VERSION "V5.0.0"

NS_ :

BS_:

BU_: SGW_SG CGW_SG

BO_ 643 DCM_FR: 8 CGW_SG
 SG_ DCM_FR_CarSharingColorSts  : 7|8@0+ (1,0) [0|255] "" SGW_SG
 SG_ DCM_FR_CarSharingTimeSts  : 11|4@0+ (1,0) [0|9] "s" SGW_SG
 SG_ DCM_FR_PowerDoorModeSts  : 13|2@0+ (1,0) [0|3] "" SGW_SG
 SG_ DCM_FR_FrontKeepOpenSts  : 14|1@0+ (1,0) [0|1] "" SGW_SG
 SG_ DCM_FR_PriorSoundSts  : 15|1@0+ (1,0) [0|1] "" SGW_SG
 SG_ DCM_FR_CarSharingLightSts  : 46|1@0+ (1,0) [0|1] "" SGW_SG
 SG_ DCM_FR_WelcomeOnOffSts  : 47|1@0+ (1,0) [0|1] "" SGW_SG
 SG_ DCM_FR_DoorFRLockSts  : 23|1@0+ (1,0) [0|1] "" SGW_SG
 SG_ DCM_FR_DoorFRAngle  : 22|7@0+ (1,0) [0|100] "degrees" SGW_SG
 SG_ DCM_FR_FRPESwitchReq  : 31|1@0+ (1,0) [0|1] "" SGW_SG
 SG_ DCM_FR_DoorAntiPinchSts  : 30|1@0+ (1,0) [0|1] "" SGW_SG
 SG_ DCM_FR_DoorObstacleSts  : 29|1@0+ (1,0) [0|1] "" SGW_SG
 SG_ DCM_FR_ElectricDoorMovementSts  : 28|3@0+ (1,0) [0|7] "" SGW_SG
 SG_ DCM_FR_LinkageAvoidanceReq  : 25|2@0+ (1,0) [0|3] "" SGW_SG
 SG_ DCM_FR_InsideSwitchReq  : 39|1@0+ (1,0) [0|1] "" SGW_SG
 SG_ DCM_FR_WindowSts  : 38|3@0+ (1,0) [0|5] "" SGW_SG
 SG_ DCM_FR_PWM_POS_STS  : 35|3@0+ (1,0) [0|4] "" SGW_SG
 SG_ DCM_FR_GLASS_LOCATION  : 45|5@0+ (1,0) [0|20] "" SGW_SG
 SG_ DCM_FR_FrontDoorAngleFeedback  : 40|1@0+ (1,0) [0|1] "" SGW_SG
 SG_ DCM_FR_FRWindowLockSts  : 55|1@0+ (1,0) [0|1] "" SGW_SG
 SG_ DCM_FR_DoorFRSts  : 54|1@0+ (1,0) [0|1] "" SGW_SG

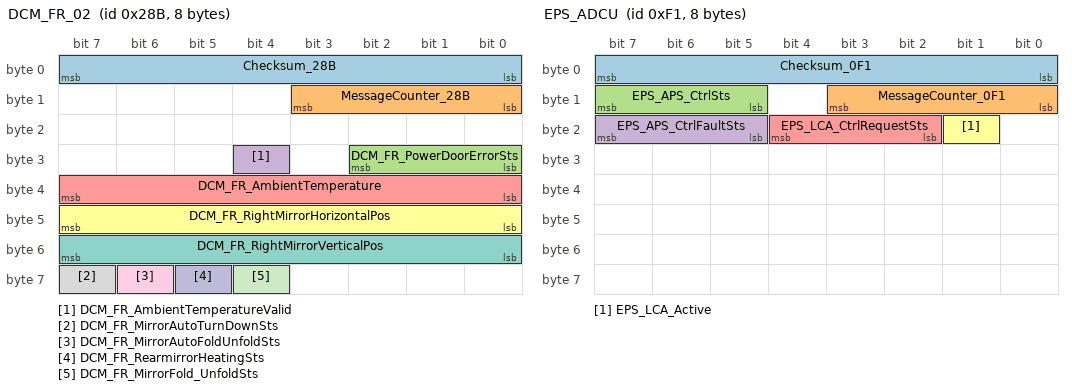
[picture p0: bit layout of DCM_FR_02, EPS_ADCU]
BO_ 651 DCM_FR_02: 8 CGW_SG
 SG_ Checksum_28B  : 7|8@0+ (1,0) [0|255] "" SGW_SG
 SG_ MessageCounter_28B  : 11|4@0+ (1,0) [0|15] "" SGW_SG
 SG_ DCM_FR_PowerDoorErrorSts  : 26|3@0+ (1,0) [0|7] "" SGW_SG
 SG_ DCM_FR_AmbientTemperatureValid  : 28|1@0+ (1,0) [0|1] "" SGW_SG
 SG_ DCM_FR_AmbientTemperature  : 39|8@0+ (1,-50) [-50|205] "celsius" SGW_SG
 SG_ DCM_FR_RightMirrorHorizontalPos  : 47|8@0+ (1,0) [0|100] "percent" SGW_SG
 SG_ DCM_FR_RightMirrorVerticalPos  : 55|8@0+ (1,0) [0|100] "percent" SGW_SG
 SG_ DCM_FR_MirrorAutoTurnDownSts  : 63|1@0+ (1,0) [0|1] "" SGW_SG
 SG_ DCM_FR_MirrorAutoFoldUnfoldSts  : 62|1@0+ (1,0) [0|1] "" SGW_SG
 SG_ DCM_FR_RearmirrorHeatingSts  : 61|1@0+ (1,0) [0|1] "" SGW_SG
 SG_ DCM_FR_MirrorFold_UnfoldSts  : 60|1@0+ (1,0) [0|1] "" SGW_SG

BO_ 653 DCM_FR_03: 8 CGW_SG
 SG_ DCM_FR_MirrorTiltVerticalPos  : 23|8@0+ (1,0) [0|100] "percent" SGW_SG
 SG_ DCM_FR_MirrorTiltHorizontalPos  : 31|8@0+ (1,0) [0|100] "percent" SGW_SG
 SG_ DCM_FR_MirrorMainVerticalPos  : 39|8@0+ (1,0) [0|100] "percent" SGW_SG
 SG_ DCM_FR_MirrorMainHorizontalPos  : 47|8@0+ (1,0) [0|100] "percent" SGW_SG

BO_ 310 DCM_FR_04: 8 CGW_SG
 SG_ DCM_FR_MirrorAdjustmentSts  : 7|1@0+ (1,0) [0|1] "" SGW_SG
 SG_ DCM_FR_MirrorFoldFaultSts  : 6|2@0+ (1,0) [0|3] "" SGW_SG
 SG_ DCM_FR_HandleFailReminder  : 4|2@0+ (1,0) [0|3] "" SGW_SG
 SG_ DCM_FR_PriorSoundReq  : 2|2@0+ (1,0) [0|1] "" SGW_SG

BO_ 644 DCM_RL: 8 CGW_SG
 SG_ Checksum_284  : 7|8@0+ (1,0) [0|255] "" SGW_SG
 SG_ MessageCounter_284  : 11|4@0+ (1,0) [0|15] "" SGW_SG
 SG_ DCM_RL_DoorRLLockSts  : 23|1@0+ (1,0) [0|1] "" SGW_SG
 SG_ DCM_RL_DoorRLAngle  : 22|7@0+ (1,0) [0|100] "degrees" SGW_SG
 SG_ DCM_RL_RLPESwitchReq  : 31|1@0+ (1,0) [0|1] "" SGW_SG
 SG_ DCM_RL_DoorObstacleSts  : 30|1@0+ (1,0) [0|1] "" SGW_SG
 SG_ DCM_RL_DoorAntiPinchSts  : 29|1@0+ (1,0) [0|1] "" SGW_SG
 SG_ DCM_RL_ElectricDoorMovementSts  : 28|3@0+ (1,0) [0|7] "" SGW_SG
 SG_ DCM_RL_LinkageAvoidanceReq  : 25|2@0+ (1,0) [0|3] "" SGW_SG
 SG_ DCM_RL_InsideSwitchReq  : 39|1@0+ (1,0) [0|1] "" SGW_SG
 SG_ DCM_RL_WindowSts  : 38|3@0+ (1,0) [0|5] "" SGW_SG
 SG_ DCM_RL_PWM_POS_STS  : 35|3@0+ (1,0) [0|4] "" SGW_SG
 SG_ DCM_RL_GLASS_LOCATION  : 45|5@0+ (1,0) [0|20] "" SGW_SG
 SG_ DCM_RL_RearDoorAngleFeedback  : 40|1@0+ (1,0) [0|1] "" SGW_SG
 SG_ DCM_RL_RLWindowLockSts  : 55|1@0+ (1,0) [0|1] "" SGW_SG
 SG_ DCM_RL_DoorRLSts  : 54|1@0+ (1,0) [0|1] "" SGW_SG
 SG_ DCM_RL_PowerDoorErrorSts  : 53|3@0+ (1,0) [0|7] "" SGW_SG
 SG_ DCM_RL_PriorSoundSts  : 50|1@0+ (1,0) [0|1] "" SGW_SG
 SG_ DCM_RL_PowerDoorModeSts  : 49|2@0+ (1,0) [0|3] "" SGW_SG
 SG_ DCM_RL_WelcomeOnOffSts  : 47|1@0+ (1,0) [0|1] "" SGW_SG
 SG_ DCM_RL_CarSharingLightSts  : 46|1@0+ (1,0) [0|1] "" SGW_SG
 SG_ DCM_RL_CarSharingColorSts  : 63|8@0+ (1,0) [0|255] "" SGW_SG
 SG_ DCM_RL_CarSharingTimeSts  : 15|4@0+ (1,0) [0|9] "s" SGW_SG

BO_ 311 DCM_RL_02: 8 CGW_SG
 SG_ DCM_RL_PriorSoundReq  : 7|1@0+ (1,0) [0|1] "" SGW_SG

BO_ 645 DCM_RR: 8 CGW_SG
 SG_ Checksum_285  : 7|8@0+ (1,0) [0|255] "" SGW_SG
 SG_ MessageCounter_285  : 11|4@0+ (1,0) [0|15] "" SGW_SG
 SG_ DCM_RR_DoorRRLockSts  : 23|1@0+ (1,0) [0|1] "" SGW_SG
 SG_ DCM_RR_DoorRRAngle  : 22|7@0+ (1,0) [0|100] "degrees" SGW_SG
 SG_ DCM_RR_RRPESwitchReq  : 31|1@0+ (1,0) [0|1] "" SGW_SG
 SG_ DCM_RR_DoorObstacleSts  : 30|1@0+ (1,0) [0|1] "" SGW_SG
 SG_ DCM_RR_DoorAntiPinchSts  : 29|1@0+ (1,0) [0|1] "" SGW_SG
 SG_ DCM_RR_ElectricDoorMovementSts  : 28|3@0+ (1,0) [0|7] "" SGW_SG
 SG_ DCM_RR_LinkageAvoidanceReq  : 25|2@0+ (1,0) [0|3] "" SGW_SG
 SG_ DCM_RR_InsideSwitchReq  : 39|1@0+ (1,0) [0|1] "" SGW_SG
 SG_ DCM_RR_WindowSts  : 38|3@0+ (1,0) [0|5] "" SGW_SG
 SG_ DCM_RR_PWM_POS_STS  : 35|3@0+ (1,0) [0|4] "" SGW_SG
 SG_ DCM_RR_GLASS_LOCATION  : 45|5@0+ (1,0) [0|20] "" SGW_SG
 SG_ DCM_RR_RearDoorAngleFeedback  : 40|1@0+ (1,0) [0|1] "" SGW_SG
 SG_ DCM_RR_RRWindowLockSts  : 55|1@0+ (1,0) [0|1] "" SGW_SG
 SG_ DCM_RR_DoorRRSts  : 54|1@0+ (1,0) [0|1] "" SGW_SG
 SG_ DCM_RR_PowerDoorErrorSts  : 53|3@0+ (1,0) [0|7] "" SGW_SG
 SG_ DCM_RR_PriorSoundSts  : 50|1@0+ (1,0) [0|1] "" SGW_SG
 SG_ DCM_RR_PowerDoorModeSts  : 49|2@0+ (1,0) [0|3] "" SGW_SG
 SG_ DCM_RR_WelcomeOnOffSts  : 47|1@0+ (1,0) [0|1] "" SGW_SG
 SG_ DCM_RR_CarSharingLightSts  : 46|1@0+ (1,0) [0|1] "" SGW_SG
 SG_ DCM_RR_CarSharingColorSts  : 63|8@0+ (1,0) [0|255] "" SGW_SG
 SG_ DCM_RR_CarSharingTimeSts  : 15|4@0+ (1,0) [0|9] "s" SGW_SG

BO_ 312 DCM_RR_02: 8 CGW_SG
 SG_ DCM_RR_PriorSoundReq  : 7|1@0+ (1,0) [0|1] "" SGW_SG

BO_ 880 DCM_FL_SDS_01: 8 CGW_SG
 SG_ DCM_SDS_FL_SensorWorksts  : 15|3@0+ (1,0) [0|5] "" SGW_SG

BO_ 881 DCM_FR_SDS_01: 8 CGW_SG
 SG_ DCM_SDS_FR_SensorWorksts  : 15|3@0+ (1,0) [0|5] "" SGW_SG

BO_ 882 DCM_RL_SDS_01: 8 CGW_SG
 SG_ DCM_SDS_RL_SensorWorksts  : 15|3@0+ (1,0) [0|5] "" SGW_SG

BO_ 883 DCM_RR_SDS_01: 8 CGW_SG
 SG_ DCM_SDS_RR_SensorWorksts  : 15|3@0+ (1,0) [0|5] "" SGW_SG

BO_ 714 DIM_01: 8 CGW_SG
 SG_ DIM_ScreenBrightnessSta  : 7|5@0+ (1,0) [0|31] "" SGW_SG
 SG_ DIM_AutoScreenBacklightSta  : 15|2@0+ (1,0) [0|3] "" SGW_SG
 SG_ DIM_FaultState  : 13|2@0+ (1,0) [0|3] "" SGW_SG
 SG_ DIM_ONOFFSts  : 11|2@0+ (1,0) [0|3] "" SGW_SG

BO_ 512 ERA_01: 8 SGW_SG
 SG_ ERA_ECallSts  : 7|2@0+ (1,0) [0|3] "" CGW_SG
 SG_ ERA_TestModeSts  : 5|2@0+ (1,0) [0|3] "" CGW_SG
 SG_ ERA_SelfTestSts  : 3|1@0+ (1,0) [0|1] "" CGW_SG

BO_ 241 EPS_ADCU: 8 CGW_SG
 SG_ Checksum_0F1  : 7|8@0+ (1,0) [0|255] "" SGW_SG
 SG_ MessageCounter_0F1  : 11|4@0+ (1,0) [0|15] "" SGW_SG
 SG_ EPS_APS_CtrlSts  : 15|3@0+ (1,0) [0|7] "" SGW_SG
 SG_ EPS_APS_CtrlFaultSts  : 23|3@0+ (1,0) [0|7] "" SGW_SG
 SG_ EPS_LCA_CtrlRequestSts  : 20|3@0+ (1,0) [0|7] "" SGW_SG
 SG_ EPS_LCA_Active  : 17|1@0+ (1,0) [0|1] "" SGW_SG

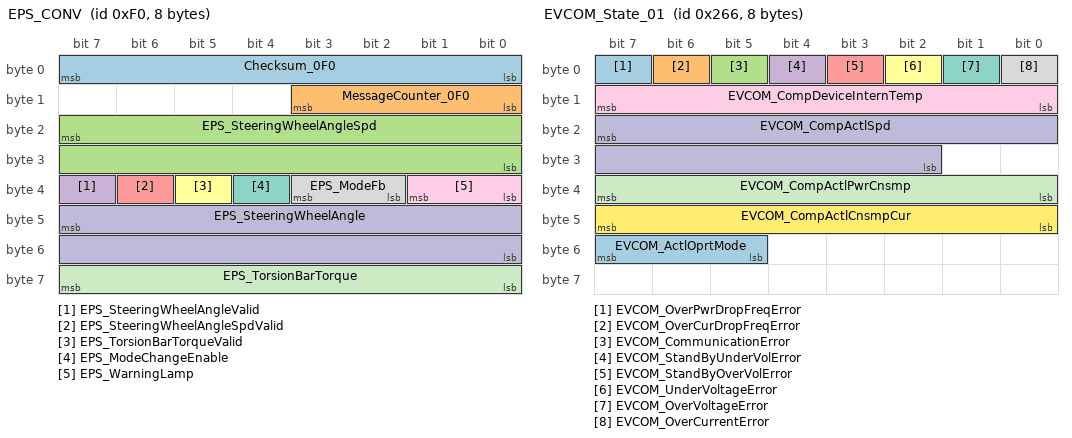
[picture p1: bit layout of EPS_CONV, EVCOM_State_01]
BO_ 240 EPS_CONV: 8 CGW_SG
 SG_ Checksum_0F0  : 7|8@0+ (1,0) [0|255] "" SGW_SG
 SG_ MessageCounter_0F0  : 11|4@0+ (1,0) [0|15] "" SGW_SG
 SG_ EPS_SteeringWheelAngleSpd  : 23|16@0+ (0.1,-540) [-540|540] "degrees/s" SGW_SG
 SG_ EPS_SteeringWheelAngleValid  : 39|1@0+ (1,0) [0|1] "" SGW_SG
 SG_ EPS_SteeringWheelAngleSpdValid  : 38|1@0+ (1,0) [0|1] "" SGW_SG
 SG_ EPS_TorsionBarTorqueValid  : 37|1@0+ (1,0) [0|1] "" SGW_SG
 SG_ EPS_ModeChangeEnable  : 36|1@0+ (1,0) [0|1] "" SGW_SG
 SG_ EPS_ModeFb  : 35|2@0+ (1,0) [0|3] "" SGW_SG
 SG_ EPS_WarningLamp  : 33|2@0+ (1,0) [0|3] "" SGW_SG
 SG_ EPS_SteeringWheelAngle  : 47|16@0+ (0.1,-780) [-780|780] "degrees" SGW_SG
 SG_ EPS_TorsionBarTorque  : 63|8@0+ (0.1,-10) [-10|10] "Nm" SGW_SG

BO_ 614 EVCOM_State_01: 8 CGW_SG
 SG_ EVCOM_OverPwrDropFreqError  : 7|1@0+ (1,0) [0|1] "" SGW_SG
 SG_ EVCOM_OverCurDropFreqError  : 6|1@0+ (1,0) [0|1] "" SGW_SG
 SG_ EVCOM_CommunicationError  : 5|1@0+ (1,0) [0|1] "" SGW_SG
 SG_ EVCOM_StandByUnderVolError  : 4|1@0+ (1,0) [0|1] "" SGW_SG
 SG_ EVCOM_StandByOverVolError  : 3|1@0+ (1,0) [0|1] "" SGW_SG
 SG_ EVCOM_UnderVoltageError  : 2|1@0+ (1,0) [0|1] "" SGW_SG
 SG_ EVCOM_OverVoltageError  : 1|1@0+ (1,0) [0|1] "" SGW_SG
 SG_ EVCOM_OverCurrentError  : 0|1@0+ (1,0) [0|1] "" SGW_SG
 SG_ EVCOM_CompDeviceInternTemp  : 15|8@0+ (1,-40) [-40|215] "celsius" SGW_SG
 SG_ EVCOM_CompActlSpd  : 23|14@0+ (1,0) [0|9200] "rpm" SGW_SG
 SG_ EVCOM_CompActlPwrCnsmp  : 39|8@0+ (0.04,0) [0|10.2] "KW" SGW_SG
 SG_ EVCOM_CompActlCnsmpCur  : 47|8@0+ (0.2,0) [0|51] "A" SGW_SG
 SG_ EVCOM_ActlOprtMode  : 55|3@0+ (1,0) [0|7] "" SGW_SG

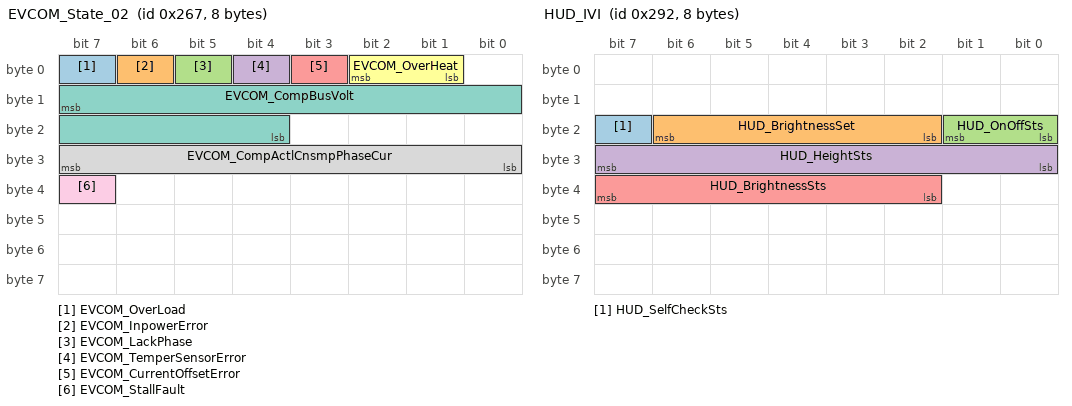
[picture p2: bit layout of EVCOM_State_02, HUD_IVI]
BO_ 615 EVCOM_State_02: 8 CGW_SG
 SG_ EVCOM_OverLoad  : 7|1@0+ (1,0) [0|1] "" SGW_SG
 SG_ EVCOM_InpowerError  : 6|1@0+ (1,0) [0|1] "" SGW_SG
 SG_ EVCOM_LackPhase  : 5|1@0+ (1,0) [0|1] "" SGW_SG
 SG_ EVCOM_TemperSensorError  : 4|1@0+ (1,0) [0|1] "" SGW_SG
 SG_ EVCOM_CurrentOffsetError  : 3|1@0+ (1,0) [0|1] "" SGW_SG
 SG_ EVCOM_OverHeat  : 2|2@0+ (1,0) [0|3] "" SGW_SG
 SG_ EVCOM_CompBusVolt  : 15|12@0+ (2,0) [0|1022] "V" SGW_SG
 SG_ EVCOM_CompActlCnsmpPhaseCur  : 31|8@0+ (0.2,0) [0|51] "A" SGW_SG
 SG_ EVCOM_StallFault  : 39|1@0+ (1,0) [0|1] "" SGW_SG

BO_ 640 HLL: 8 CGW_SG
 SG_ Checksum_280  : 7|8@0+ (1,0) [0|255] "" SGW_SG
 SG_ MessageCounter_280  : 11|4@0+ (1,0) [0|15] "" SGW_SG
 SG_ HLL_HeadlampFault  : 19|1@0+ (1,0) [0|1] "" SGW_SG
 SG_ HLL_DRLFaultSts  : 16|1@0+ (1,0) [0|1] "" SGW_SG

BO_ 641 HLR: 8 CGW_SG
 SG_ Checksum_281  : 7|8@0+ (1,0) [0|255] "" SGW_SG
 SG_ MessageCounter_281  : 11|4@0+ (1,0) [0|15] "" SGW_SG
 SG_ HLR_HeadlampFault  : 19|1@0+ (1,0) [0|1] "" SGW_SG
 SG_ HLR_DRLFaultSts  : 16|1@0+ (1,0) [0|1] "" SGW_SG

BO_ 660 HOD_heating_01: 8 CGW_SG
 SG_ HOD_Heating_SteerWhHeatSts  : 7|1@0+ (1,0) [0|1] "" SGW_SG

BO_ 658 HUD_IVI: 8 CGW_SG
 SG_ HUD_SelfCheckSts  : 23|1@0+ (1,0) [0|1] "" SGW_SG
 SG_ HUD_BrightnessSet  : 22|5@0+ (1,0) [0|31] "" SGW_SG
 SG_ HUD_OnOffSts  : 17|2@0+ (1,0) [0|3] "" SGW_SG
 SG_ HUD_HeightSts  : 31|8@0+ (1,0) [0|255] "" SGW_SG
 SG_ HUD_BrightnessSts  : 39|6@0+ (1,0) [0|50] "" SGW_SG

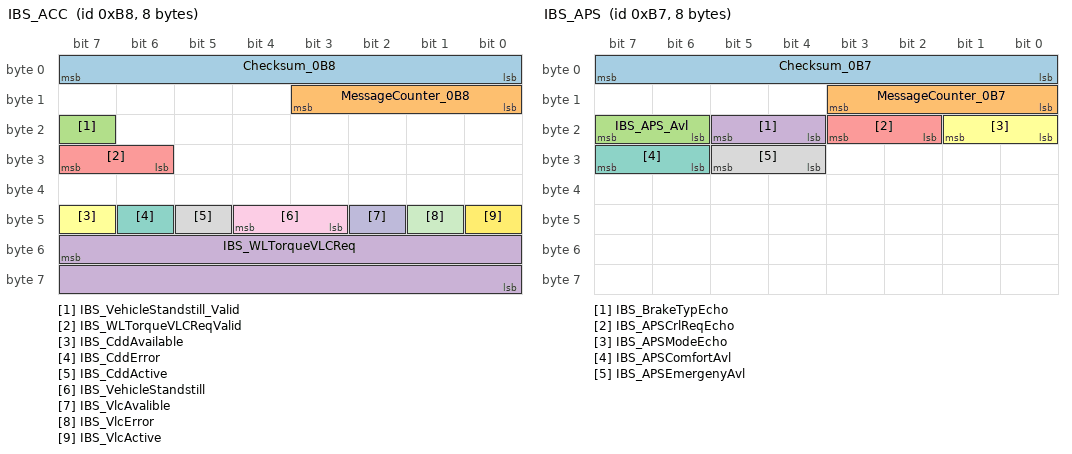
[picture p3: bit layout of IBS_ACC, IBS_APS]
BO_ 184 IBS_ACC: 8 CGW_SG
 SG_ Checksum_0B8  : 7|8@0+ (1,0) [0|255] "" SGW_SG
 SG_ MessageCounter_0B8  : 11|4@0+ (1,0) [0|15] "" SGW_SG
 SG_ IBS_VehicleStandstill_Valid  : 23|1@0+ (1,0) [0|1] "" SGW_SG
 SG_ IBS_WLTorqueVLCReq  : 55|16@0+ (1,-20000) [-20000|20000] "Nm" SGW_SG
 SG_ IBS_WLTorqueVLCReqValid  : 31|2@0+ (1,0) [0|2] "" SGW_SG
 SG_ IBS_CddAvailable  : 47|1@0+ (1,0) [0|1] "" SGW_SG
 SG_ IBS_CddError  : 46|1@0+ (1,0) [0|1] "" SGW_SG
 SG_ IBS_CddActive  : 45|1@0+ (1,0) [0|1] "" SGW_SG
 SG_ IBS_VehicleStandstill  : 44|2@0+ (1,0) [0|2] "" SGW_SG
 SG_ IBS_VlcAvalible  : 42|1@0+ (1,0) [0|1] "" SGW_SG
 SG_ IBS_VlcError  : 41|1@0+ (1,0) [0|1] "" SGW_SG
 SG_ IBS_VlcActive  : 40|1@0+ (1,0) [0|1] "" SGW_SG

BO_ 183 IBS_APS: 8 CGW_SG
 SG_ Checksum_0B7  : 7|8@0+ (1,0) [0|255] "" SGW_SG
 SG_ MessageCounter_0B7  : 11|4@0+ (1,0) [0|15] "" SGW_SG
 SG_ IBS_APS_Avl  : 23|2@0+ (1,0) [0|3] "" SGW_SG
 SG_ IBS_BrakeTypEcho  : 21|2@0+ (1,0) [0|3] "" SGW_SG
 SG_ IBS_APSCrlReqEcho  : 19|2@0+ (1,0) [0|3] "" SGW_SG
 SG_ IBS_APSModeEcho  : 17|2@0+ (1,0) [0|3] "" SGW_SG
 SG_ IBS_APSComfortAvl  : 31|2@0+ (1,0) [0|3] "" SGW_SG
 SG_ IBS_APSEmergenyAvl  : 29|2@0+ (1,0) [0|3] "" SGW_SG

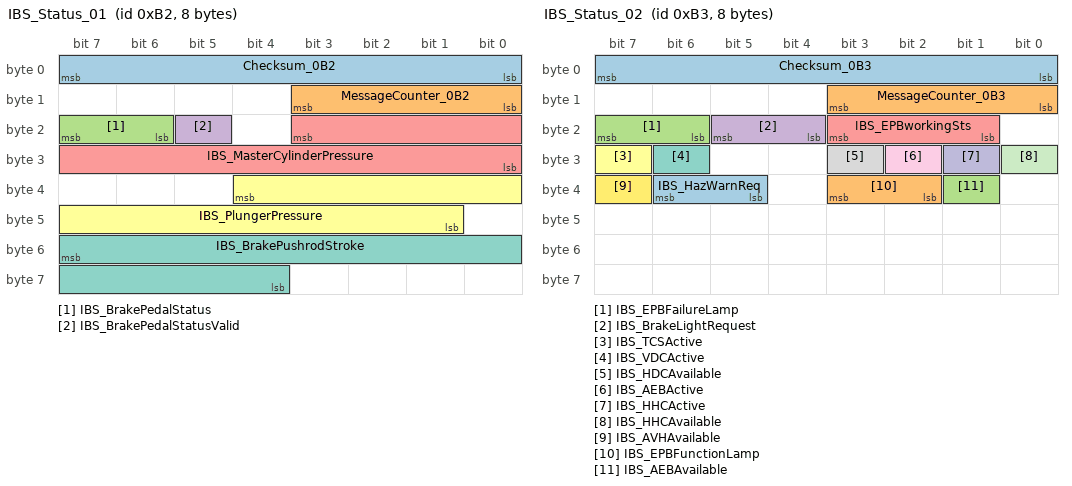
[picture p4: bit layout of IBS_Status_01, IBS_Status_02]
BO_ 178 IBS_Status_01: 8 CGW_SG
 SG_ Checksum_0B2  : 7|8@0+ (1,0) [0|255] "" SGW_SG
 SG_ MessageCounter_0B2  : 11|4@0+ (1,0) [0|15] "" SGW_SG
 SG_ IBS_BrakePedalStatus  : 23|2@0+ (1,0) [0|3] "" SGW_SG
 SG_ IBS_BrakePedalStatusValid  : 21|1@0+ (1,0) [0|1] "" SGW_SG
 SG_ IBS_MasterCylinderPressure  : 19|12@0+ (0.1,0) [0|250] "BAR" SGW_SG
 SG_ IBS_PlungerPressure  : 36|12@0+ (0.1,-5) [-5|250] "BAR" SGW_SG
 SG_ IBS_BrakePushrodStroke  : 55|12@0+ (0.015625,-5) [-5|47] "mm" SGW_SG

BO_ 179 IBS_Status_02: 8 CGW_SG
 SG_ Checksum_0B3  : 7|8@0+ (1,0) [0|255] "" SGW_SG
 SG_ MessageCounter_0B3  : 11|4@0+ (1,0) [0|15] "" SGW_SG
 SG_ IBS_EPBFailureLamp  : 23|2@0+ (1,0) [0|1] "" SGW_SG
 SG_ IBS_BrakeLightRequest  : 21|2@0+ (1,0) [0|3] "" SGW_SG
 SG_ IBS_EPBworkingSts  : 19|3@0+ (1,0) [0|7] "" SGW_SG
 SG_ IBS_TCSActive  : 31|1@0+ (1,0) [0|1] "" SGW_SG
 SG_ IBS_VDCActive  : 30|1@0+ (1,0) [0|1] "" SGW_SG
 SG_ IBS_HDCAvailable  : 27|1@0+ (1,0) [0|1] "" SGW_SG
 SG_ IBS_AEBActive  : 26|1@0+ (1,0) [0|1] "" SGW_SG
 SG_ IBS_HHCActive  : 25|1@0+ (1,0) [0|1] "" SGW_SG
 SG_ IBS_HHCAvailable  : 24|1@0+ (1,0) [0|1] "" SGW_SG
 SG_ IBS_AVHAvailable  : 39|1@0+ (1,0) [0|1] "" SGW_SG
 SG_ IBS_HazWarnReq  : 38|2@0+ (1,0) [0|2] "" SGW_SG
 SG_ IBS_EPBFunctionLamp  : 35|2@0+ (1,0) [0|3] "" SGW_SG
 SG_ IBS_AEBAvailable  : 33|1@0+ (1,0) [0|1] "" SGW_SG

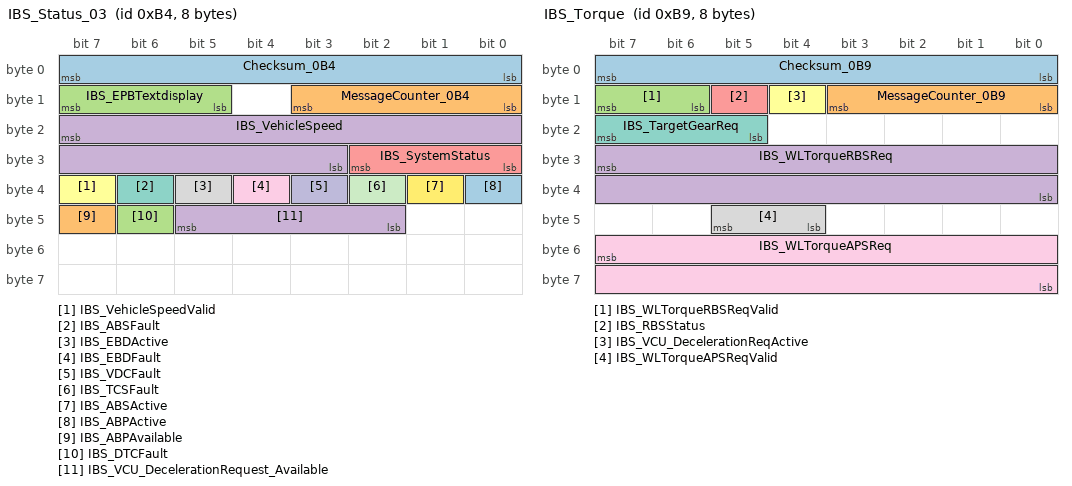
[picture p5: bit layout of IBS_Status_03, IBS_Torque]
BO_ 180 IBS_Status_03: 8 CGW_SG
 SG_ Checksum_0B4  : 7|8@0+ (1,0) [0|255] "" SGW_SG
 SG_ MessageCounter_0B4  : 11|4@0+ (1,0) [0|15] "" SGW_SG
 SG_ IBS_EPBTextdisplay  : 15|3@0+ (1,0) [0|4] "" SGW_SG
 SG_ IBS_VehicleSpeed  : 23|13@0+ (0.05625,0) [0|360] "km/h" SGW_SG
 SG_ IBS_SystemStatus  : 26|3@0+ (1,0) [0|7] "" SGW_SG
 SG_ IBS_VehicleSpeedValid  : 39|1@0+ (1,0) [0|1] "" SGW_SG
 SG_ IBS_ABSFault  : 38|1@0+ (1,0) [0|1] "" SGW_SG
 SG_ IBS_EBDActive  : 37|1@0+ (1,0) [0|1] "" SGW_SG
 SG_ IBS_EBDFault  : 36|1@0+ (1,0) [0|1] "" SGW_SG
 SG_ IBS_VDCFault  : 35|1@0+ (1,0) [0|1] "" SGW_SG
 SG_ IBS_TCSFault  : 34|1@0+ (1,0) [0|1] "" SGW_SG
 SG_ IBS_ABSActive  : 33|1@0+ (1,0) [0|1] "" SGW_SG
 SG_ IBS_ABPActive  : 32|1@0+ (1,0) [0|1] "" SGW_SG
 SG_ IBS_ABPAvailable  : 47|1@0+ (1,0) [0|1] "" SGW_SG
 SG_ IBS_DTCFault  : 46|1@0+ (1,0) [0|1] "" SGW_SG
 SG_ IBS_VCU_DecelerationRequest_Available  : 45|4@0+ (1,0) [0|3] "" SGW_SG

BO_ 186 IBS_Status_04: 8 CGW_SG
 SG_ Checksum_0BA  : 7|8@0+ (1,0) [0|255] "" SGW_SG
 SG_ MessageCounter_0BA  : 11|4@0+ (1,0) [0|15] "" SGW_SG
 SG_ IBS_CDPActive  : 23|1@0+ (1,0) [0|1] "" SGW_SG

BO_ 187 IBS_Status_05: 8 CGW_SG
 SG_ Checksum_0BB  : 7|8@0+ (1,0) [0|255] "" SGW_SG
 SG_ MessageCounter_0BB  : 11|4@0+ (1,0) [0|15] "" SGW_SG
 SG_ IBS_SUBEPBworkingSts  : 21|3@0+ (1,0) [0|7] "" SGW_SG
 SG_ IBS_SUBEPBFailureStatus  : 23|2@0+ (1,0) [0|3] "" SGW_SG

BO_ 188 IBS_Status_06: 8 CGW_SG
 SG_ Checksum_0BC  : 7|8@0+ (1,0) [0|255] "" SGW_SG
 SG_ MessageCounter_0BC  : 11|4@0+ (1,0) [0|15] "" SGW_SG
 SG_ IBS_HBAActive  : 46|1@0+ (1,0) [0|1] "" SGW_SG
 SG_ IBS_ESCOffSts  : 45|1@0+ (1,0) [0|1] "" SGW_SG
 SG_ IBS_RWUActive  : 44|1@0+ (1,0) [0|1] "" SGW_SG
 SG_ IBS_RWUAvailable  : 43|1@0+ (1,0) [0|1] "" SGW_SG
 SG_ IBS_MaintenaceMode  : 42|1@0+ (1,0) [0|1] "" SGW_SG
 SG_ IBS_RollerbenchMode  : 41|1@0+ (1,0) [0|1] "" SGW_SG
 SG_ IBS_FactoryMode  : 40|1@0+ (1,0) [0|1] "" SGW_SG
 SG_ IBS_AVHSts  : 55|2@0+ (1,0) [0|2] "" SGW_SG
 SG_ IBS_ESClampdisplay  : 53|2@0+ (1,0) [0|2] "" SGW_SG
 SG_ IBS_HDCSts  : 51|2@0+ (1,0) [0|2] "" SGW_SG
 SG_ IBS_BrakeFluidWarning  : 49|2@0+ (1,0) [0|3] "" SGW_SG
 SG_ IBS_EPBFailureStatus  : 63|2@0+ (1,0) [0|3] "" SGW_SG
 SG_ IBS_TireMonSysSts  : 61|1@0+ (1,0) [0|1] "" SGW_SG
 SG_ IBS_TPMS_ResetSts  : 60|1@0+ (1,0) [0|1] "" SGW_SG
 SG_ IBS_TireWarnReLe  : 59|1@0+ (1,0) [0|1] "" SGW_SG
 SG_ IBS_TireWarnReRi  : 58|1@0+ (1,0) [0|1] "" SGW_SG
 SG_ IBS_TireWarnFrntLe  : 57|1@0+ (1,0) [0|1] "" SGW_SG
 SG_ IBS_TireWarnFrntRi  : 56|1@0+ (1,0) [0|1] "" SGW_SG

BO_ 185 IBS_Torque: 8 CGW_SG
 SG_ Checksum_0B9  : 7|8@0+ (1,0) [0|255] "" SGW_SG
 SG_ MessageCounter_0B9  : 11|4@0+ (1,0) [0|15] "" SGW_SG
 SG_ IBS_WLTorqueRBSReqValid  : 15|2@0+ (1,0) [0|2] "" SGW_SG
 SG_ IBS_WLTorqueRBSReq  : 31|16@0+ (1,-20000) [-20000|20000] "Nm" SGW_SG
 SG_ IBS_RBSStatus  : 13|1@0+ (1,0) [0|1] "" SGW_SG
 SG_ IBS_VCU_DecelerationReqActive  : 12|1@0+ (1,0) [0|1] "" SGW_SG
 SG_ IBS_TargetGearReq  : 23|3@0+ (1,0) [0|4] "" SGW_SG
 SG_ IBS_WLTorqueAPSReqValid  : 45|2@0+ (1,0) [0|2] "" SGW_SG
 SG_ IBS_WLTorqueAPSReq  : 55|16@0+ (1,-20000) [-20000|20000] "Nm" SGW_SG

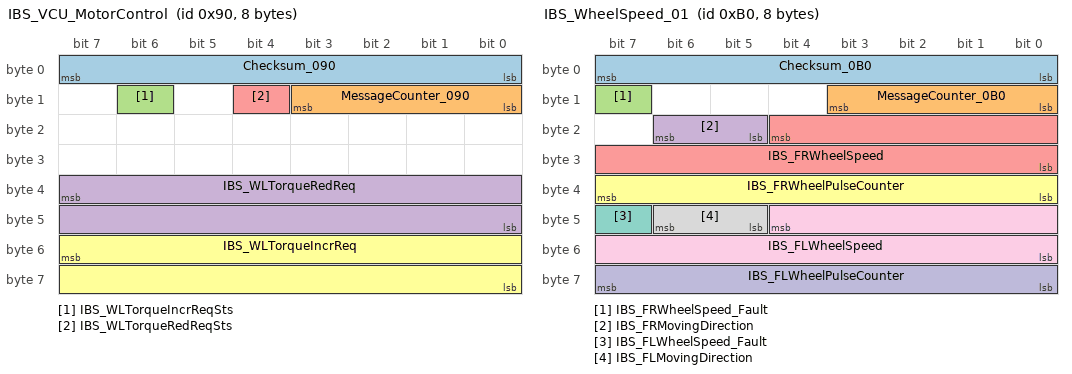
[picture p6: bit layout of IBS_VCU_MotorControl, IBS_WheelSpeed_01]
BO_ 144 IBS_VCU_MotorControl: 8 CGW_SG
 SG_ Checksum_090  : 7|8@0+ (1,0) [0|255] "" SGW_SG
 SG_ MessageCounter_090  : 11|4@0+ (1,0) [0|15] "" SGW_SG
 SG_ IBS_WLTorqueIncrReqSts  : 14|1@0+ (1,0) [0|1] "" SGW_SG
 SG_ IBS_WLTorqueRedReq  : 39|16@0+ (1,-20000) [-20000|20000] "Nm" SGW_SG
 SG_ IBS_WLTorqueRedReqSts  : 12|1@0+ (1,0) [0|1] "" SGW_SG
 SG_ IBS_WLTorqueIncrReq  : 55|16@0+ (1,-20000) [-20000|20000] "Nm" SGW_SG

BO_ 176 IBS_WheelSpeed_01: 8 CGW_SG
 SG_ Checksum_0B0  : 7|8@0+ (1,0) [0|255] "" SGW_SG
 SG_ MessageCounter_0B0  : 11|4@0+ (1,0) [0|15] "" SGW_SG
 SG_ IBS_FRWheelSpeed_Fault  : 15|1@0+ (1,0) [0|1] "" SGW_SG
 SG_ IBS_FRMovingDirection  : 22|2@0+ (1,0) [0|2] "" SGW_SG
 SG_ IBS_FRWheelSpeed  : 20|13@0+ (0.05625,0) [0|360] "km/h" SGW_SG
 SG_ IBS_FRWheelPulseCounter  : 39|8@0+ (1,0) [0|255] "" SGW_SG
 SG_ IBS_FLWheelSpeed_Fault  : 47|1@0+ (1,0) [0|1] "" SGW_SG
 SG_ IBS_FLMovingDirection  : 46|2@0+ (1,0) [0|2] "" SGW_SG
 SG_ IBS_FLWheelSpeed  : 44|13@0+ (0.05625,0) [0|360] "km/h" SGW_SG
 SG_ IBS_FLWheelPulseCounter  : 63|8@0+ (1,0) [0|255] "" SGW_SG

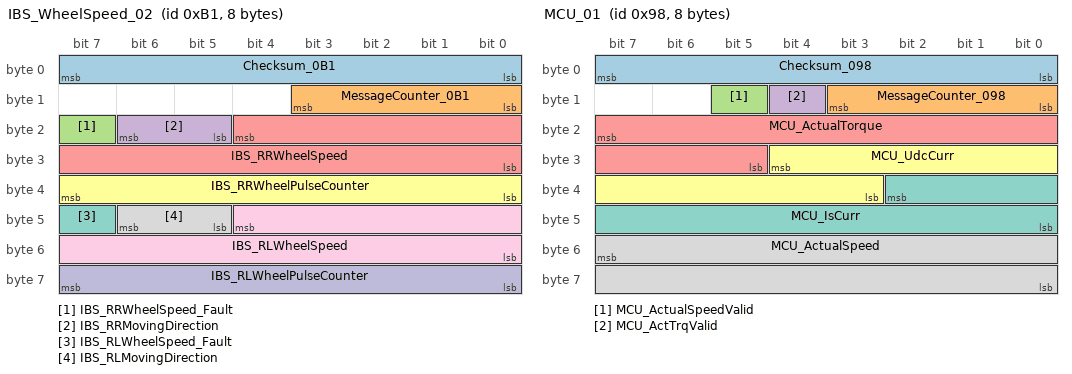
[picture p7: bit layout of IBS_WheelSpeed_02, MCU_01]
BO_ 177 IBS_WheelSpeed_02: 8 CGW_SG
 SG_ Checksum_0B1  : 7|8@0+ (1,0) [0|255] "" SGW_SG
 SG_ MessageCounter_0B1  : 11|4@0+ (1,0) [0|15] "" SGW_SG
 SG_ IBS_RRWheelSpeed_Fault  : 23|1@0+ (1,0) [0|1] "" SGW_SG
 SG_ IBS_RRMovingDirection  : 22|2@0+ (1,0) [0|2] "" SGW_SG
 SG_ IBS_RRWheelSpeed  : 20|13@0+ (0.05625,0) [0|360] "km/h" SGW_SG
 SG_ IBS_RRWheelPulseCounter  : 39|8@0+ (1,0) [0|255] "" SGW_SG
 SG_ IBS_RLWheelSpeed_Fault  : 47|1@0+ (1,0) [0|1] "" SGW_SG
 SG_ IBS_RLMovingDirection  : 46|2@0+ (1,0) [0|2] "" SGW_SG
 SG_ IBS_RLWheelSpeed  : 44|13@0+ (0.05625,0) [0|360] "km/h" SGW_SG
 SG_ IBS_RLWheelPulseCounter  : 63|8@0+ (1,0) [0|255] "" SGW_SG

BO_ 152 MCU_01: 8 CGW_SG
 SG_ Checksum_098  : 7|8@0+ (1,0) [0|255] "" SGW_SG
 SG_ MessageCounter_098  : 11|4@0+ (1,0) [0|15] "" SGW_SG
 SG_ MCU_ActualSpeedValid  : 13|1@0+ (1,0) [0|1] "" SGW_SG
 SG_ MCU_ActTrqValid  : 12|1@0+ (1,0) [0|1] "" SGW_SG
 SG_ MCU_ActualTorque  : 23|11@0+ (1,-1023) [-1023|1023] "" SGW_SG
 SG_ MCU_UdcCurr  : 28|10@0+ (1,0) [0|1021] "" SGW_SG
 SG_ MCU_IsCurr  : 34|11@0+ (1,-1023) [-1023|1023] "" SGW_SG
 SG_ MCU_ActualSpeed  : 55|16@0+ (1,-32767) [-32767|32767] "" SGW_SG

BO_ 243 MCU_02: 8 CGW_SG
 SG_ MCU_VCUWorkMode  : 63|4@0+ (1,0) [0|8] "" SGW_SG

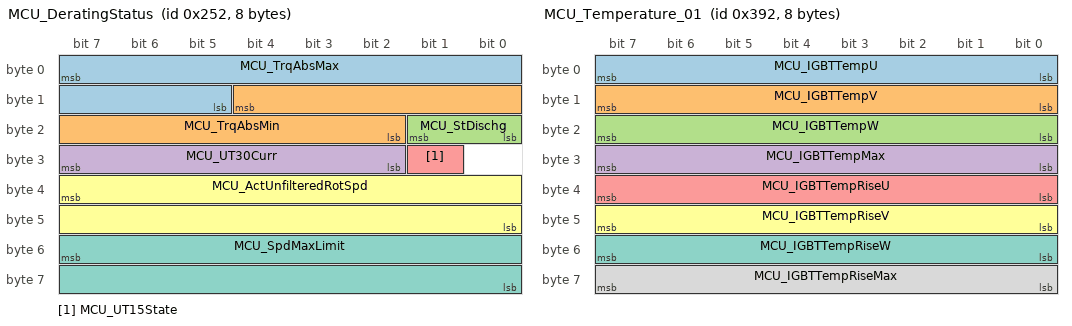
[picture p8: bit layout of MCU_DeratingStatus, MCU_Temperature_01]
BO_ 594 MCU_DeratingStatus: 8 CGW_SG
 SG_ MCU_TrqAbsMax  : 7|11@0+ (1,-1023) [-1023|1023] "" SGW_SG
 SG_ MCU_TrqAbsMin  : 12|11@0+ (1,-1023) [-1023|1023] "" SGW_SG
 SG_ MCU_StDischg  : 17|2@0+ (1,0) [0|3] "" SGW_SG
 SG_ MCU_UT30Curr  : 31|6@0+ (0.5,0) [0|31] "V" SGW_SG
 SG_ MCU_UT15State  : 25|1@0+ (1,0) [0|1] "" SGW_SG
 SG_ MCU_ActUnfilteredRotSpd  : 39|16@0+ (1,-32767) [-32767|32767] "" SGW_SG
 SG_ MCU_SpdMaxLimit  : 55|16@0+ (1,-32767) [-32767|32767] "" SGW_SG

BO_ 595 MCU_FailureCode: 8 CGW_SG
 SG_ Checksum_253  : 7|8@0+ (1,0) [0|255] "" SGW_SG
 SG_ MessageCounter_253  : 11|4@0+ (1,0) [0|15] "" SGW_SG
 SG_ MCU_FaultLevel  : 26|3@0+ (1,0) [0|7] "" SGW_SG

BO_ 929 MCU_HardwareNumber: 8 CGW_SG
 SG_ MCU_HwVer  : 7|16@0+ (1,0) [0|65535] "" SGW_SG

BO_ 928 MCU_SoftwareNumber: 8 CGW_SG
 SG_ MCU_CodeVer  : 7|16@0+ (1,0) [0|65535] "" SGW_SG
 SG_ MCU_DataVer  : 23|16@0+ (1,0) [0|65535] "" SGW_SG
 SG_ MCU_CpldVer  : 39|16@0+ (1,0) [0|65535] "" SGW_SG
 SG_ MCU_HvMcuVer  : 55|16@0+ (1,0) [0|65535] "" SGW_SG

BO_ 914 MCU_Temperature_01: 8 CGW_SG
 SG_ MCU_IGBTTempU  : 7|8@0+ (1,-50) [-50|200] "" SGW_SG
 SG_ MCU_IGBTTempV  : 15|8@0+ (1,-50) [-50|200] "" SGW_SG
 SG_ MCU_IGBTTempW  : 23|8@0+ (1,-50) [-50|200] "" SGW_SG
 SG_ MCU_IGBTTempMax  : 31|8@0+ (1,-50) [-50|200] "" SGW_SG
 SG_ MCU_IGBTTempRiseU  : 39|8@0+ (1,0) [0|200] "" SGW_SG
 SG_ MCU_IGBTTempRiseV  : 47|8@0+ (1,0) [0|200] "" SGW_SG
 SG_ MCU_IGBTTempRiseW  : 55|8@0+ (1,0) [0|200] "" SGW_SG
 SG_ MCU_IGBTTempRiseMax  : 63|8@0+ (1,0) [0|200] "" SGW_SG

BO_ 915 MCU_Temperature_02: 8 CGW_SG
 SG_ MCU_TempCurrCool  : 7|8@0+ (1,-50) [-50|200] "" SGW_SG
 SG_ MCU_TempCurrStr1  : 15|8@0+ (1,-50) [-50|200] "" SGW_SG
 SG_ MCU_TempCurrStr2  : 23|8@0+ (1,-50) [-50|200] "" SGW_SG
 SG_ MCU_TempCurrStrMax  : 31|8@0+ (1,-50) [-50|200] "" SGW_SG
 SG_ MCU_TempRiseCurrStr  : 39|8@0+ (1,0) [0|250] "" SGW_SG
 SG_ MCU_TempStatus  : 47|2@0+ (1,0) [0|3] "" SGW_SG

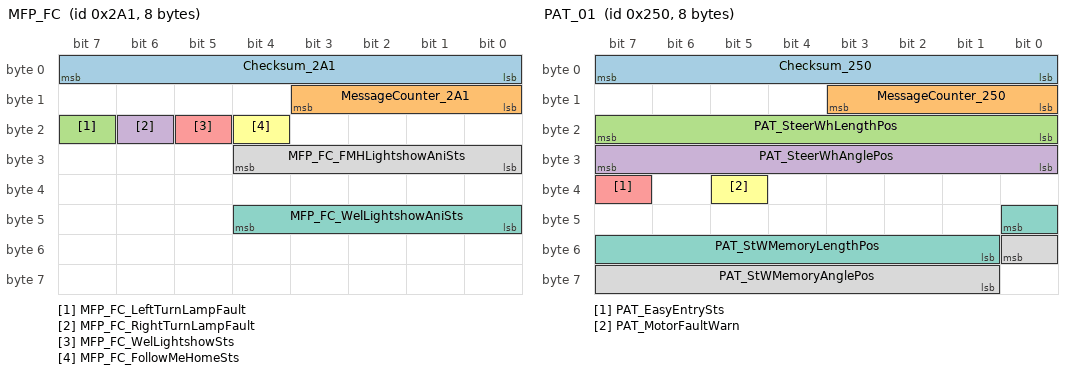
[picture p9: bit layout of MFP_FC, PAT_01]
BO_ 673 MFP_FC: 8 CGW_SG
 SG_ Checksum_2A1  : 7|8@0+ (1,0) [0|255] "" SGW_SG
 SG_ MessageCounter_2A1  : 11|4@0+ (1,0) [0|15] "" SGW_SG
 SG_ MFP_FC_LeftTurnLampFault  : 23|1@0+ (1,0) [0|1] "" SGW_SG
 SG_ MFP_FC_RightTurnLampFault  : 22|1@0+ (1,0) [0|1] "" SGW_SG
 SG_ MFP_FC_WelLightshowSts  : 21|1@0+ (1,0) [0|1] "" SGW_SG
 SG_ MFP_FC_FollowMeHomeSts  : 20|1@0+ (1,0) [0|1] "" SGW_SG
 SG_ MFP_FC_WelLightshowAniSts  : 44|5@0+ (1,0) [0|25] "" SGW_SG
 SG_ MFP_FC_FMHLightshowAniSts  : 28|5@0+ (1,0) [0|25] "" SGW_SG

BO_ 592 PAT_01: 8 CGW_SG
 SG_ Checksum_250  : 7|8@0+ (1,0) [0|255] "" SGW_SG
 SG_ MessageCounter_250  : 11|4@0+ (1,0) [0|15] "" SGW_SG
 SG_ PAT_SteerWhLengthPos  : 23|8@0+ (1,-100) [-100|100] "percent" SGW_SG
 SG_ PAT_SteerWhAnglePos  : 31|8@0+ (1,-100) [-100|100] "percent" SGW_SG
 SG_ PAT_EasyEntrySts  : 39|1@0+ (1,0) [0|1] "" SGW_SG
 SG_ PAT_MotorFaultWarn  : 37|1@0+ (1,0) [0|1] "" SGW_SG
 SG_ PAT_StWMemoryLengthPos  : 40|8@0+ (1,-100) [-100|100] "percent" SGW_SG
 SG_ PAT_StWMemoryAnglePos  : 48|8@0+ (1,-100) [-100|100] "percent" SGW_SG

BO_ 578 POD_DCDC_01: 8 CGW_SG
 SG_ POD_DCDC_HVInputVoltage  : 9|13@0+ (0.1,0) [0|800] "V" SGW_SG
 SG_ POD_DCDC_WorkMode  : 28|3@0+ (1,0) [0|4] "" SGW_SG
 SG_ POD_DCDC_LVOutputCurrent  : 39|12@0+ (0.1,0) [0|400] "A" SGW_SG
 SG_ POD_DCDC_HVInputCurrent  : 55|8@0+ (0.1,0) [0|25.5] "A" SGW_SG
 SG_ POD_DCDC_LVOutputVoltage  : 63|8@0+ (0.1,0) [0|25.5] "V" SGW_SG

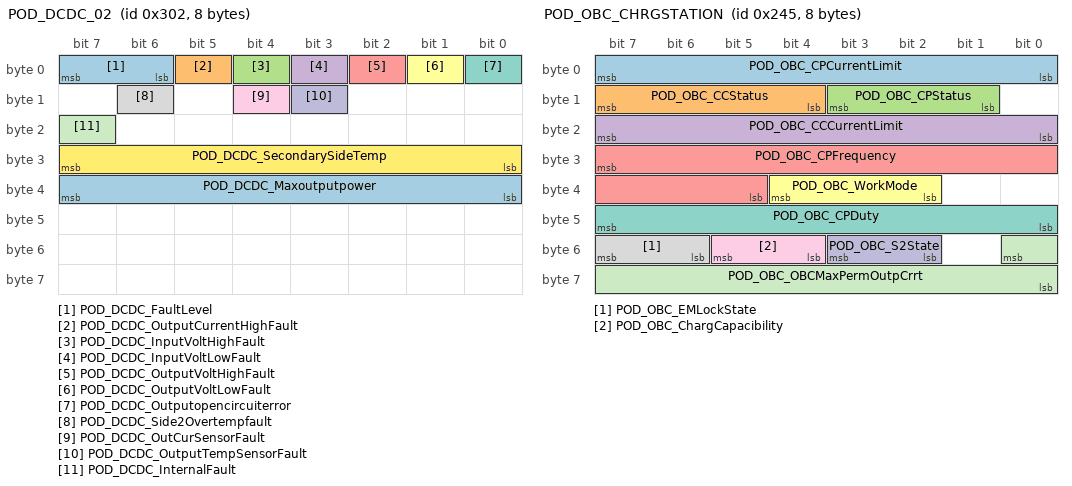
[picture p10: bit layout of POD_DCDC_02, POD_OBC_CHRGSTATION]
BO_ 770 POD_DCDC_02: 8 CGW_SG
 SG_ POD_DCDC_FaultLevel  : 7|2@0+ (1,0) [0|3] "" SGW_SG
 SG_ POD_DCDC_OutputCurrentHighFault  : 5|1@0+ (1,0) [0|1] "" SGW_SG
 SG_ POD_DCDC_InputVoltHighFault  : 4|1@0+ (1,0) [0|1] "" SGW_SG
 SG_ POD_DCDC_InputVoltLowFault  : 3|1@0+ (1,0) [0|1] "" SGW_SG
 SG_ POD_DCDC_OutputVoltHighFault  : 2|1@0+ (1,0) [0|1] "" SGW_SG
 SG_ POD_DCDC_OutputVoltLowFault  : 1|1@0+ (1,0) [0|1] "" SGW_SG
 SG_ POD_DCDC_Outputopencircuiterror  : 0|1@0+ (1,0) [0|1] "" SGW_SG
 SG_ POD_DCDC_Side2Overtempfault  : 14|1@0+ (1,0) [0|1] "" SGW_SG
 SG_ POD_DCDC_OutCurSensorFault  : 12|1@0+ (1,0) [0|1] "" SGW_SG
 SG_ POD_DCDC_OutputTempSensorFault  : 11|1@0+ (1,0) [0|1] "" SGW_SG
 SG_ POD_DCDC_InternalFault  : 23|1@0+ (1,0) [0|1] "" SGW_SG
 SG_ POD_DCDC_SecondarySideTemp  : 31|8@0+ (1,-40) [-40|215] "celsius" SGW_SG
 SG_ POD_DCDC_Maxoutputpower  : 39|8@0+ (0.02,0) [0|5.1] "kW" SGW_SG

BO_ 581 POD_OBC_CHRGSTATION: 8 CGW_SG
 SG_ POD_OBC_CPCurrentLimit  : 7|8@0+ (0.126,0) [0|32.13] "A" SGW_SG
 SG_ POD_OBC_CCStatus  : 15|4@0+ (1,0) [0|10] "" SGW_SG
 SG_ POD_OBC_CPStatus  : 11|3@0+ (1,0) [0|7] "" SGW_SG
 SG_ POD_OBC_CCCurrentLimit  : 23|8@0+ (0.126,0) [0|32.13] "A" SGW_SG
 SG_ POD_OBC_CPFrequency  : 31|11@0+ (1,0) [0|2000] "Hz" SGW_SG
 SG_ POD_OBC_WorkMode  : 36|3@0+ (1,0) [0|7] "" SGW_SG
 SG_ POD_OBC_CPDuty  : 47|8@0+ (1,0) [0|255] "percent" SGW_SG
 SG_ POD_OBC_EMLockState  : 55|2@0+ (1,0) [0|2] "" SGW_SG
 SG_ POD_OBC_ChargCapacibility  : 53|2@0+ (1,0) [0|2] "" SGW_SG
 SG_ POD_OBC_S2State  : 51|2@0+ (1,0) [0|2] "" SGW_SG
 SG_ POD_OBC_OBCMaxPermOutpCrrt  : 48|9@0+ (0.1,0) [0|40] "A" SGW_SG

BO_ 580 POD_OBC_STATUS_02: 8 CGW_SG
 SG_ POD_OBC_ChrgOutpPwrAvl  : 7|8@0+ (0.1,-7) [-7|13] "kW" SGW_SG
 SG_ POD_OBC_OutputDCChargeCurrent  : 15|13@0+ (0.1,-250) [-250|250] "A" SGW_SG
 SG_ POD_OBC_ACPortTempA  : 31|8@0+ (1,-40) [-40|215] "celsius" SGW_SG
 SG_ POD_OBC_ACPortTempB  : 39|8@0+ (1,-40) [-40|215] "celsius" SGW_SG
 SG_ POD_OBC_ACFrequencyStatus  : 47|8@0+ (1,0) [0|255] "Hz" SGW_SG
 SG_ POD_OBC_OutputDCChargeVoltage  : 55|14@0+ (0.1,-800) [-800|800] "V" SGW_SG

BO_ 787 POD_OBC_STATUS_03: 8 CGW_SG
 SG_ POD_OBC_ACPortTempASensValid  : 7|2@0+ (1,0) [0|2] "" SGW_SG
 SG_ POD_OBC_ACPortTempBSensValid  : 5|2@0+ (1,0) [0|2] "" SGW_SG
 SG_ POD_OBC_ACPortTempAerror  : 3|1@0+ (1,0) [0|1] "" SGW_SG
 SG_ POD_OBC_ACPortTempBerror  : 2|1@0+ (1,0) [0|1] "" SGW_SG
 SG_ POD_OBC_FaultLevel  : 1|2@0+ (1,0) [0|3] "" SGW_SG
 SG_ POD_OBC_DCVoltHighFault  : 15|1@0+ (1,0) [0|1] "" SGW_SG
 SG_ POD_OBC_StartUpAllowed  : 14|1@0+ (1,0) [0|1] "" SGW_SG
 SG_ POD_OBC_CommunFault  : 13|1@0+ (1,0) [0|1] "" SGW_SG
 SG_ POD_OBC_DCCurHighFault  : 12|1@0+ (1,0) [0|1] "" SGW_SG
 SG_ POD_OBC_ACVoltHighFault  : 11|1@0+ (1,0) [0|1] "" SGW_SG
 SG_ POD_OBC_ACVoltLowFault  : 10|1@0+ (1,0) [0|1] "" SGW_SG
 SG_ POD_OBC_NlineStatus  : 9|1@0+ (1,0) [0|1] "" SGW_SG
 SG_ POD_OBC_OutputoverloadFault  : 8|1@0+ (1,0) [0|1] "" SGW_SG
 SG_ POD_OBC_InputFrequencyStatus  : 23|1@0+ (1,0) [0|1] "" SGW_SG
 SG_ POD_OBC_InputPhaseStatus  : 22|1@0+ (1,0) [0|1] "" SGW_SG
 SG_ POD_OBC_InputOverCurrentstatus_R  : 21|1@0+ (1,0) [0|1] "" SGW_SG
 SG_ POD_OBC_InputOverCurrentstatus_S  : 20|1@0+ (1,0) [0|1] "" SGW_SG
 SG_ POD_OBC_InputOverCurrentstatus_T  : 19|1@0+ (1,0) [0|1] "" SGW_SG
 SG_ POD_OBC_PFCUnderVoltageError  : 18|1@0+ (1,0) [0|1] "" SGW_SG
 SG_ POD_OBC_PFCOverVoltageError  : 17|1@0+ (1,0) [0|1] "" SGW_SG
 SG_ POD_OBC_OutputShortError  : 16|1@0+ (1,0) [0|1] "" SGW_SG
 SG_ POD_OBC_Side1Overtempfault  : 31|1@0+ (1,0) [0|1] "" SGW_SG
 SG_ POD_OBC_Side2Overtempfault  : 30|1@0+ (1,0) [0|1] "" SGW_SG
 SG_ POD_OBC_InternalFault  : 27|1@0+ (1,0) [0|1] "" SGW_SG
 SG_ POD_OBC_DCVoltLowFault  : 28|1@0+ (1,0) [0|1] "" SGW_SG
 SG_ POD_OBC_InputShortError  : 26|1@0+ (1,0) [0|1] "" SGW_SG
 SG_ POD_DCDC_CommunFault  : 25|1@0+ (1,0) [0|1] "" SGW_SG
 SG_ OBC_OutputIsolatedFault  : 24|1@0+ (1,0) [0|1] "" SGW_SG
 SG_ POD_OBC_PrimarySideTemp  : 39|8@0+ (1,-40) [-40|210] "celsius" SGW_SG
 SG_ POD_OBC_SecondarySideTemp  : 47|8@0+ (1,-40) [-40|210] "celsius" SGW_SG

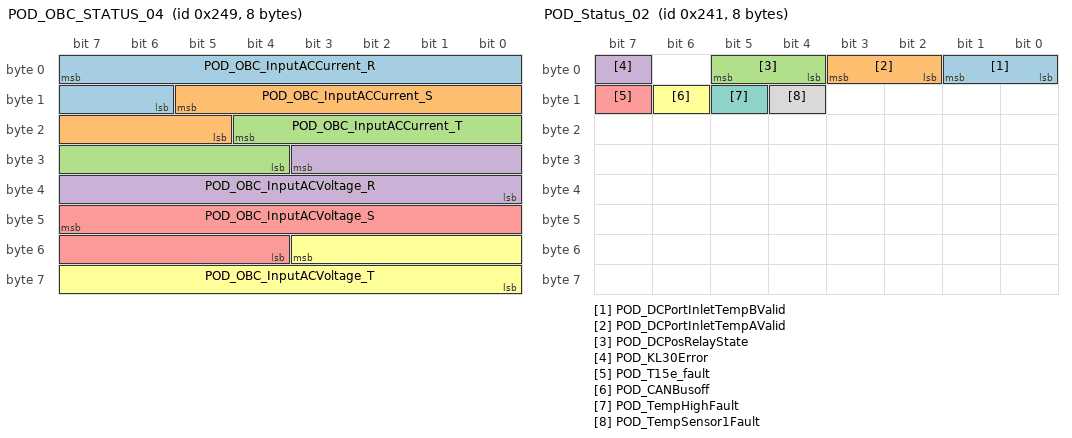
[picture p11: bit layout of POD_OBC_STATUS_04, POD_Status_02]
BO_ 585 POD_OBC_STATUS_04: 8 CGW_SG
 SG_ POD_OBC_InputACCurrent_R  : 7|10@0+ (0.1,-50) [-50|50] "" SGW_SG
 SG_ POD_OBC_InputACCurrent_S  : 13|9@0+ (0.1,0) [0|50] "" SGW_SG
 SG_ POD_OBC_InputACCurrent_T  : 20|9@0+ (0.1,0) [0|50] "" SGW_SG
 SG_ POD_OBC_InputACVoltage_R  : 27|12@0+ (0.1,0) [0|400] "" SGW_SG
 SG_ POD_OBC_InputACVoltage_S  : 47|12@0+ (0.1,0) [0|400] "V" SGW_SG
 SG_ POD_OBC_InputACVoltage_T  : 51|12@0+ (0.1,0) [0|400] "V" SGW_SG

BO_ 576 POD_Status_01: 8 CGW_SG
 SG_ POD_DCFCVoltage  : 12|13@0+ (0.1,0) [0|819] "V" SGW_SG
 SG_ POD_Temperature  : 31|8@0+ (1,-40) [-40|215] "celsius" SGW_SG
 SG_ POD_DCInletTempA  : 39|8@0+ (1,-40) [-40|215] "celsius" SGW_SG
 SG_ POD_DCInletTempB  : 47|8@0+ (1,-40) [-40|215] "celsius" SGW_SG

BO_ 577 POD_Status_02: 8 CGW_SG
 SG_ POD_DCPortInletTempBValid  : 1|2@0+ (1,0) [0|2] "" SGW_SG
 SG_ POD_DCPortInletTempAValid  : 3|2@0+ (1,0) [0|2] "" SGW_SG
 SG_ POD_DCPosRelayState  : 5|2@0+ (1,0) [0|2] "" SGW_SG
 SG_ POD_KL30Error  : 7|1@0+ (1,0) [0|1] "" SGW_SG
 SG_ POD_T15e_fault  : 15|1@0+ (1,0) [0|1] "" SGW_SG
 SG_ POD_CANBusoff  : 14|1@0+ (1,0) [0|1] "" SGW_SG
 SG_ POD_TempHighFault  : 13|1@0+ (1,0) [0|1] "" SGW_SG
 SG_ POD_TempSensor1Fault  : 12|1@0+ (1,0) [0|1] "" SGW_SG

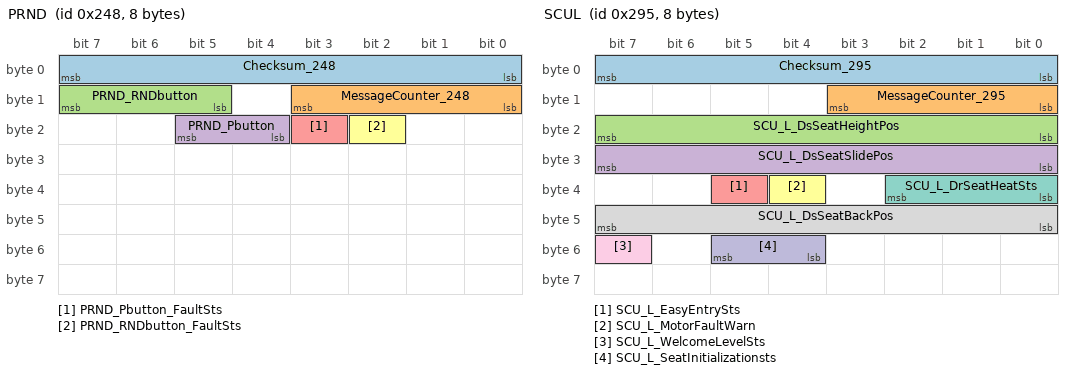
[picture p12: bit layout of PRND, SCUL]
BO_ 584 PRND: 8 CGW_SG
 SG_ Checksum_248  : 7|8@0+ (1,0) [0|255] "" SGW_SG
 SG_ MessageCounter_248  : 11|4@0+ (1,0) [0|15] "" SGW_SG
 SG_ PRND_RNDbutton  : 15|3@0+ (1,0) [0|7] "" SGW_SG
 SG_ PRND_Pbutton  : 21|2@0+ (1,0) [0|3] "" SGW_SG
 SG_ PRND_Pbutton_FaultSts  : 19|1@0+ (1,0) [0|1] "" SGW_SG
 SG_ PRND_RNDbutton_FaultSts  : 18|1@0+ (1,0) [0|1] "" SGW_SG

BO_ 661 SCUL: 8 CGW_SG
 SG_ Checksum_295  : 7|8@0+ (1,0) [0|255] "" SGW_SG
 SG_ MessageCounter_295  : 11|4@0+ (1,0) [0|15] "" SGW_SG
 SG_ SCU_L_DsSeatHeightPos  : 23|8@0+ (1,0) [0|100] "percent" SGW_SG
 SG_ SCU_L_DsSeatSlidePos  : 31|8@0+ (1,0) [0|100] "percent" SGW_SG
 SG_ SCU_L_EasyEntrySts  : 37|1@0+ (1,0) [0|1] "" SGW_SG
 SG_ SCU_L_MotorFaultWarn  : 36|1@0+ (1,0) [0|1] "" SGW_SG
 SG_ SCU_L_DrSeatHeatSts  : 34|3@0+ (1,0) [0|7] "" SGW_SG
 SG_ SCU_L_DsSeatBackPos  : 47|8@0+ (1,0) [0|100] "percent" SGW_SG
 SG_ SCU_L_WelcomeLevelSts  : 55|1@0+ (1,0) [0|1] "" SGW_SG
 SG_ SCU_L_SeatInitializationsts  : 53|2@0+ (1,0) [0|3] "" SGW_SG

BO_ 665 SCU_02: 8 CGW_SG
 SG_ SCU_L_SeatMemoryHeightPos  : 23|8@0+ (1,0) [0|100] "percent" SGW_SG
 SG_ SCU_L_SeatMemorySlidePos  : 31|8@0+ (1,0) [0|100] "percent" SGW_SG
 SG_ SCU_L_SeatMemoryBackPos  : 39|8@0+ (1,0) [0|100] "percent" SGW_SG

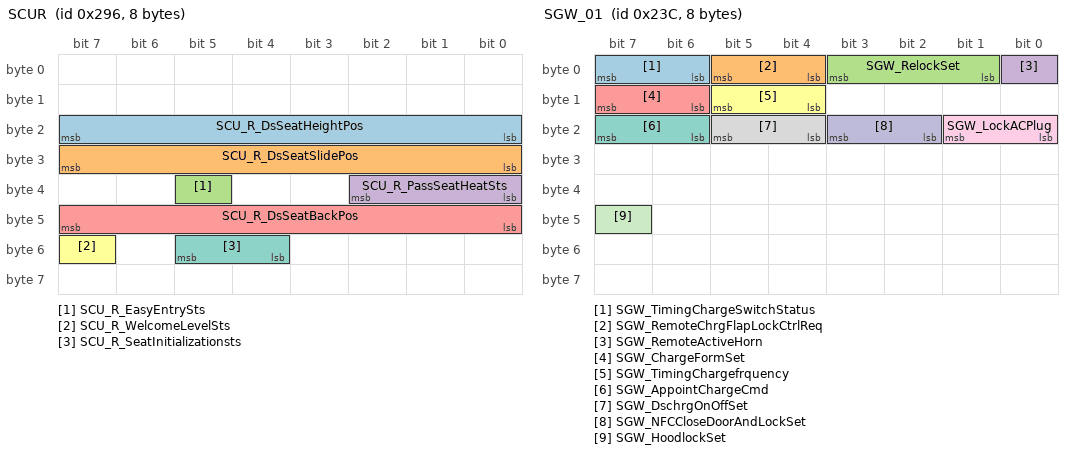
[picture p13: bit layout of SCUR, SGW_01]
BO_ 662 SCUR: 8 CGW_SG
 SG_ SCU_R_DsSeatHeightPos  : 23|8@0+ (1,0) [0|100] "percent" SGW_SG
 SG_ SCU_R_DsSeatSlidePos  : 31|8@0+ (1,0) [0|100] "percent" SGW_SG
 SG_ SCU_R_EasyEntrySts  : 37|1@0+ (1,0) [0|1] "" SGW_SG
 SG_ SCU_R_PassSeatHeatSts  : 34|3@0+ (1,0) [0|7] "" SGW_SG
 SG_ SCU_R_DsSeatBackPos  : 47|8@0+ (1,0) [0|100] "percent" SGW_SG
 SG_ SCU_R_WelcomeLevelSts  : 55|1@0+ (1,0) [0|1] "" SGW_SG
 SG_ SCU_R_SeatInitializationsts  : 53|2@0+ (1,0) [0|3] "" SGW_SG

BO_ 572 SGW_01: 8 SGW_SG
 SG_ SGW_TimingChargeSwitchStatus  : 7|2@0+ (1,0) [0|2] "" CGW_SG
 SG_ SGW_RemoteChrgFlapLockCtrlReq  : 5|2@0+ (1,0) [0|3] "" CGW_SG
 SG_ SGW_RelockSet  : 3|3@0+ (1,0) [0|5] "" CGW_SG
 SG_ SGW_RemoteActiveHorn  : 0|1@0+ (1,0) [0|1] "" CGW_SG
 SG_ SGW_ChargeFormSet  : 15|2@0+ (1,0) [0|2] "" CGW_SG
 SG_ SGW_TimingChargefrquency  : 13|2@0+ (1,0) [0|2] "" CGW_SG
 SG_ SGW_AppointChargeCmd  : 23|2@0+ (1,0) [0|2] "" CGW_SG
 SG_ SGW_DschrgOnOffSet  : 21|2@0+ (1,0) [0|3] "" CGW_SG
 SG_ SGW_LockACPlug  : 17|2@0+ (1,0) [0|2] "" CGW_SG
 SG_ SGW_NFCCloseDoorAndLockSet  : 19|2@0+ (1,0) [0|2] "" CGW_SG
 SG_ SGW_HoodlockSet  : 47|1@0+ (1,0) [0|1] "" CGW_SG

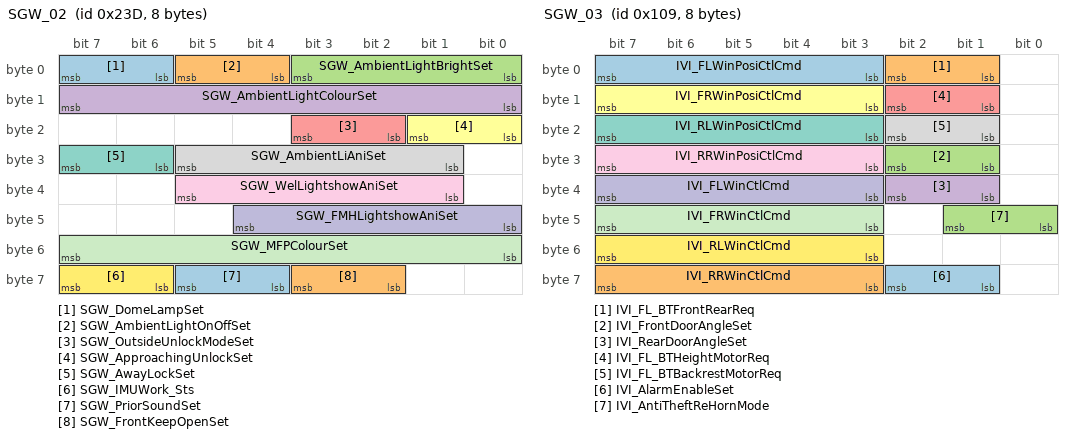
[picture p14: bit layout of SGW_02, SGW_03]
BO_ 573 SGW_02: 8 SGW_SG
 SG_ SGW_DomeLampSet  : 7|2@0+ (1,0) [0|3] "" CGW_SG
 SG_ SGW_AmbientLightOnOffSet  : 5|2@0+ (1,0) [0|3] "" CGW_SG
 SG_ SGW_AmbientLightBrightSet  : 3|4@0+ (1,0) [0|10] "" CGW_SG
 SG_ SGW_AmbientLightColourSet  : 15|8@0+ (1,0) [0|255] "" CGW_SG
 SG_ SGW_OutsideUnlockModeSet  : 19|2@0+ (1,0) [0|3] "" CGW_SG
 SG_ SGW_ApproachingUnlockSet  : 17|2@0+ (1,0) [0|3] "" CGW_SG
 SG_ SGW_AwayLockSet  : 31|2@0+ (1,0) [0|3] "" CGW_SG
 SG_ SGW_AmbientLiAniSet  : 29|5@0+ (1,0) [0|26] "" CGW_SG
 SG_ SGW_WelLightshowAniSet  : 37|5@0+ (1,0) [0|26] "" CGW_SG
 SG_ SGW_FMHLightshowAniSet  : 44|5@0+ (1,0) [0|26] "" CGW_SG
 SG_ SGW_MFPColourSet  : 55|8@0+ (1,0) [0|255] "" CGW_SG
 SG_ SGW_IMUWork_Sts  : 63|2@0+ (1,0) [0|3] "" CGW_SG
 SG_ SGW_PriorSoundSet  : 61|2@0+ (1,0) [0|3] "" CGW_SG
 SG_ SGW_FrontKeepOpenSet  : 59|2@0+ (1,0) [0|3] "" CGW_SG

BO_ 265 SGW_03: 8 SGW_SG
 SG_ IVI_FLWinPosiCtlCmd  : 7|5@0+ (1,0) [0|22] "" CGW_SG
 SG_ IVI_FL_BTFrontRearReq  : 2|2@0+ (1,0) [0|2] "" CGW_SG
 SG_ IVI_FrontDoorAngleSet  : 26|2@0+ (1,0) [0|2] "" CGW_SG
 SG_ IVI_RearDoorAngleSet  : 34|2@0+ (1,0) [0|2] "" CGW_SG
 SG_ IVI_FL_BTHeightMotorReq  : 10|2@0+ (1,0) [0|2] "" CGW_SG
 SG_ IVI_FRWinPosiCtlCmd  : 15|5@0+ (1,0) [0|22] "" CGW_SG
 SG_ IVI_RLWinPosiCtlCmd  : 23|5@0+ (1,0) [0|22] "" CGW_SG
 SG_ IVI_FL_BTBackrestMotorReq  : 18|2@0+ (1,0) [0|2] "" CGW_SG
 SG_ IVI_RRWinPosiCtlCmd  : 31|5@0+ (1,0) [0|22] "" CGW_SG
 SG_ IVI_FLWinCtlCmd  : 39|5@0+ (1,0) [0|21] "" CGW_SG
 SG_ IVI_FRWinCtlCmd  : 47|5@0+ (1,0) [0|21] "" CGW_SG
 SG_ IVI_RLWinCtlCmd  : 55|5@0+ (1,0) [0|21] "" CGW_SG
 SG_ IVI_AlarmEnableSet  : 58|2@0+ (1,0) [0|2] "" CGW_SG
 SG_ IVI_RRWinCtlCmd  : 63|5@0+ (1,0) [0|21] "" CGW_SG
 SG_ IVI_AntiTheftReHornMode  : 41|2@0+ (1,0) [0|2] "" CGW_SG

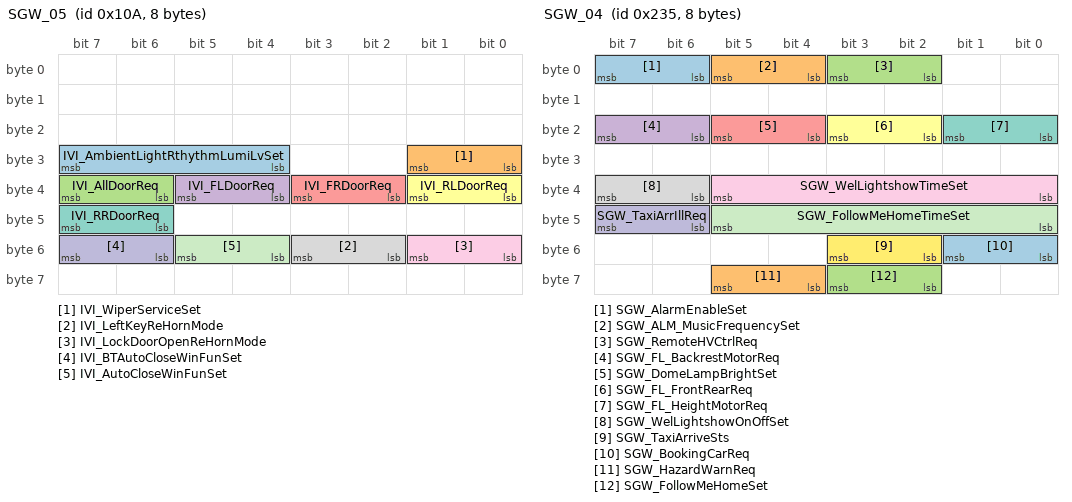
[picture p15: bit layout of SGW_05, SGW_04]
BO_ 266 SGW_05: 8 SGW_SG
 SG_ IVI_AmbientLightRthythmLumiLvSet  : 31|4@0+ (1,0) [0|10] "" CGW_SG
 SG_ IVI_WiperServiceSet  : 25|2@0+ (1,0) [0|2] "" CGW_SG
 SG_ IVI_AllDoorReq  : 39|2@0+ (1,0) [0|2] "" CGW_SG
 SG_ IVI_FLDoorReq  : 37|2@0+ (1,0) [0|2] "" CGW_SG
 SG_ IVI_FRDoorReq  : 35|2@0+ (1,0) [0|2] "" CGW_SG
 SG_ IVI_RLDoorReq  : 33|2@0+ (1,0) [0|2] "" CGW_SG
 SG_ IVI_RRDoorReq  : 47|2@0+ (1,0) [0|2] "" CGW_SG
 SG_ IVI_LeftKeyReHornMode  : 51|2@0+ (1,0) [0|2] "" CGW_SG
 SG_ IVI_LockDoorOpenReHornMode  : 49|2@0+ (1,0) [0|2] "" CGW_SG
 SG_ IVI_BTAutoCloseWinFunSet  : 55|2@0+ (1,0) [0|2] "" CGW_SG
 SG_ IVI_AutoCloseWinFunSet  : 53|2@0+ (1,0) [0|2] "" CGW_SG

BO_ 565 SGW_04: 8 SGW_SG
 SG_ SGW_AlarmEnableSet  : 7|2@0+ (1,0) [0|2] "" CGW_SG
 SG_ SGW_ALM_MusicFrequencySet  : 5|2@0+ (1,0) [0|3] "" CGW_SG
 SG_ SGW_RemoteHVCtrlReq  : 3|2@0+ (1,0) [0|2] "" CGW_SG
 SG_ SGW_FL_BackrestMotorReq  : 23|2@0+ (1,0) [0|2] "" CGW_SG
 SG_ SGW_DomeLampBrightSet  : 21|2@0+ (1,0) [0|2] "" CGW_SG
 SG_ SGW_FL_FrontRearReq  : 19|2@0+ (1,0) [0|2] "" CGW_SG
 SG_ SGW_FL_HeightMotorReq  : 17|2@0+ (1,0) [0|2] "" CGW_SG
 SG_ SGW_WelLightshowOnOffSet  : 39|2@0+ (1,0) [0|3] "" CGW_SG
 SG_ SGW_WelLightshowTimeSet  : 37|6@0+ (5,5) [5|180] "s" CGW_SG
 SG_ SGW_TaxiArrIllReq  : 47|2@0+ (1,0) [0|3] "" CGW_SG
 SG_ SGW_FollowMeHomeTimeSet  : 45|6@0+ (5,5) [5|180] "s" CGW_SG
 SG_ SGW_TaxiArriveSts  : 51|2@0+ (1,0) [0|2] "" CGW_SG
 SG_ SGW_BookingCarReq  : 49|2@0+ (1,0) [0|2] "" CGW_SG
 SG_ SGW_HazardWarnReq  : 61|2@0+ (1,0) [0|2] "" CGW_SG
 SG_ SGW_FollowMeHomeSet  : 59|2@0+ (1,0) [0|3] "" CGW_SG

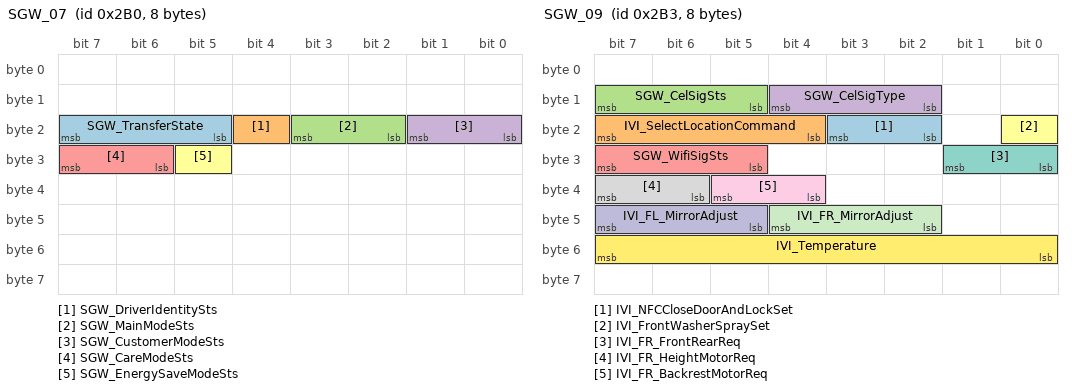
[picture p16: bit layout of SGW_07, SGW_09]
BO_ 688 SGW_07: 8 SGW_SG
 SG_ SGW_TransferState  : 23|3@0+ (1,0) [0|5] "" CGW_SG
 SG_ SGW_DriverIdentitySts  : 20|1@0+ (1,0) [0|1] "" CGW_SG
 SG_ SGW_MainModeSts  : 19|2@0+ (1,0) [0|2] "" CGW_SG
 SG_ SGW_CustomerModeSts  : 17|2@0+ (1,0) [0|3] "" CGW_SG
 SG_ SGW_CareModeSts  : 31|2@0+ (1,0) [0|2] "" CGW_SG
 SG_ SGW_EnergySaveModeSts  : 29|1@0+ (1,0) [0|1] "" CGW_SG

BO_ 690 SGW_08: 8 SGW_SG
 SG_ SGW_IMUWorkingSts  : 39|1@0+ (1,0) [0|1] "" CGW_SG
 SG_ SGW_VehicleTiltSlopeX  : 23|11@0+ (0.001,-1) [-1|1] "" CGW_SG
 SG_ SGW_VehicleTiltSlopeY  : 7|11@0+ (0.001,-1) [-1|1] "" CGW_SG

BO_ 691 SGW_09: 8 SGW_SG
 SG_ IVI_NFCCloseDoorAndLockSet  : 19|2@0+ (1,0) [0|2] "" CGW_SG
 SG_ IVI_SelectLocationCommand  : 23|4@0+ (1,0) [0|15] "" CGW_SG
 SG_ SGW_CelSigSts  : 15|3@0+ (1,0) [0|7] "" CGW_SG
 SG_ SGW_CelSigType  : 12|3@0+ (1,0) [0|7] "" CGW_SG
 SG_ SGW_WifiSigSts  : 31|3@0+ (1,0) [0|7] "" CGW_SG
 SG_ IVI_FrontWasherSpraySet  : 16|1@0+ (1,0) [0|1] "" CGW_SG
 SG_ IVI_FR_FrontRearReq  : 25|2@0+ (1,0) [0|2] "" CGW_SG
 SG_ IVI_FR_HeightMotorReq  : 39|2@0+ (1,0) [0|2] "" CGW_SG
 SG_ IVI_FR_BackrestMotorReq  : 37|2@0+ (1,0) [0|2] "" CGW_SG
 SG_ IVI_FL_MirrorAdjust  : 47|3@0+ (1,0) [0|7] "" CGW_SG
 SG_ IVI_FR_MirrorAdjust  : 44|3@0+ (1,0) [0|7] "" CGW_SG
 SG_ IVI_Temperature  : 55|8@0+ (1,-40) [-40|100] "celsius" CGW_SG

BO_ 268 SGW_10: 8 SGW_SG
 SG_ SGW_PENFCAuthSt  : 5|1@0+ (1,0) [0|1] "" CGW_SG
 SG_ SGW_GetNFCKeyCardsReq  : 4|1@0+ (1,0) [0|1] "" CGW_SG
 SG_ SGW_NFCPairModeReq  : 3|1@0+ (1,0) [0|1] "" CGW_SG
 SG_ SGW_SecOCFV_10C  : 23|16@0+ (1,0) [0|65535] "" CGW_SG
 SG_ SGW_SecOCMAC_10C  : 39|32@0+ (1,0) [0|4294967295] "" CGW_SG

BO_ 571 SGW_12: 8 SGW_SG
 SG_ SGW_TimingChargeEndhour  : 7|8@0+ (1,0) [0|31] "h" CGW_SG
 SG_ SGW_TimingChargeEndminute  : 15|8@0+ (1,0) [0|63] "min" CGW_SG
 SG_ SGW_TimingChargeStarthour  : 23|8@0+ (1,0) [0|31] "h" CGW_SG
 SG_ SGW_TimingChargeStartminute  : 31|8@0+ (1,0) [0|63] "min" CGW_SG

BO_ 692 SGW_16: 8 SGW_SG
 SG_ IVI_MirrorInterfaceMode  : 21|1@0+ (1,0) [0|1] "" CGW_SG
 SG_ IVI_VrState  : 33|1@0+ (1,0) [0|1] "" CGW_SG

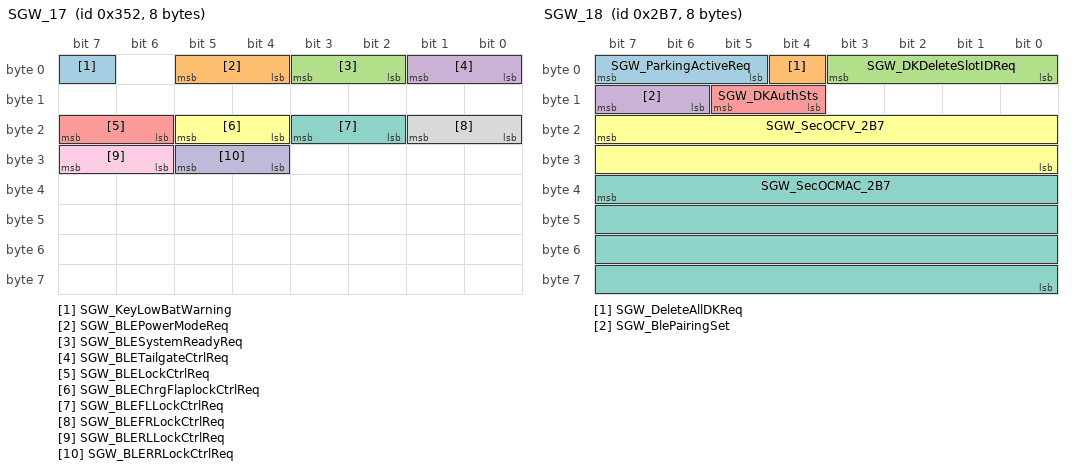
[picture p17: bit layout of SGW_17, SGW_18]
BO_ 850 SGW_17: 8 SGW_SG
 SG_ SGW_KeyLowBatWarning  : 7|1@0+ (1,0) [0|1] "" CGW_SG
 SG_ SGW_BLEPowerModeReq  : 5|2@0+ (1,0) [0|3] "" CGW_SG
 SG_ SGW_BLESystemReadyReq  : 3|2@0+ (1,0) [0|3] "" CGW_SG
 SG_ SGW_BLETailgateCtrlReq  : 1|2@0+ (1,0) [0|3] "" CGW_SG
 SG_ SGW_BLELockCtrlReq  : 23|2@0+ (1,0) [0|3] "" CGW_SG
 SG_ SGW_BLEChrgFlaplockCtrlReq  : 21|2@0+ (1,0) [0|3] "" CGW_SG
 SG_ SGW_BLEFLLockCtrlReq  : 19|2@0+ (1,0) [0|3] "" CGW_SG
 SG_ SGW_BLEFRLockCtrlReq  : 17|2@0+ (1,0) [0|3] "" CGW_SG
 SG_ SGW_BLERLLockCtrlReq  : 31|2@0+ (1,0) [0|3] "" CGW_SG
 SG_ SGW_BLERRLockCtrlReq  : 29|2@0+ (1,0) [0|3] "" CGW_SG

BO_ 695 SGW_18: 8 SGW_SG
 SG_ SGW_ParkingActiveReq  : 7|3@0+ (1,0) [0|7] "" CGW_SG
 SG_ SGW_DeleteAllDKReq  : 4|1@0+ (1,0) [0|1] "" CGW_SG
 SG_ SGW_DKDeleteSlotIDReq  : 3|4@0+ (1,0) [0|8] "" CGW_SG
 SG_ SGW_BlePairingSet  : 15|2@0+ (1,0) [0|3] "" CGW_SG
 SG_ SGW_DKAuthSts  : 13|2@0+ (1,0) [0|2] "" CGW_SG
 SG_ SGW_SecOCFV_2B7  : 23|16@0+ (1,0) [0|65535] "" CGW_SG
 SG_ SGW_SecOCMAC_2B7  : 39|32@0+ (1,0) [0|4294967295] "" CGW_SG

BO_ 960 SGW_FVSynchronization_01: 8 SGW_SG
 SG_ SGW_TripCounter  : 7|24@0+ (1,0) [0|16777215] "" CGW_SG
 SG_ SGW_ResetCounter  : 31|16@0+ (1,0) [0|65535] "" CGW_SG
 SG_ SGW_SynMsgAuthenticator  : 47|24@0+ (1,0) [0|16777215] "" CGW_SG

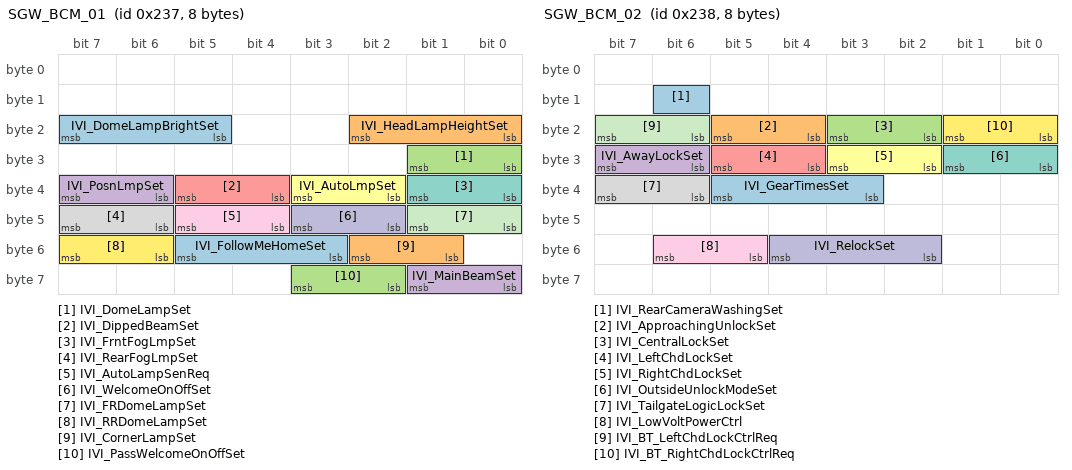
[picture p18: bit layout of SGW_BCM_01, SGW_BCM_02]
BO_ 567 SGW_BCM_01: 8 SGW_SG
 SG_ IVI_DomeLampBrightSet  : 23|3@0+ (1,0) [0|7] "" CGW_SG
 SG_ IVI_HeadLampHeightSet  : 18|3@0+ (1,0) [0|7] "" CGW_SG
 SG_ IVI_DomeLampSet  : 25|2@0+ (1,0) [0|3] "" CGW_SG
 SG_ IVI_PosnLmpSet  : 39|2@0+ (1,0) [0|3] "" CGW_SG
 SG_ IVI_DippedBeamSet  : 37|2@0+ (1,0) [0|3] "" CGW_SG
 SG_ IVI_AutoLmpSet  : 35|2@0+ (1,0) [0|3] "" CGW_SG
 SG_ IVI_FrntFogLmpSet  : 33|2@0+ (1,0) [0|3] "" CGW_SG
 SG_ IVI_RearFogLmpSet  : 47|2@0+ (1,0) [0|3] "" CGW_SG
 SG_ IVI_AutoLampSenReq  : 45|2@0+ (1,0) [0|3] "" CGW_SG
 SG_ IVI_WelcomeOnOffSet  : 43|2@0+ (1,0) [0|3] "" CGW_SG
 SG_ IVI_FRDomeLampSet  : 41|2@0+ (1,0) [0|2] "" CGW_SG
 SG_ IVI_RRDomeLampSet  : 55|2@0+ (1,0) [0|2] "" CGW_SG
 SG_ IVI_FollowMeHomeSet  : 53|3@0+ (1,0) [0|3] "" CGW_SG
 SG_ IVI_CornerLampSet  : 50|2@0+ (1,0) [0|3] "" CGW_SG
 SG_ IVI_PassWelcomeOnOffSet  : 59|2@0+ (1,0) [0|3] "" CGW_SG
 SG_ IVI_MainBeamSet  : 57|2@0+ (1,0) [0|3] "" CGW_SG

BO_ 568 SGW_BCM_02: 8 SGW_SG
 SG_ IVI_RearCameraWashingSet  : 14|1@0+ (1,0) [0|1] "" CGW_SG
 SG_ IVI_ApproachingUnlockSet  : 21|2@0+ (1,0) [0|3] "" CGW_SG
 SG_ IVI_CentralLockSet  : 19|2@0+ (1,0) [0|3] "" CGW_SG
 SG_ IVI_AwayLockSet  : 31|2@0+ (1,0) [0|3] "" CGW_SG
 SG_ IVI_LeftChdLockSet  : 29|2@0+ (1,0) [0|2] "" CGW_SG
 SG_ IVI_RightChdLockSet  : 27|2@0+ (1,0) [0|2] "" CGW_SG
 SG_ IVI_OutsideUnlockModeSet  : 25|2@0+ (1,0) [0|3] "" CGW_SG
 SG_ IVI_TailgateLogicLockSet  : 39|2@0+ (1,0) [0|3] "" CGW_SG
 SG_ IVI_LowVoltPowerCtrl  : 54|2@0+ (1,0) [0|3] "" CGW_SG
 SG_ IVI_RelockSet  : 52|3@0+ (1,0) [0|5] "" CGW_SG
 SG_ IVI_BT_LeftChdLockCtrlReq  : 23|2@0+ (1,0) [0|2] "" CGW_SG
 SG_ IVI_BT_RightChdLockCtrlReq  : 17|2@0+ (1,0) [0|2] "" CGW_SG
 SG_ IVI_GearTimesSet  : 37|3@0+ (1,0) [0|6] "" CGW_SG

BO_ 569 SGW_BCM_03: 8 SGW_SG
 SG_ SGW_RoleAccessSts  : 7|1@0+ (1,0) [0|1] "" CGW_SG
 SG_ SGW_FaceIDAuthenticationSuccess  : 5|1@0+ (1,0) [0|1] "" CGW_SG
 SG_ SGW_ImmobilizingEnable  : 1|2@0+ (1,0) [0|2] "" CGW_SG
 SG_ SGW_SecOCFV_239  : 23|16@0+ (1,0) [0|65535] "" CGW_SG
 SG_ SGW_SecOCMAC_239  : 39|32@0+ (1,0) [0|4294967295] "" CGW_SG

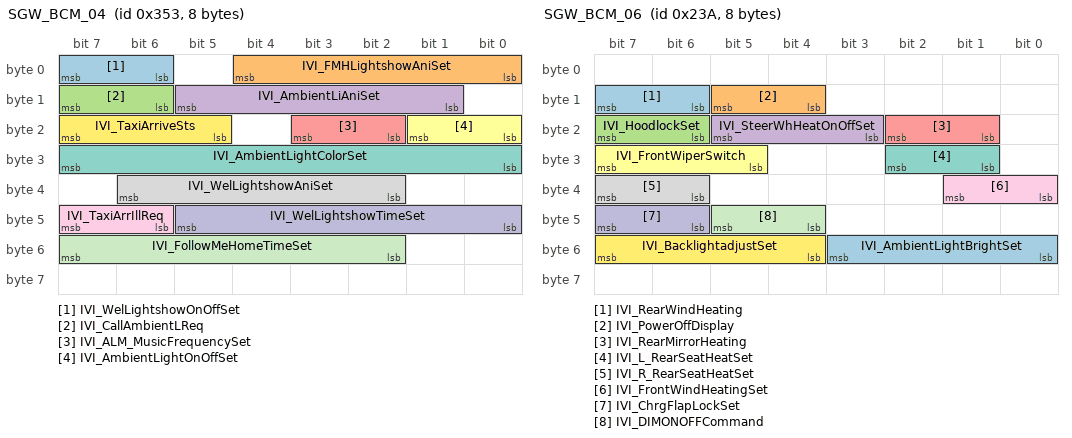
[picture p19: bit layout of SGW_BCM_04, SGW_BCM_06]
BO_ 851 SGW_BCM_04: 8 SGW_SG
 SG_ IVI_WelLightshowOnOffSet  : 7|2@0+ (1,0) [0|3] "" CGW_SG
 SG_ IVI_FMHLightshowAniSet  : 4|5@0+ (1,0) [0|26] "" CGW_SG
 SG_ IVI_CallAmbientLReq  : 15|2@0+ (1,0) [0|2] "" CGW_SG
 SG_ IVI_AmbientLiAniSet  : 13|5@0+ (1,0) [0|26] "" CGW_SG
 SG_ IVI_ALM_MusicFrequencySet  : 19|2@0+ (1,0) [0|3] "" CGW_SG
 SG_ IVI_AmbientLightOnOffSet  : 17|2@0+ (1,0) [0|3] "" CGW_SG
 SG_ IVI_AmbientLightColorSet  : 31|8@0+ (1,0) [0|255] "" CGW_SG
 SG_ IVI_WelLightshowAniSet  : 38|5@0+ (1,0) [0|26] "" CGW_SG
 SG_ IVI_TaxiArrIllReq  : 47|2@0+ (1,0) [0|3] "" CGW_SG
 SG_ IVI_WelLightshowTimeSet  : 45|6@0+ (5,5) [5|180] "s" CGW_SG
 SG_ IVI_FollowMeHomeTimeSet  : 55|6@0+ (5,5) [5|180] "s" CGW_SG
 SG_ IVI_TaxiArriveSts  : 23|3@0+ (1,0) [0|3] "" CGW_SG

BO_ 570 SGW_BCM_06: 8 SGW_SG
 SG_ IVI_RearWindHeating  : 15|2@0+ (1,0) [0|3] "" CGW_SG
 SG_ IVI_PowerOffDisplay  : 13|2@0+ (1,0) [0|3] "" CGW_SG
 SG_ IVI_HoodlockSet  : 23|2@0+ (1,0) [0|3] "" CGW_SG
 SG_ IVI_SteerWhHeatOnOffSet  : 21|3@0+ (1,0) [0|3] "" CGW_SG
 SG_ IVI_RearMirrorHeating  : 18|2@0+ (1,0) [0|3] "" CGW_SG
 SG_ IVI_FrontWiperSwitch  : 31|3@0+ (1,0) [0|5] "" CGW_SG
 SG_ IVI_L_RearSeatHeatSet  : 26|2@0+ (1,0) [0|3] "" CGW_SG
 SG_ IVI_R_RearSeatHeatSet  : 39|2@0+ (1,0) [0|3] "" CGW_SG
 SG_ IVI_FrontWindHeatingSet  : 33|2@0+ (1,0) [0|3] "" CGW_SG
 SG_ IVI_ChrgFlapLockSet  : 47|2@0+ (1,0) [0|3] "" CGW_SG
 SG_ IVI_DIMONOFFCommand  : 45|2@0+ (1,0) [0|3] "" CGW_SG
 SG_ IVI_BacklightadjustSet  : 55|4@0+ (1,0) [0|13] "" CGW_SG
 SG_ IVI_AmbientLightBrightSet  : 51|4@0+ (1,0) [0|10] "" CGW_SG

CM_ SG_ 643 DCM_FR_CarSharingColorSts "DCM_FR feedback car sharing color status";
CM_ SG_ 643 DCM_FR_CarSharingTimeSts "DCM_FR feedback car sharing welcome light runtime status";
CM_ SG_ 643 DCM_FR_PowerDoorModeSts "Status of FR Power Door Mode";
CM_ SG_ 643 DCM_FR_FrontKeepOpenSts "Status feedback of FR “keep the front door opened”";
CM_ SG_ 643 DCM_FR_PriorSoundSts "Status feedback of sound reminder prior FR door automatic via speaker";
CM_ SG_ 643 DCM_FR_CarSharingLightSts "DCM_FR feedback car sharing light stauts";
CM_ SG_ 643 DCM_FR_WelcomeOnOffSts "DCM_FR feedback automatically activate the welcome light stauts";
CM_ SG_ 643 DCM_FR_DoorFRLockSts "Right front door locked state";
CM_ SG_ 643 DCM_FR_DoorFRAngle "FR door angle signal";
CM_ SG_ 643 DCM_FR_FRPESwitchReq "Right front exterior door handle PE switch status";
CM_ SG_ 643 DCM_FR_DoorAntiPinchSts "Right front door anti pinch status";
CM_ SG_ 643 DCM_FR_DoorObstacleSts "Right front door obstacle avoidance status";
CM_ SG_ 643 DCM_FR_ElectricDoorMovementSts "FR Electric door movement status";
CM_ SG_ 643 DCM_FR_LinkageAvoidanceReq "RR door linkage avoidance";
CM_ SG_ 643 DCM_FR_InsideSwitchReq "Front passenger door open switch operation";
CM_ SG_ 643 DCM_FR_WindowSts "Front right window status";
CM_ SG_ 643 DCM_FR_PWM_POS_STS "Passenger window position status";
CM_ SG_ 643 DCM_FR_GLASS_LOCATION "Right front window percentage position";
CM_ SG_ 643 DCM_FR_FrontDoorAngleFeedback "Feedback value for rear door angle setting";
CM_ SG_ 643 DCM_FR_FRWindowLockSts "Passenger window disabled";
CM_ SG_ 643 DCM_FR_DoorFRSts "Right front door status signal";
CM_ SG_ 651 Checksum_28B "Checksum signal for frame";
CM_ SG_ 651 MessageCounter_28B "Message counter signal for frame";
CM_ SG_ 651 DCM_FR_PowerDoorErrorSts "FR Power Door error status";
CM_ SG_ 651 DCM_FR_AmbientTemperatureValid "Ambient temperature Valid";
CM_ SG_ 651 DCM_FR_AmbientTemperature "Ambient temperature";
CM_ SG_ 651 DCM_FR_RightMirrorHorizontalPos "Right rearview mirror left and right position (percentage)";
CM_ SG_ 651 DCM_FR_RightMirrorVerticalPos "Right rearview mirror up and down position (percentage)";
CM_ SG_ 651 DCM_FR_MirrorAutoTurnDownSts "Right exterior mirror automatic flip down enable status feedback";
CM_ SG_ 651 DCM_FR_MirrorAutoFoldUnfoldSts "Right exterior mirror automatic folding and unfolding setting status";
CM_ SG_ 651 DCM_FR_RearmirrorHeatingSts "EN: Right rear mirror heat status";
CM_ SG_ 651 DCM_FR_MirrorFold_UnfoldSts "Mirror folding or unfolding status signal";
CM_ SG_ 653 DCM_FR_MirrorTiltVerticalPos "Locally stored right exterior mirror vertical position in tilt mode";
CM_ SG_ 653 DCM_FR_MirrorTiltHorizontalPos "Locally stored right exterior mirror horizontal position in tilt mode";
CM_ SG_ 653 DCM_FR_MirrorMainVerticalPos "Locally stored right exterior mirror vertical position in main mode";
CM_ SG_ 653 DCM_FR_MirrorMainHorizontalPos "Locally stored right exterior mirror horizontal position in main mode";
CM_ SG_ 310 DCM_FR_MirrorAdjustmentSts "Left exterior mirror adjustment failure status";
CM_ SG_ 310 DCM_FR_MirrorFoldFaultSts "Left exterior mirror folding and unfolding failure status";
CM_ SG_ 310 DCM_FR_HandleFailReminder "Reminder of FR Hidden Hnadle Fnfolding";
CM_ SG_ 310 DCM_FR_PriorSoundReq "Require of sound reminder prior FR door automatic via speaker";
CM_ SG_ 644 Checksum_284 "Checksum signal for frame";
CM_ SG_ 644 MessageCounter_284 "Message counter signal for frame";
CM_ SG_ 644 DCM_RL_DoorRLLockSts "left rear door locked state";
CM_ SG_ 644 DCM_RL_DoorRLAngle "RL door angle signal";
CM_ SG_ 644 DCM_RL_RLPESwitchReq "Left rear exterior door handle PE switch status";
CM_ SG_ 644 DCM_RL_DoorObstacleSts "Left rear door obstacle avoidance status";
CM_ SG_ 644 DCM_RL_DoorAntiPinchSts "Left rear  door anti pinch status";
CM_ SG_ 644 DCM_RL_ElectricDoorMovementSts "RL Electric door movement status";
CM_ SG_ 644 DCM_RL_LinkageAvoidanceReq "FL door linkage avoidance";
CM_ SG_ 644 DCM_RL_InsideSwitchReq "Left rear door open switch operation";
CM_ SG_ 644 DCM_RL_WindowSts "Left rear window status";
CM_ SG_ 644 DCM_RL_PWM_POS_STS "Left rear window position status";
CM_ SG_ 644 DCM_RL_GLASS_LOCATION "Left rear window percentage position";
CM_ SG_ 644 DCM_RL_RearDoorAngleFeedback "Feedback value for rear door angle setting";
CM_ SG_ 644 DCM_RL_RLWindowLockSts "Rear left window disabled";
CM_ SG_ 644 DCM_RL_DoorRLSts "Left rear door status signal";
CM_ SG_ 644 DCM_RL_PowerDoorErrorSts "RL Power Door error status";
CM_ SG_ 644 DCM_RL_PriorSoundSts "Status feedback of sound reminder prior RL door automatic via speaker";
CM_ SG_ 644 DCM_RL_PowerDoorModeSts "Status of RL Power Door Mode";
CM_ SG_ 644 DCM_RL_WelcomeOnOffSts "DCM_RL feedback automatically activate the welcome light stauts";
CM_ SG_ 644 DCM_RL_CarSharingLightSts "DCM_RL feedback car sharing light stauts";
CM_ SG_ 644 DCM_RL_CarSharingColorSts "DCM_RL feedback car sharing color status";
CM_ SG_ 644 DCM_RL_CarSharingTimeSts "DCM_RL feedback car sharing welcome light runtime status";
CM_ SG_ 311 DCM_RL_PriorSoundReq "Require of sound reminder prior RL door automatic via speaker";
CM_ SG_ 645 Checksum_285 "Checksum signal for frame";
CM_ SG_ 645 MessageCounter_285 "Message counter signal for frame";
CM_ SG_ 645 DCM_RR_DoorRRLockSts "Right rear door locked state";
CM_ SG_ 645 DCM_RR_DoorRRAngle "RR door angle signal";
CM_ SG_ 645 DCM_RR_RRPESwitchReq "Right rear exterior door handle PE switch status";
CM_ SG_ 645 DCM_RR_DoorObstacleSts "Right rear door obstacle avoidance status";
CM_ SG_ 645 DCM_RR_DoorAntiPinchSts "Right rear door anti pinch status";
CM_ SG_ 645 DCM_RR_ElectricDoorMovementSts "RR Electric door movement status";
CM_ SG_ 645 DCM_RR_LinkageAvoidanceReq "FR door linkage avoidance";
CM_ SG_ 645 DCM_RR_InsideSwitchReq "Right rear door o open switch operation";
CM_ SG_ 645 DCM_RR_WindowSts "Right rear window status";
CM_ SG_ 645 DCM_RR_PWM_POS_STS "Right rear window position status";
CM_ SG_ 645 DCM_RR_GLASS_LOCATION "Right rear window percentage position";
CM_ SG_ 645 DCM_RR_RearDoorAngleFeedback "Feedback value for rear door angle setting";
CM_ SG_ 645 DCM_RR_RRWindowLockSts "Rear right window disabled";
CM_ SG_ 645 DCM_RR_DoorRRSts "Right rear door status signal";
CM_ SG_ 645 DCM_RR_PowerDoorErrorSts "RR Power Door error status";
CM_ SG_ 645 DCM_RR_PriorSoundSts "Status feedback of sound reminder prior RR door automatic via speaker";
CM_ SG_ 645 DCM_RR_PowerDoorModeSts "Status of RR Power Door Mode";
CM_ SG_ 645 DCM_RR_WelcomeOnOffSts "DCM_RR feedback automatically activate the welcome light stauts";
CM_ SG_ 645 DCM_RR_CarSharingLightSts "DCM_RR feedback car sharing light stauts";
CM_ SG_ 645 DCM_RR_CarSharingColorSts "DCM_RR feedback car sharing color status";
CM_ SG_ 645 DCM_RR_CarSharingTimeSts "DCM_RR feedback car sharing welcome light runtime status";
CM_ SG_ 312 DCM_RR_PriorSoundReq "Require of sound reminder prior RR door automatic via speaker";
CM_ SG_ 880 DCM_SDS_FL_SensorWorksts "Front left door radar working status";
CM_ SG_ 881 DCM_SDS_FR_SensorWorksts "Front right door radar working status";
CM_ SG_ 882 DCM_SDS_RL_SensorWorksts "Rear left door radar working status";
CM_ SG_ 883 DCM_SDS_RR_SensorWorksts "Rear right door radar working status";
CM_ SG_ 714 DIM_ScreenBrightnessSta "DIM feedback on screen brightness status";
CM_ SG_ 714 DIM_AutoScreenBacklightSta "DIM Screen Brightness Feedback Auto Mode Status";
CM_ SG_ 714 DIM_FaultState "DIM fault signal";
CM_ SG_ 714 DIM_ONOFFSts "DIM ON/OFF";
CM_ SG_ 512 ERA_ECallSts "E-Call call status";
CM_ SG_ 512 ERA_TestModeSts "ERA test mode";
CM_ SG_ 512 ERA_SelfTestSts "ERA self-test status";
CM_ SG_ 241 Checksum_0F1 "Checksum signal for frame";
CM_ SG_ 241 MessageCounter_0F1 "Message counter signal for frame";
CM_ SG_ 241 EPS_APS_CtrlSts "Automatic Parking Control Status";
CM_ SG_ 241 EPS_APS_CtrlFaultSts "EPS response parking control fault status";
CM_ SG_ 241 EPS_LCA_CtrlRequestSts "LCA control request status";
CM_ SG_ 241 EPS_LCA_Active "LCA control active status";
CM_ SG_ 240 Checksum_0F0 "Checksum signal for frame";
CM_ SG_ 240 MessageCounter_0F0 "Message counter signal for frame";
CM_ SG_ 240 EPS_SteeringWheelAngleSpd "steering wheel angle speed.";
CM_ SG_ 240 EPS_SteeringWheelAngleValid "steering wheel angle valid signal";
CM_ SG_ 240 EPS_SteeringWheelAngleSpdValid "steering wheel angle speed valid signal.";
CM_ SG_ 240 EPS_TorsionBarTorqueValid "Torsion Bar torque valid signal";
CM_ SG_ 240 EPS_ModeChangeEnable "steering mode change enable status";
CM_ SG_ 240 EPS_ModeFb "steering mode status feedback";
CM_ SG_ 240 EPS_WarningLamp "EPS warning lamp";
CM_ SG_ 240 EPS_SteeringWheelAngle "steering wheel angle";
CM_ SG_ 240 EPS_TorsionBarTorque "Torsion Bar torque";
CM_ SG_ 614 EVCOM_OverPwrDropFreqError "EVCOM Over Power Drop Frequency Error";
CM_ SG_ 614 EVCOM_OverCurDropFreqError "EVCOM Over Current Drop Frequency Error";
CM_ SG_ 614 EVCOM_CommunicationError "EVCOM Communication Error";
CM_ SG_ 614 EVCOM_StandByUnderVolError "EVCOM Stand By Under Voltage Error";
CM_ SG_ 614 EVCOM_StandByOverVolError "EVCOM Stand By Over Voltage Error";
CM_ SG_ 614 EVCOM_UnderVoltageError "EVCOM Under Voltage Error LV";
CM_ SG_ 614 EVCOM_OverVoltageError "EVCOM Over Voltage Error LV";
CM_ SG_ 614 EVCOM_OverCurrentError "EVCOM Over Current Error";
CM_ SG_ 614 EVCOM_CompDeviceInternTemp "Device Internal Temperature";
CM_ SG_ 614 EVCOM_CompActlSpd "Compressor Actual Speed";
CM_ SG_ 614 EVCOM_CompActlPwrCnsmp "Compressor Actual Power Consumption";
CM_ SG_ 614 EVCOM_CompActlCnsmpCur "Compressor Run Current";
CM_ SG_ 614 EVCOM_ActlOprtMode "Air Conditioning Compressor Actual Operation Mode";
CM_ SG_ 615 EVCOM_OverLoad "EVCOM  Over Load Error";
CM_ SG_ 615 EVCOM_InpowerError "EVCOM  Inpower Error";
CM_ SG_ 615 EVCOM_LackPhase "EVCOM  Lack Phase Error";
CM_ SG_ 615 EVCOM_TemperSensorError "EVCOM  Temperature Sensor Error";
CM_ SG_ 615 EVCOM_CurrentOffsetError "EVCOM Current offset Error";
CM_ SG_ 615 EVCOM_OverHeat "EVCOM Over Heat Error";
CM_ SG_ 615 EVCOM_CompBusVolt "Compressor Bus Voltage";
CM_ SG_ 615 EVCOM_CompActlCnsmpPhaseCur "Compressor Run Phase Current";
CM_ SG_ 615 EVCOM_StallFault "Stall Fault";
CM_ SG_ 640 Checksum_280 "Checksum signal for frame";
CM_ SG_ 640 MessageCounter_280 "Message counter signal for frame";
CM_ SG_ 640 HLL_HeadlampFault "Left head lamp fault";
CM_ SG_ 640 HLL_DRLFaultSts "HLL DRL fualt";
CM_ SG_ 641 Checksum_281 "Checksum signal for frame";
CM_ SG_ 641 MessageCounter_281 "Message counter signal for frame";
CM_ SG_ 641 HLR_HeadlampFault "Right head lamp fault";
CM_ SG_ 641 HLR_DRLFaultSts "HLR DRL fualt";
CM_ SG_ 660 HOD_Heating_SteerWhHeatSts "Steering wheel heating status";
CM_ SG_ 658 HUD_SelfCheckSts "HUD Self Check Status";
CM_ SG_ 658 HUD_BrightnessSet "Brightness state";
CM_ SG_ 658 HUD_OnOffSts "HUD state";
CM_ SG_ 658 HUD_HeightSts "HUD height state";
CM_ SG_ 658 HUD_BrightnessSts "Brightness state";
CM_ SG_ 184 Checksum_0B8 "Checksum signal for frame";
CM_ SG_ 184 MessageCounter_0B8 "Message counter signal for frame";
CM_ SG_ 184 IBS_VehicleStandstill_Valid "Validity of indicating signal IBS_vehiclestill";
CM_ SG_ 184 IBS_WLTorqueVLCReq "VLC Wheel Torque Request";
CM_ SG_ 184 IBS_WLTorqueVLCReqValid "VLC Wheel Torque Request Valid";
CM_ SG_ 184 IBS_CddAvailable "Indicate CDD is available or not.";
CM_ SG_ 184 IBS_CddError "Indicate the failure status of CDD";
CM_ SG_ 184 IBS_CddActive "Indicate CDD is active or not.";
CM_ SG_ 184 IBS_VehicleStandstill "Indicating whether the vehicle is standstill or not Cannot be set until standstill is surely reached.";
CM_ SG_ 184 IBS_VlcAvalible "Indicating whether VLC is basically ready for activation or not. It could be combined with VLCFail.";
CM_ SG_ 184 IBS_VlcError "Indicate the failure status of VLC.";
CM_ SG_ 184 IBS_VlcActive "Indicates VLC is active or not.";
CM_ SG_ 183 Checksum_0B7 "Checksum signal for frame";
CM_ SG_ 183 MessageCounter_0B7 "Message counter signal for frame";
CM_ SG_ 183 IBS_APS_Avl "Indicate the function availability";
CM_ SG_ 183 IBS_BrakeTypEcho "Feedback Comfort or emergency to upper system";
CM_ SG_ 183 IBS_APSCrlReqEcho "Feedback control status to upper system";
CM_ SG_ 183 IBS_APSModeEcho "Feedback  to upper system";
CM_ SG_ 183 IBS_APSComfortAvl "Feedback of APS Comfort Availability";
CM_ SG_ 183 IBS_APSEmergenyAvl "Feedback of  APS Emergency Availability";
CM_ SG_ 178 Checksum_0B2 "Checksum signal for frame";
CM_ SG_ 178 MessageCounter_0B2 "Message counter signal for frame";
CM_ SG_ 178 IBS_BrakePedalStatus "Brake Pedal Status";
CM_ SG_ 178 IBS_BrakePedalStatusValid "Brake Pedal Status Valid";
CM_ SG_ 178 IBS_MasterCylinderPressure "EN: Master Cylinder Pressure signal";
CM_ SG_ 178 IBS_PlungerPressure "pressure of PSU";
CM_ SG_ 178 IBS_BrakePushrodStroke "IBS pushrod stroke";
CM_ SG_ 179 Checksum_0B3 "Checksum signal for frame";
CM_ SG_ 179 MessageCounter_0B3 "Message counter signal for frame";
CM_ SG_ 179 IBS_EPBFailureLamp "EN: EPB Failure Lamp";
CM_ SG_ 179 IBS_BrakeLightRequest "EN: IBS request to turn on the stop lamp when the active braking is triggered";
CM_ SG_ 179 IBS_EPBworkingSts "EN: EPB Status";
CM_ SG_ 179 IBS_TCSActive "EN: Tindicates TCS intervention active,TCS will detect spinning wheels and request torque reduction/limitation";
CM_ SG_ 179 IBS_VDCActive "EN: indicates VDC intervention active,
ESP will detect other vehicle slip/slide situations, and brake individual wheels to counteract the vehicle slid";
CM_ SG_ 179 IBS_HDCAvailable "EN: HDC Function Available";
CM_ SG_ 179 IBS_AEBActive "EN: AEB Function Active";
CM_ SG_ 179 IBS_HHCActive "EN: HHC Function Active";
CM_ SG_ 179 IBS_HHCAvailable "EN: HHC Function Available";
CM_ SG_ 179 IBS_AVHAvailable "EN: AVH Function Available";
CM_ SG_ 179 IBS_HazWarnReq "EN: Hazard warning Lamps";
CM_ SG_ 179 IBS_EPBFunctionLamp "EN: EPB Function Lamp";
CM_ SG_ 179 IBS_AEBAvailable "Information indicating whether braking control for AEB is possible or not";
CM_ SG_ 180 Checksum_0B4 "Checksum signal for frame";
CM_ SG_ 180 MessageCounter_0B4 "Message counter signal for frame";
CM_ SG_ 180 IBS_EPBTextdisplay "EN: EPB Text display";
CM_ SG_ 180 IBS_VehicleSpeed "EN: Vehicle speed";
CM_ SG_ 180 IBS_SystemStatus "IBS System Status";
CM_ SG_ 180 IBS_VehicleSpeedValid "EN: Vehicle speed valid";
CM_ SG_ 180 IBS_ABSFault "ABS system has detected a failure which does not allow a reliable ABS regulation and is therefore switched off.";
CM_ SG_ 180 IBS_EBDActive "EBD Active Status";
CM_ SG_ 180 IBS_EBDFault "ABS system has detected a heavy fault, which does not even allow a reliable electronic brake distribution and is therefore completely shut down.";
CM_ SG_ 180 IBS_VDCFault "EN: VDC status valid";
CM_ SG_ 180 IBS_TCSFault "EN: TCS status valid";
CM_ SG_ 180 IBS_ABSActive "indicates ABS intervention active.";
CM_ SG_ 180 IBS_ABPActive "Prefill(ABP) is active or not.";
CM_ SG_ 180 IBS_ABPAvailable "Prefill(ABP) is available or not.";
CM_ SG_ 180 IBS_DTCFault "Drag Torque Control fault";
CM_ SG_ 180 IBS_VCU_DecelerationRequest_Available "Indicates whether the VCU-related deceleration request function is available";
CM_ SG_ 186 Checksum_0BA "Checksum signal for frame";
CM_ SG_ 186 MessageCounter_0BA "Message counter signal for frame";
CM_ SG_ 186 IBS_CDPActive "Indicate CDP Control Active";
CM_ SG_ 187 Checksum_0BB "Checksum signal for frame";
CM_ SG_ 187 MessageCounter_0BB "Message counter signal for frame";
CM_ SG_ 187 IBS_SUBEPBworkingSts "EPB Status(Redundant EPB status)";
CM_ SG_ 187 IBS_SUBEPBFailureStatus "EPB failure status(Redundant EPB status)";
CM_ SG_ 188 Checksum_0BC "Checksum signal for frame";
CM_ SG_ 188 MessageCounter_0BC "Message counter signal for frame";
CM_ SG_ 188 IBS_HBAActive "HBA Active Status";
CM_ SG_ 188 IBS_ESCOffSts "ESC OFF Status";
CM_ SG_ 188 IBS_RWUActive "Indicate RWU Control Active";
CM_ SG_ 188 IBS_RWUAvailable "EN: RWU Function Available";
CM_ SG_ 188 IBS_MaintenaceMode "Maintenace Mode Status";
CM_ SG_ 188 IBS_RollerbenchMode "Rollerbench Mode Status";
CM_ SG_ 188 IBS_FactoryMode "Factory Mode Status";
CM_ SG_ 188 IBS_AVHSts "Indicates AVH in Active or Standby or Off";
CM_ SG_ 188 IBS_ESClampdisplay "ESC function lamp display for IVI";
CM_ SG_ 188 IBS_HDCSts "Indicates HDC in Active or Off";
CM_ SG_ 188 IBS_BrakeFluidWarning "Brake Fluid Warning";
CM_ SG_ 188 IBS_EPBFailureStatus "EPB failure status";
CM_ SG_ 188 IBS_TireMonSysSts "TMPS system status";
CM_ SG_ 188 IBS_TPMS_ResetSts "Reset TPMS status";
CM_ SG_ 188 IBS_TireWarnReLe "Alarm status at left rear";
CM_ SG_ 188 IBS_TireWarnReRi "Alarm status at right rear";
CM_ SG_ 188 IBS_TireWarnFrntLe "Alarm status at left front";
CM_ SG_ 188 IBS_TireWarnFrntRi "Alarm status at right rear";
CM_ SG_ 185 Checksum_0B9 "Checksum signal for frame";
CM_ SG_ 185 MessageCounter_0B9 "Message counter signal for frame";
CM_ SG_ 185 IBS_WLTorqueRBSReqValid "EN: CRBS wheel torque request valid";
CM_ SG_ 185 IBS_WLTorqueRBSReq "EN: CRBS wheel torque request";
CM_ SG_ 185 IBS_RBSStatus "EN: Energy recovery status";
CM_ SG_ 185 IBS_VCU_DecelerationReqActive "IBS activation signal in response to VCU deceleration request";
CM_ SG_ 185 IBS_TargetGearReq "IBS fotwarded APS Gear request";
CM_ SG_ 185 IBS_WLTorqueAPSReqValid "APS wheel torque request valid";
CM_ SG_ 185 IBS_WLTorqueAPSReq "APS wheel torque request";
CM_ SG_ 144 Checksum_090 "Checksum signal for frame";
CM_ SG_ 144 MessageCounter_090 "Message counter signal for frame";
CM_ SG_ 144 IBS_WLTorqueIncrReqSts "Wheel torque increase request status.";
CM_ SG_ 144 IBS_WLTorqueRedReq "Wheel torque reduction request.";
CM_ SG_ 144 IBS_WLTorqueRedReqSts "Wheel torque reduction request status.";
CM_ SG_ 144 IBS_WLTorqueIncrReq "Wheel torque increase request";
CM_ SG_ 176 Checksum_0B0 "Checksum signal for frame";
CM_ SG_ 176 MessageCounter_0B0 "Message counter signal for frame";
CM_ SG_ 176 IBS_FRWheelSpeed_Fault "EN: Front right wheel speed signal valid";
CM_ SG_ 176 IBS_FRMovingDirection "EN: Front right wheel direction";
CM_ SG_ 176 IBS_FRWheelSpeed "EN: Front right wheel speed";
CM_ SG_ 176 IBS_FRWheelPulseCounter "EN: Front right wheel speed pulse";
CM_ SG_ 176 IBS_FLWheelSpeed_Fault "EN: Front left wheel speed signal valid";
CM_ SG_ 176 IBS_FLMovingDirection "EN: Front left wheel direction";
CM_ SG_ 176 IBS_FLWheelSpeed "EN: Front left wheel speed";
CM_ SG_ 176 IBS_FLWheelPulseCounter "EN: Front left wheel speed pulse";
CM_ SG_ 177 Checksum_0B1 "Checksum signal for frame";
CM_ SG_ 177 MessageCounter_0B1 "Message counter signal for frame";
CM_ SG_ 177 IBS_RRWheelSpeed_Fault "EN: Rear right wheel speed signal valid";
CM_ SG_ 177 IBS_RRMovingDirection "EN: Rear right wheel direction";
CM_ SG_ 177 IBS_RRWheelSpeed "EN: Rear right wheel speed";
CM_ SG_ 177 IBS_RRWheelPulseCounter "EN: Rear right wheel speed pulse";
CM_ SG_ 177 IBS_RLWheelSpeed_Fault "EN: Rear left wheel speed signal valid";
CM_ SG_ 177 IBS_RLMovingDirection "EN: Rear left wheel direction";
CM_ SG_ 177 IBS_RLWheelSpeed "EN: Rear left wheel speed";
CM_ SG_ 177 IBS_RLWheelPulseCounter "EN: Rear left wheel speed pulse";
CM_ SG_ 152 Checksum_098 "Checksum signal for frame";
CM_ SG_ 152 MessageCounter_098 "Message counter signal for frame";
CM_ SG_ 152 MCU_ActualSpeedValid "Motor actual speed valid status";
CM_ SG_ 152 MCU_ActTrqValid "Motor actual torque valid status";
CM_ SG_ 152 MCU_ActualTorque "the actual torque of motor";
CM_ SG_ 152 MCU_UdcCurr "the actual voltage of udclink";
CM_ SG_ 152 MCU_IsCurr "the actual current";
CM_ SG_ 152 MCU_ActualSpeed "the actual motor speed";
CM_ SG_ 243 MCU_VCUWorkMode "the actual running mode of motor";
CM_ SG_ 594 MCU_TrqAbsMax "the maximum allowed torque of E-motor";
CM_ SG_ 594 MCU_TrqAbsMin "the minimum allowed torque of E-motor";
CM_ SG_ 594 MCU_StDischg "the discharge status";
CM_ SG_ 594 MCU_UT30Curr "the actual voltage of Tl30";
CM_ SG_ 594 MCU_UT15State "the active state of Tl15 KL15";
CM_ SG_ 594 MCU_ActUnfilteredRotSpd "Unfiltered motor speed";
CM_ SG_ 594 MCU_SpdMaxLimit "The maximum allowed speed of E-motor";
CM_ SG_ 595 Checksum_253 "Checksum signal for frame";
CM_ SG_ 595 MessageCounter_253 "Message counter signal for frame";
CM_ SG_ 595 MCU_FaultLevel "the failure code of E-motor which has the highest priority";
CM_ SG_ 929 MCU_HwVer "the version of hardware";
CM_ SG_ 928 MCU_CodeVer "the version of TC275 software code";
CM_ SG_ 928 MCU_DataVer "the version of TC275 software calibration data";
CM_ SG_ 928 MCU_CpldVer "the version of CPLD software";
CM_ SG_ 928 MCU_HvMcuVer "the version of Hv Mcu software";
CM_ SG_ 914 MCU_IGBTTempU "the temperature of U phase IGBT";
CM_ SG_ 914 MCU_IGBTTempV "the temperature of V phase IGBT";
CM_ SG_ 914 MCU_IGBTTempW "the temperature of W phase IGBT";
CM_ SG_ 914 MCU_IGBTTempMax "the temperature of Max phase IGBT";
CM_ SG_ 914 MCU_IGBTTempRiseU "the temperature rise of U phase IGBT";
CM_ SG_ 914 MCU_IGBTTempRiseV "the temperature rise of V phase IGBT";
CM_ SG_ 914 MCU_IGBTTempRiseW "the temperature rise of W phase IGBT";
CM_ SG_ 914 MCU_IGBTTempRiseMax "the temperature rise of Max phase IGBT";
CM_ SG_ 915 MCU_TempCurrCool "the temperature of coolant";
CM_ SG_ 915 MCU_TempCurrStr1 "the temperature of stator NTC1";
CM_ SG_ 915 MCU_TempCurrStr2 "the temperature of stator NTC2";
CM_ SG_ 915 MCU_TempCurrStrMax "the temperature of Max stator NTC";
CM_ SG_ 915 MCU_TempRiseCurrStr "the temperature of stator NTC1";
CM_ SG_ 915 MCU_TempStatus "The E-motor temperature state";
CM_ SG_ 673 Checksum_2A1 "Checksum signal for frame";
CM_ SG_ 673 MessageCounter_2A1 "Message counter signal for frame";
CM_ SG_ 673 MFP_FC_LeftTurnLampFault "FL turn lamp fault signal";
CM_ SG_ 673 MFP_FC_RightTurnLampFault "FR turn lamp fault signal";
CM_ SG_ 673 MFP_FC_WelLightshowSts "Welcome Light show animation state signal";
CM_ SG_ 673 MFP_FC_FollowMeHomeSts "Follow Me Home animation state signal";
CM_ SG_ 673 MFP_FC_WelLightshowAniSts "Welcome light animation state signal";
CM_ SG_ 673 MFP_FC_FMHLightshowAniSts "Follow me home animation state signal";
CM_ SG_ 592 Checksum_250 "Checksum signal for frame";
CM_ SG_ 592 MessageCounter_250 "Message counter signal for frame";
CM_ SG_ 592 PAT_SteerWhLengthPos "Steering wheel length position feedback";
CM_ SG_ 592 PAT_SteerWhAnglePos "Steering wheel angle position feedback";
CM_ SG_ 592 PAT_EasyEntrySts "The PAT welcome function enables the signal";
CM_ SG_ 592 PAT_MotorFaultWarn "Steering wheel motor malfunction warning";
CM_ SG_ 592 PAT_StWMemoryLengthPos "Locally stored steering wheel length position";
CM_ SG_ 592 PAT_StWMemoryAnglePos "Locally stored steering wheel angle position";
CM_ SG_ 578 POD_DCDC_HVInputVoltage "Voltage at high voltage side";
CM_ SG_ 578 POD_DCDC_WorkMode "State DCDC converter";
CM_ SG_ 578 POD_DCDC_LVOutputCurrent "Current on low voltage side";
CM_ SG_ 578 POD_DCDC_HVInputCurrent "Current at high voltage side";
CM_ SG_ 578 POD_DCDC_LVOutputVoltage "Voltage on low voltage side";
CM_ SG_ 770 POD_DCDC_FaultLevel "0x0: No Fault;
0x1: Minor faults.The drive performance of the whole vehicle has no influence on the parts, the output power is not limited, the function is affected to a certain extent, and the instrument alarm prompts. The component records the corresponding fault code
0x2: Recoverable malfunctions,Light the meter fault light and record the fault code. drive speed should be limited with 60km/h.the fault code of the faulty parts is recorded, limit LV power and the ICU lights up the system fault light and DCDC fault indicator.
0x3: Unrecoverable malfunctions,The function and performance of the whole vehicle are affected, drive speed should be limited with 60km/h.the fault code of the faulty parts is recorded, limit LV power and the ICU lights up the system fault light and DCDC fault indicator.";
CM_ SG_ 770 POD_DCDC_OutputCurrentHighFault "DCDC output overcurrent fault";
CM_ SG_ 770 POD_DCDC_InputVoltHighFault "DCDC input overvoltage fault";
CM_ SG_ 770 POD_DCDC_InputVoltLowFault "DCDC input undervoltage fault";
CM_ SG_ 770 POD_DCDC_OutputVoltHighFault "DCDC output overvoltage fault";
CM_ SG_ 770 POD_DCDC_OutputVoltLowFault "DCDC output undervoltage fault";
CM_ SG_ 770 POD_DCDC_Outputopencircuiterror "DCDC output open circuit error";
CM_ SG_ 770 POD_DCDC_Side2Overtempfault "DCDC Secordary side overtemperature fault";
CM_ SG_ 770 POD_DCDC_OutCurSensorFault "DCDC the low-side current sensor is faulty";
CM_ SG_ 770 POD_DCDC_OutputTempSensorFault "DCDC the low-voltage side temperature sensor is faulty";
CM_ SG_ 770 POD_DCDC_InternalFault "DCDC internal error";
CM_ SG_ 770 POD_DCDC_SecondarySideTemp "This signal is sent to TMS,according to this signal, TCU control the temporature of water";
CM_ SG_ 770 POD_DCDC_Maxoutputpower "DCDC maximum out put power at present condition";
CM_ SG_ 581 POD_OBC_CPCurrentLimit "Maximum AC current of infrastructure signalled by charging station with Duty-Cycle on the CP-PWM-Signal.";
CM_ SG_ 581 POD_OBC_CCStatus "OBC CC status";
CM_ SG_ 581 POD_OBC_CPStatus "Feedback the connected status of CP to VCU";
CM_ SG_ 581 POD_OBC_CCCurrentLimit "Maximum AC current of vehicle plug and cable detected by the EV.
For different charging plugs and cables e.g. with lower current performance then the charging station there are seperate values of resistors (RC and R4) inside the charging plug";
CM_ SG_ 581 POD_OBC_CPFrequency "CP frequency";
CM_ SG_ 581 POD_OBC_WorkMode "Idle when OBC shut up & be able to send message /
Readywhen OBC finish init. & itself detec./Charging/
Faultwhen OBC Fault Level=Recoverable fault,stop output but not power down
/Level=Unrecoverable fault,stop output and pow.down
/Stopstop pow.down";
CM_ SG_ 581 POD_OBC_CPDuty "CP Duty";
CM_ SG_ 581 POD_OBC_EMLockState "Give feedback of EM lock status to VCU";
CM_ SG_ 581 POD_OBC_ChargCapacibility "single-phase or three-phase";
CM_ SG_ 581 POD_OBC_S2State "Give feedback of S2 status to VCU";
CM_ SG_ 581 POD_OBC_OBCMaxPermOutpCrrt "Report OBC Max Permit Output Current";
CM_ SG_ 580 POD_OBC_ChrgOutpPwrAvl "Report the maximum output power at present.Positive is charge, negative is discharge.";
CM_ SG_ 580 POD_OBC_OutputDCChargeCurrent "OBC output current when charge.Positive is charge, negative is discharge.";
CM_ SG_ 580 POD_OBC_ACPortTempA "Actual temperatur connector A";
CM_ SG_ 580 POD_OBC_ACPortTempB "Actual temperatur connector B";
CM_ SG_ 580 POD_OBC_ACFrequencyStatus "AC side frequency when charge and discharge";
CM_ SG_ 580 POD_OBC_OutputDCChargeVoltage "OutputDCChargeVoltage,Positive is charge, negative is discharge";
CM_ SG_ 787 POD_OBC_ACPortTempASensValid "Error state for the temperature sensor. E.g. damaged or short circuit at the temperature sensor in the inlet.";
CM_ SG_ 787 POD_OBC_ACPortTempBSensValid "Error state for the temperature sensor. E.g. damaged or short circuit at the temperature sensor in the inlet.";
CM_ SG_ 787 POD_OBC_ACPortTempAerror "Sensor A over temporature error";
CM_ SG_ 787 POD_OBC_ACPortTempBerror "Sensor B over temporature errorr";
CM_ SG_ 787 POD_OBC_FaultLevel "0x0: Charge&discharge normally
0x1: Charge&discharge abnormally,but The whole vehicle is charged with limited power, and the corresponding fault code is recorded for the parts. When the fault is lifted, the maximum charging capacity is restored, and the instrument alarm lights up the system fault light.
0x2: Vehicle charging is suspended, parts record the corresponding fault code, instrument alarm display, charging indicator light alarm prompt, after the fault is restored, recharge normally, if the fault cannot be recovered after several restarts, the charging will end.
0x3: Stop charging, disconnect the charging contactor, the instrument lights up the system fault lights, and the parts record the corresponding fault code";
CM_ SG_ 787 POD_OBC_DCVoltHighFault "Charger DC side overvoltage fault(charge and discharge)";
CM_ SG_ 787 POD_OBC_StartUpAllowed "OBC startup status(charge and discharge)";
CM_ SG_ 787 POD_OBC_CommunFault "OBC communication fault with VCU and BMS(charge and discharge)";
CM_ SG_ 787 POD_OBC_DCCurHighFault "Charger DC side over current fault(charge and discharge)";
CM_ SG_ 787 POD_OBC_ACVoltHighFault "Charger AC side overvoltage fault(charge and discharge)";
CM_ SG_ 787 POD_OBC_ACVoltLowFault "Charger AC side undervoltage fault(charge and discharge)";
CM_ SG_ 787 POD_OBC_NlineStatus "Whether AC side N line disconnect(charge and discharge)";
CM_ SG_ 787 POD_OBC_OutputoverloadFault "OBC_OutputoverloadFault";
CM_ SG_ 787 POD_OBC_InputFrequencyStatus "Whether AC side frequency abnormal(charge and discharge)";
CM_ SG_ 787 POD_OBC_InputPhaseStatus "Whether AC side Lack of input phase(charge and discharge)";
CM_ SG_ 787 POD_OBC_InputOverCurrentstatus_R "PFC input over current between L1 and N(charge and discharge)";
CM_ SG_ 787 POD_OBC_InputOverCurrentstatus_S "PFC input over current between L2 and N";
CM_ SG_ 787 POD_OBC_InputOverCurrentstatus_T "PFC input over current between L3 and N";
CM_ SG_ 787 POD_OBC_PFCUnderVoltageError "VBUS under voltage(charge and discharge)";
CM_ SG_ 787 POD_OBC_PFCOverVoltageError "VBUS over voltage(charge and discharge)";
CM_ SG_ 787 POD_OBC_OutputShortError "Output short(charge and discharge)";
CM_ SG_ 787 POD_OBC_Side1Overtempfault "Primary side overtemp,at primary side ,we have total three temporature check point, but we only need to check the maximum value error (charge and discharge)";
CM_ SG_ 787 POD_OBC_Side2Overtempfault "Secordary side overtemp (charge and discharge)";
CM_ SG_ 787 POD_OBC_InternalFault "OBC internal fault(internal error)";
CM_ SG_ 787 POD_OBC_DCVoltLowFault "Charger DC side undervoltage fault(charge and discharge)";
CM_ SG_ 787 POD_OBC_InputShortError "Input short （charge）";
CM_ SG_ 787 POD_DCDC_CommunFault "DCDCC communication fault with VCU";
CM_ SG_ 787 OBC_OutputIsolatedFault "Discharge isolated fault at AC side.（discharge）";
CM_ SG_ 787 POD_OBC_PrimarySideTemp "This signal is sent to TMS,according to this signal, TCU request reduce the temporature of water,and we have total three temporature check point, but we only need to check the maximum value (charge and discharge)";
CM_ SG_ 787 POD_OBC_SecondarySideTemp "This signal is sent to TMS,according to this signal, TCU request reduce the temporature of water.(charge and discharge)";
CM_ SG_ 585 POD_OBC_InputACCurrent_R "Report phase R currents,Positive is charge, negative is discharge";
CM_ SG_ 585 POD_OBC_InputACCurrent_S "Report phase S currents";
CM_ SG_ 585 POD_OBC_InputACCurrent_T "Report phase T currents";
CM_ SG_ 585 POD_OBC_InputACVoltage_R "Report phase R voltage,";
CM_ SG_ 585 POD_OBC_InputACVoltage_S "Report phase S voltage";
CM_ SG_ 585 POD_OBC_InputACVoltage_T "Report phase T voltage";
CM_ SG_ 576 POD_DCFCVoltage "DC relay out side voltage";
CM_ SG_ 576 POD_Temperature "This signal reflects the temperature of Coolant outlet";
CM_ SG_ 576 POD_DCInletTempA "Actual DC + temperatur connector";
CM_ SG_ 576 POD_DCInletTempB "Actual DC - temperatur connector";
CM_ SG_ 577 POD_DCPortInletTempBValid "Error state for the temperature sensor. E.g. damaged or short circuit at the temperature sensor in the inlet.";
CM_ SG_ 577 POD_DCPortInletTempAValid "Error state for the temperature sensor. E.g. damaged or short circuit at the temperature sensor in the inlet.";
CM_ SG_ 577 POD_DCPosRelayState "Give feedback of DC charge positive relay state";
CM_ SG_ 577 POD_KL30Error "KL30 error";
CM_ SG_ 577 POD_T15e_fault "Give feedback of T15e status";
CM_ SG_ 577 POD_CANBusoff "CAN  Busoff error";
CM_ SG_ 577 POD_TempHighFault "PCB overtemperature fault（environmental overtemprerature)";
CM_ SG_ 577 POD_TempSensor1Fault "POD temperature fault of the temporature Coolant outlet or structure";
CM_ SG_ 584 Checksum_248 "Checksum signal for frame";
CM_ SG_ 584 MessageCounter_248 "Message counter signal for frame";
CM_ SG_ 584 PRND_RNDbutton "RND Gear button";
CM_ SG_ 584 PRND_Pbutton "P button";
CM_ SG_ 584 PRND_Pbutton_FaultSts "P Fault Status";
CM_ SG_ 584 PRND_RNDbutton_FaultSts "RND Fault Status";
CM_ SG_ 661 Checksum_295 "Checksum signal for frame";
CM_ SG_ 661 MessageCounter_295 "Message counter signal for frame";
CM_ SG_ 661 SCU_L_DsSeatHeightPos "Seat height position feedback signal";
CM_ SG_ 661 SCU_L_DsSeatSlidePos "Seat slide position feedback signal";
CM_ SG_ 661 SCU_L_EasyEntrySts "Driver welcome enable status";
CM_ SG_ 661 SCU_L_MotorFaultWarn "Seat motor malfunction warning";
CM_ SG_ 661 SCU_L_DrSeatHeatSts "Main driver seat heating status signal";
CM_ SG_ 661 SCU_L_DsSeatBackPos "Seat backrest position feedback signal";
CM_ SG_ 661 SCU_L_WelcomeLevelSts "Seat welcome position level setting status";
CM_ SG_ 661 SCU_L_SeatInitializationsts "Driver Seat Initialization status";
CM_ SG_ 665 SCU_L_SeatMemoryHeightPos "Locally stored driver seat height position";
CM_ SG_ 665 SCU_L_SeatMemorySlidePos "Locally stored driver seat slide position";
CM_ SG_ 665 SCU_L_SeatMemoryBackPos "Locally stored driver seat backrest position";
CM_ SG_ 662 SCU_R_DsSeatHeightPos "Seat height position feedback signal";
CM_ SG_ 662 SCU_R_DsSeatSlidePos "Seat slide position feedback signal";
CM_ SG_ 662 SCU_R_EasyEntrySts "Passenger welcome enable status";
CM_ SG_ 662 SCU_R_PassSeatHeatSts "Passenger seat heating status signal";
CM_ SG_ 662 SCU_R_DsSeatBackPos "Seat backrest position feedback signal";
CM_ SG_ 662 SCU_R_WelcomeLevelSts "Seat welcome position level setting status";
CM_ SG_ 662 SCU_R_SeatInitializationsts "Passenger Seat Initialization status";
CM_ SG_ 572 SGW_TimingChargeSwitchStatus "SGW feedback results of appointment of charging settings";
CM_ SG_ 572 SGW_RemoteChrgFlapLockCtrlReq "SGW remote charging flap lock control request";
CM_ SG_ 572 SGW_RelockSet "Set auto re-lock via remote APP";
CM_ SG_ 572 SGW_RemoteActiveHorn "Mobile phone active horn";
CM_ SG_ 572 SGW_ChargeFormSet "Reservation charging mode";
CM_ SG_ 572 SGW_TimingChargefrquency "Appointment charging frquency signal";
CM_ SG_ 572 SGW_AppointChargeCmd "Appointment charging start/end command";
CM_ SG_ 572 SGW_DschrgOnOffSet "discharging turn ON or OFF set.";
CM_ SG_ 572 SGW_LockACPlug "Unlock electronic lock by IVI";
CM_ SG_ 572 SGW_NFCCloseDoorAndLockSet "Enable/Disable the 'Auto door closing&locking via NFC' on APP";
CM_ SG_ 572 SGW_HoodlockSet "Hood lock control remotely";
CM_ SG_ 573 SGW_DomeLampSet "SGW dome Lamp setting";
CM_ SG_ 573 SGW_AmbientLightOnOffSet "SGW atmosphere lamp switch control";
CM_ SG_ 573 SGW_AmbientLightBrightSet "SGW ambient light brightness set";
CM_ SG_ 573 SGW_AmbientLightColourSet "SGW colour set";
CM_ SG_ 573 SGW_OutsideUnlockModeSet "Outside unlock mode control remotely";
CM_ SG_ 573 SGW_ApproachingUnlockSet "Approaching unlock settings remotely";
CM_ SG_ 573 SGW_AwayLockSet "away lock settings remotely";
CM_ SG_ 573 SGW_AmbientLiAniSet "Ambient light animation set signal";
CM_ SG_ 573 SGW_WelLightshowAniSet "Mobile phone APP welcome light animation set signal";
CM_ SG_ 573 SGW_FMHLightshowAniSet "Mobile phone APP follow me home animation set signal";
CM_ SG_ 573 SGW_MFPColourSet "SGW color set";
CM_ SG_ 573 SGW_IMUWork_Sts "Tilt sensor work status";
CM_ SG_ 573 SGW_PriorSoundSet "Enable/Disable sound reminder prior door automatic via speaker on APP";
CM_ SG_ 573 SGW_FrontKeepOpenSet "Enable/Disable the “keep the front door opened” on APP";
CM_ SG_ 265 IVI_FLWinPosiCtlCmd "Driver window percentage control command";
CM_ SG_ 265 IVI_FL_BTFrontRearReq "Driver forward and backward request";
CM_ SG_ 265 IVI_FrontDoorAngleSet "IVI Front Door Angle Setting";
CM_ SG_ 265 IVI_RearDoorAngleSet "IVI rear door angle setting";
CM_ SG_ 265 IVI_FL_BTHeightMotorReq "Driver height request";
CM_ SG_ 265 IVI_FRWinPosiCtlCmd "Passenger window percentage control command";
CM_ SG_ 265 IVI_RLWinPosiCtlCmd "Left rear window percentage control command";
CM_ SG_ 265 IVI_FL_BTBackrestMotorReq "Driver backrest request";
CM_ SG_ 265 IVI_RRWinPosiCtlCmd "Right rear window percentage control command";
CM_ SG_ 265 IVI_FLWinCtlCmd "Driver window percentage control command via mobile phone";
CM_ SG_ 265 IVI_FRWinCtlCmd "Passenger window percentage control command via mobile phone";
CM_ SG_ 265 IVI_RLWinCtlCmd "Left rear window percentage control command via mobile phone";
CM_ SG_ 265 IVI_AlarmEnableSet "Bluetooth/SWP setting alarm status enable";
CM_ SG_ 265 IVI_RRWinCtlCmd "Right rear window percentage control command via mobile phone";
CM_ SG_ 265 IVI_AntiTheftReHornMode "Anti-theft horn alert mode";
CM_ SG_ 266 IVI_AmbientLightRthythmLumiLvSet "Rthythm luminance set";
CM_ SG_ 266 IVI_WiperServiceSet "Wiper Service Mode Request";
CM_ SG_ 266 IVI_AllDoorReq "IVI Four door opening and closing request";
CM_ SG_ 266 IVI_FLDoorReq "IVI Left Front Door Open/Close Request";
CM_ SG_ 266 IVI_FRDoorReq "IVI Right Front Door Open/Close Request";
CM_ SG_ 266 IVI_RLDoorReq "IVI Left Rear Door Open/Close Request";
CM_ SG_ 266 IVI_RRDoorReq "IVI Right Rear Door Open/Close Request";
CM_ SG_ 266 IVI_LeftKeyReHornMode "Horn reminder mode for keys left in the car";
CM_ SG_ 266 IVI_LockDoorOpenReHornMode "Reminder  Lock event with Open door state mode";
CM_ SG_ 266 IVI_BTAutoCloseWinFunSet "APP set auto closing window function";
CM_ SG_ 266 IVI_AutoCloseWinFunSet "Auto close window function setting via IVI";
CM_ SG_ 565 SGW_AlarmEnableSet "Remote APP/Atom HUB setting alarm status enable";
CM_ SG_ 565 SGW_ALM_MusicFrequencySet "Ambient light music rhythm setting";
CM_ SG_ 565 SGW_RemoteHVCtrlReq "SGW remote power control request";
CM_ SG_ 565 SGW_FL_BackrestMotorReq "Driver backrest request";
CM_ SG_ 565 SGW_DomeLampBrightSet "Mobile phone dome lamp brightness control signal";
CM_ SG_ 565 SGW_FL_FrontRearReq "Driver forward and backward request";
CM_ SG_ 565 SGW_FL_HeightMotorReq "Driver height request";
CM_ SG_ 565 SGW_WelLightshowOnOffSet "Welcome Light show mobile phone APP switch control";
CM_ SG_ 565 SGW_WelLightshowTimeSet "Mobile phone APP welcome light time set signal";
CM_ SG_ 565 SGW_TaxiArrIllReq "Mobile phone set taxi arrive illumination request signal";
CM_ SG_ 565 SGW_FollowMeHomeTimeSet "Mobile phone APP Follow me home time set signal";
CM_ SG_ 565 SGW_TaxiArriveSts "Mobile phone APP taxi arrive state signal";
CM_ SG_ 565 SGW_BookingCarReq "Booking car request";
CM_ SG_ 565 SGW_HazardWarnReq "The remote hazard warning require";
CM_ SG_ 565 SGW_FollowMeHomeSet "Follow me home set signal";
CM_ SG_ 688 SGW_TransferState "Transfer state";
CM_ SG_ 688 SGW_DriverIdentitySts "Vehicle mode driver identity mode status";
CM_ SG_ 688 SGW_MainModeSts "Vehicle mode main mode state";
CM_ SG_ 688 SGW_CustomerModeSts "Vehicle mode customer mode state";
CM_ SG_ 688 SGW_CareModeSts "Vehicle mode care mode status";
CM_ SG_ 688 SGW_EnergySaveModeSts "Vehicle mode energy save mode status";
CM_ SG_ 690 SGW_IMUWorkingSts "IMU working state";
CM_ SG_ 690 SGW_VehicleTiltSlopeX "Vehicle X-axis tilt slope";
CM_ SG_ 690 SGW_VehicleTiltSlopeY "Vehicle Y-axis tilt slope";
CM_ SG_ 691 IVI_NFCCloseDoorAndLockSet "NFC Close Door And Lock Setting";
CM_ SG_ 691 IVI_SelectLocationCommand "User location selection signal";
CM_ SG_ 691 SGW_CelSigSts "Cellular signal status";
CM_ SG_ 691 SGW_CelSigType "Cellular signal type";
CM_ SG_ 691 SGW_WifiSigSts "Wifi signal status";
CM_ SG_ 691 IVI_FrontWasherSpraySet "Front washer spray set";
CM_ SG_ 691 IVI_FR_FrontRearReq "Passenger forward and backward request";
CM_ SG_ 691 IVI_FR_HeightMotorReq "Passenger height request";
CM_ SG_ 691 IVI_FR_BackrestMotorReq "Passenger backrest request";
CM_ SG_ 691 IVI_FL_MirrorAdjust "Rearview mirror direction adjustment";
CM_ SG_ 691 IVI_FR_MirrorAdjust "Rearview mirror direction adjustment";
CM_ SG_ 691 IVI_Temperature "IVI Temperature  signal";
CM_ SG_ 268 SGW_PENFCAuthSt "NFC authorizes state event";
CM_ SG_ 268 SGW_GetNFCKeyCardsReq "SGW get all NFC ket card info request";
CM_ SG_ 268 SGW_NFCPairModeReq "NFC Paring mode Request";
CM_ SG_ 268 SGW_SecOCFV_10C "Freshness value";
CM_ SG_ 268 SGW_SecOCMAC_10C "Message authentication code";
CM_ SG_ 571 SGW_TimingChargeEndhour "Feedback charging stop time for appointment charging: hour";
CM_ SG_ 571 SGW_TimingChargeEndminute "Feedback charging stop time for appointment charging: minute";
CM_ SG_ 571 SGW_TimingChargeStarthour "Feedbackt charging start time for appointment charging: hour";
CM_ SG_ 571 SGW_TimingChargeStartminute "Feedback charging start time for appointment charging: minute";
CM_ SG_ 692 IVI_MirrorInterfaceMode "Exterior mirrors adjustment interface mode";
CM_ SG_ 692 IVI_VrState "Voice assistant Active/Inactive";
CM_ SG_ 850 SGW_KeyLowBatWarning "Fob battery low warning.";
CM_ SG_ 850 SGW_BLEPowerModeReq "CBM request Power ON";
CM_ SG_ 850 SGW_BLESystemReadyReq "CBM request ready";
CM_ SG_ 850 SGW_BLETailgateCtrlReq "Bluetoot control back door command";
CM_ SG_ 850 SGW_BLELockCtrlReq "Bluetooth key lock control command";
CM_ SG_ 850 SGW_BLEChrgFlaplockCtrlReq "Bluetooth key charging flap lock control command";
CM_ SG_ 850 SGW_BLEFLLockCtrlReq "Bluetooth key FL lock control command";
CM_ SG_ 850 SGW_BLEFRLockCtrlReq "Bluetooth key FR lock control command";
CM_ SG_ 850 SGW_BLERLLockCtrlReq "Bluetooth key RL lock control command";
CM_ SG_ 850 SGW_BLERRLockCtrlReq "Bluetooth key RR lock control command";
CM_ SG_ 695 SGW_ParkingActiveReq "BLE request to activate the RC function";
CM_ SG_ 695 SGW_DeleteAllDKReq "Request to delete All DK";
CM_ SG_ 695 SGW_DKDeleteSlotIDReq "DK delete request";
CM_ SG_ 695 SGW_BlePairingSet "Pairing request";
CM_ SG_ 695 SGW_DKAuthSts "DK Auth state";
CM_ SG_ 695 SGW_SecOCFV_2B7 "Freshness value";
CM_ SG_ 695 SGW_SecOCMAC_2B7 "Message authentication code";
CM_ SG_ 960 SGW_TripCounter "Trip counter";
CM_ SG_ 960 SGW_ResetCounter "Reset counter";
CM_ SG_ 960 SGW_SynMsgAuthenticator "Synchronization message authenticator";
CM_ SG_ 567 IVI_DomeLampBrightSet "Dome lamp brightness control signal";
CM_ SG_ 567 IVI_HeadLampHeightSet "The headlamp height set signal";
CM_ SG_ 567 IVI_DomeLampSet "Dome Lamp setting";
CM_ SG_ 567 IVI_PosnLmpSet "Position light control signal";
CM_ SG_ 567 IVI_DippedBeamSet "Dipped beam control signal";
CM_ SG_ 567 IVI_AutoLmpSet "Auto light control signal";
CM_ SG_ 567 IVI_FrntFogLmpSet "Front fog lamp setting signal";
CM_ SG_ 567 IVI_RearFogLmpSet "Rear fog set signal";
CM_ SG_ 567 IVI_AutoLampSenReq "The dipped beam headlamp automatic control sensitivity setting signal";
CM_ SG_ 567 IVI_WelcomeOnOffSet "Welcome set signal";
CM_ SG_ 567 IVI_FRDomeLampSet "Front dome lamp setting";
CM_ SG_ 567 IVI_RRDomeLampSet "Rear dome lamp setting";
CM_ SG_ 567 IVI_FollowMeHomeSet "follow me Home lighting function set signal";
CM_ SG_ 567 IVI_CornerLampSet "Auto corner lamp set signal";
CM_ SG_ 567 IVI_PassWelcomeOnOffSet "Passenger welcome set signal";
CM_ SG_ 567 IVI_MainBeamSet "Driving-beam headlamp setting signal";
CM_ SG_ 568 IVI_RearCameraWashingSet "RearCameraWashing";
CM_ SG_ 568 IVI_ApproachingUnlockSet "Approaching unlock settings";
CM_ SG_ 568 IVI_CentralLockSet "IVI central locking control";
CM_ SG_ 568 IVI_AwayLockSet "away lock settings";
CM_ SG_ 568 IVI_LeftChdLockSet "Left child lock switch signal";
CM_ SG_ 568 IVI_RightChdLockSet "Right child lock switch signal";
CM_ SG_ 568 IVI_OutsideUnlockModeSet "Outside unlock mode control";
CM_ SG_ 568 IVI_TailgateLogicLockSet "Tailgate logic lock control";
CM_ SG_ 568 IVI_LowVoltPowerCtrl "Low Voltage Power Control";
CM_ SG_ 568 IVI_RelockSet "Set auto re-lock via IVI";
CM_ SG_ 568 IVI_BT_LeftChdLockCtrlReq "Left child lock switch signal";
CM_ SG_ 568 IVI_BT_RightChdLockCtrlReq "Right child lock switch signal";
CM_ SG_ 568 IVI_GearTimesSet "R gear times set";
CM_ SG_ 569 SGW_RoleAccessSts "Role access state";
CM_ SG_ 569 SGW_FaceIDAuthenticationSuccess "FaceID Authentication Success";
CM_ SG_ 569 SGW_ImmobilizingEnable "Remote APP/Atom HUB setting Immobilizing";
CM_ SG_ 569 SGW_SecOCFV_239 "Freshness value";
CM_ SG_ 569 SGW_SecOCMAC_239 "Message authentication code";
CM_ SG_ 851 IVI_WelLightshowOnOffSet "Welcome Light show switch control";
CM_ SG_ 851 IVI_FMHLightshowAniSet "SWP follow me home animation set signal";
CM_ SG_ 851 IVI_CallAmbientLReq "Call in ambient light animation request signal";
CM_ SG_ 851 IVI_AmbientLiAniSet "Ambient light animation set signal";
CM_ SG_ 851 IVI_ALM_MusicFrequencySet "atmosphere light music rhythm setting";
CM_ SG_ 851 IVI_AmbientLightOnOffSet "atmosphere lamp switch control";
CM_ SG_ 851 IVI_AmbientLightColorSet "Color set";
CM_ SG_ 851 IVI_WelLightshowAniSet "SWP welcome light animation set signal";
CM_ SG_ 851 IVI_TaxiArrIllReq "SWP set taxi arrive illumination request signal";
CM_ SG_ 851 IVI_WelLightshowTimeSet "SWP welcome light time set signal";
CM_ SG_ 851 IVI_FollowMeHomeTimeSet "SWP follow me home time set signal";
CM_ SG_ 851 IVI_TaxiArriveSts "SWP taxi arrive state signal";
CM_ SG_ 570 IVI_RearWindHeating "Tailgate window heating signal";
CM_ SG_ 570 IVI_PowerOffDisplay "Power-down popup feedback";
CM_ SG_ 570 IVI_HoodlockSet "Hood control.";
CM_ SG_ 570 IVI_SteerWhHeatOnOffSet "Steering wheel heating control signal";
CM_ SG_ 570 IVI_RearMirrorHeating "EN: rear mirror Heating signal";
CM_ SG_ 570 IVI_FrontWiperSwitch "Front wipers mode selection";
CM_ SG_ 570 IVI_L_RearSeatHeatSet "Rear left seat heating level setting";
CM_ SG_ 570 IVI_R_RearSeatHeatSet "Rear right seat heating level setting";
CM_ SG_ 570 IVI_FrontWindHeatingSet "Windshield heating signal";
CM_ SG_ 570 IVI_ChrgFlapLockSet "IVI charging flap lock control";
CM_ SG_ 570 IVI_DIMONOFFCommand "DIM ON/OFF command";
CM_ SG_ 570 IVI_BacklightadjustSet "Backlight brightness control signal";
CM_ SG_ 570 IVI_AmbientLightBrightSet "IVI ambient light brightness set";
BA_DEF_ BO_  "GenMsgSendType" ENUM  "Cyclic","Event","IfActive","CE","CA","NoMsgSendType";
BA_DEF_ BO_  "GenMsgCycleTime" INT 0 0;
BA_DEF_ BO_  "GenMsgCycleTimeFast" INT 0 0;
BA_DEF_ BO_  "CANFD_BRS" ENUM  "0","1";
BA_DEF_ BO_  "GenMsgNrOfRepetition" INT 0 0;
BA_DEF_ BO_  "GenMsgDelayTime" INT 0 0;
BA_DEF_ BO_  "GenMsgILSupport" ENUM  "No","Yes";
BA_DEF_ BO_  "NmMessage" ENUM "No","Yes";
BA_DEF_ BO_  "DiagState" ENUM  "No","Yes";
BA_DEF_ BO_  "DiagRequest" ENUM  "No","Yes";
BA_DEF_ BO_  "DiagResponse" ENUM  "No","Yes";
BA_DEF_ BO_  "VFrameFormat" ENUM  "StandardCAN","ExtendedCAN","reserved","reserved","reserved","reserved","reserved","reserved","reserved","reserved","reserved","reserved","reserved","reserved","StandardCAN_FD","ExtendedCAN_FD";
BA_DEF_ SG_  "GenSigSendType" ENUM  "Cyclic","OnChange","OnWrite","IfActive","OnChangeWithRepetition","OnWriteWithRepetition","IfActiveWithRepetition","NoSigSendType","NotUsed","NotUsed","NotUsed","NotUsed","NotUsed";
BA_DEF_ SG_  "GenSigStartValue" INT 0 0;
BA_DEF_ SG_  "GenSigInvalidValue" INT 0 0;
BA_DEF_DEF_  "GenMsgSendType" "Cyclic";
BA_DEF_DEF_  "GenMsgCycleTime" 0;
BA_DEF_DEF_  "GenSigSendType" "Cyclic";
BA_DEF_DEF_  "GenSigStartValue" 0;
BA_DEF_DEF_  "GenSigInvalidValue" 0;
BA_DEF_DEF_  "GenMsgCycleTimeFast" 0;
BA_DEF_DEF_  "GenMsgNrOfRepetition" 0;
BA_DEF_DEF_  "GenMsgDelayTime" 0;
BA_DEF_DEF_  "CANFD_BRS" "1";
BA_DEF_DEF_  "GenMsgILSupport" "Yes";
BA_DEF_DEF_  "NmMessage" "No";
BA_DEF_DEF_  "DiagState" "No";
BA_DEF_DEF_  "DiagRequest" "No";
BA_DEF_DEF_  "DiagResponse" "No";
BA_DEF_DEF_  "VFrameFormat" "StandardCAN_FD";
BA_ "GenMsgSendType" BO_ 643 3;
BA_ "GenMsgCycleTime" BO_ 643 100;
BA_ "GenMsgCycleTimeFast" BO_ 643 20;
BA_ "GenMsgNrOfRepetition" BO_ 643 3;
BA_ "GenMsgDelayTime" BO_ 643 20;
BA_ "GenSigStartValue" SG_ 643 DCM_FR_CarSharingColorSts 31;
BA_ "GenSigStartValue" SG_ 643 DCM_FR_CarSharingTimeSts 4;
BA_ "GenSigStartValue" SG_ 643 DCM_FR_DoorFRAngle 127;
BA_ "GenSigInvalidValue" SG_ 643 DCM_FR_DoorFRAngle 127;
BA_ "GenSigSendType" SG_ 643 DCM_FR_LinkageAvoidanceReq 4;
BA_ "GenMsgCycleTime" BO_ 651 100;
BA_ "GenSigInvalidValue" SG_ 651 MessageCounter_28B 15;
BA_ "GenSigStartValue" SG_ 651 DCM_FR_AmbientTemperature 70;
BA_ "GenSigStartValue" SG_ 651 DCM_FR_RightMirrorHorizontalPos 254;
BA_ "GenSigInvalidValue" SG_ 651 DCM_FR_RightMirrorHorizontalPos 255;
BA_ "GenSigStartValue" SG_ 651 DCM_FR_RightMirrorVerticalPos 254;
BA_ "GenSigInvalidValue" SG_ 651 DCM_FR_RightMirrorVerticalPos 255;
BA_ "GenMsgCycleTime" BO_ 653 100;
BA_ "GenSigStartValue" SG_ 653 DCM_FR_MirrorTiltVerticalPos 254;
BA_ "GenSigInvalidValue" SG_ 653 DCM_FR_MirrorTiltVerticalPos 255;
BA_ "GenSigStartValue" SG_ 653 DCM_FR_MirrorTiltHorizontalPos 254;
BA_ "GenSigInvalidValue" SG_ 653 DCM_FR_MirrorTiltHorizontalPos 255;
BA_ "GenSigStartValue" SG_ 653 DCM_FR_MirrorMainVerticalPos 254;
BA_ "GenSigInvalidValue" SG_ 653 DCM_FR_MirrorMainVerticalPos 255;
BA_ "GenSigStartValue" SG_ 653 DCM_FR_MirrorMainHorizontalPos 254;
BA_ "GenSigInvalidValue" SG_ 653 DCM_FR_MirrorMainHorizontalPos 255;
BA_ "GenMsgSendType" BO_ 310 1;
BA_ "GenSigSendType" SG_ 310 DCM_FR_MirrorAdjustmentSts 4;
BA_ "GenSigSendType" SG_ 310 DCM_FR_MirrorFoldFaultSts 4;
BA_ "GenSigSendType" SG_ 310 DCM_FR_HandleFailReminder 4;
BA_ "GenSigSendType" SG_ 310 DCM_FR_PriorSoundReq 4;
BA_ "GenMsgSendType" BO_ 644 3;
BA_ "GenMsgCycleTime" BO_ 644 100;
BA_ "GenMsgCycleTimeFast" BO_ 644 20;
BA_ "GenMsgNrOfRepetition" BO_ 644 3;
BA_ "GenMsgDelayTime" BO_ 644 20;
BA_ "GenSigInvalidValue" SG_ 644 MessageCounter_284 15;
BA_ "GenSigStartValue" SG_ 644 DCM_RL_DoorRLAngle 127;
BA_ "GenSigInvalidValue" SG_ 644 DCM_RL_DoorRLAngle 127;
BA_ "GenSigSendType" SG_ 644 DCM_RL_LinkageAvoidanceReq 4;
BA_ "GenSigStartValue" SG_ 644 DCM_RL_CarSharingColorSts 31;
BA_ "GenSigStartValue" SG_ 644 DCM_RL_CarSharingTimeSts 4;
BA_ "GenMsgSendType" BO_ 311 1;
BA_ "GenSigSendType" SG_ 311 DCM_RL_PriorSoundReq 4;
BA_ "GenMsgSendType" BO_ 645 3;
BA_ "GenMsgCycleTime" BO_ 645 100;
BA_ "GenMsgCycleTimeFast" BO_ 645 20;
BA_ "GenMsgNrOfRepetition" BO_ 645 3;
BA_ "GenMsgDelayTime" BO_ 645 20;
BA_ "GenSigInvalidValue" SG_ 645 MessageCounter_285 15;
BA_ "GenSigStartValue" SG_ 645 DCM_RR_DoorRRAngle 127;
BA_ "GenSigInvalidValue" SG_ 645 DCM_RR_DoorRRAngle 127;
BA_ "GenSigSendType" SG_ 645 DCM_RR_LinkageAvoidanceReq 4;
BA_ "GenSigStartValue" SG_ 645 DCM_RR_CarSharingColorSts 31;
BA_ "GenSigStartValue" SG_ 645 DCM_RR_CarSharingTimeSts 4;
BA_ "GenMsgSendType" BO_ 312 1;
BA_ "GenSigSendType" SG_ 312 DCM_RR_PriorSoundReq 4;
BA_ "GenMsgCycleTime" BO_ 880 100;
BA_ "GenSigInvalidValue" SG_ 880 DCM_SDS_FL_SensorWorksts 5;
BA_ "GenMsgCycleTime" BO_ 881 100;
BA_ "GenSigInvalidValue" SG_ 881 DCM_SDS_FR_SensorWorksts 5;
BA_ "GenMsgCycleTime" BO_ 882 100;
BA_ "GenSigInvalidValue" SG_ 882 DCM_SDS_RL_SensorWorksts 5;
BA_ "GenMsgCycleTime" BO_ 883 100;
BA_ "GenSigInvalidValue" SG_ 883 DCM_SDS_RR_SensorWorksts 5;
BA_ "GenMsgCycleTime" BO_ 714 100;
BA_ "GenSigStartValue" SG_ 714 DIM_ScreenBrightnessSta 31;
BA_ "GenSigInvalidValue" SG_ 714 DIM_ScreenBrightnessSta 31;
BA_ "GenMsgCycleTime" BO_ 512 100;
BA_ "GenMsgCycleTime" BO_ 241 20;
BA_ "GenSigInvalidValue" SG_ 241 MessageCounter_0F1 15;
BA_ "GenMsgCycleTime" BO_ 240 20;
BA_ "GenSigInvalidValue" SG_ 240 MessageCounter_0F0 15;
BA_ "GenSigStartValue" SG_ 240 EPS_SteeringWheelAngleSpd 65534;
BA_ "GenSigInvalidValue" SG_ 240 EPS_SteeringWheelAngleSpd 65535;
BA_ "GenSigInvalidValue" SG_ 240 EPS_WarningLamp 3;
BA_ "GenSigStartValue" SG_ 240 EPS_SteeringWheelAngle 65534;
BA_ "GenSigInvalidValue" SG_ 240 EPS_SteeringWheelAngle 65535;
BA_ "GenSigStartValue" SG_ 240 EPS_TorsionBarTorque 254;
BA_ "GenSigInvalidValue" SG_ 240 EPS_TorsionBarTorque 255;
BA_ "GenMsgCycleTime" BO_ 614 100;
BA_ "GenMsgCycleTime" BO_ 615 100;
BA_ "GenSigInvalidValue" SG_ 615 EVCOM_CompBusVolt 511;
BA_ "GenMsgCycleTime" BO_ 640 100;
BA_ "GenSigInvalidValue" SG_ 640 MessageCounter_280 15;
BA_ "GenMsgCycleTime" BO_ 641 100;
BA_ "GenSigInvalidValue" SG_ 641 MessageCounter_281 15;
BA_ "GenMsgCycleTime" BO_ 660 100;
BA_ "GenMsgCycleTime" BO_ 658 500;
BA_ "GenSigStartValue" SG_ 658 HUD_BrightnessSet 5;
BA_ "GenSigInvalidValue" SG_ 658 HUD_BrightnessSet 31;
BA_ "GenSigInvalidValue" SG_ 658 HUD_OnOffSts 3;
BA_ "GenSigStartValue" SG_ 658 HUD_HeightSts 8;
BA_ "GenMsgCycleTime" BO_ 184 20;
BA_ "GenSigInvalidValue" SG_ 184 MessageCounter_0B8 15;
BA_ "GenMsgCycleTime" BO_ 183 20;
BA_ "GenSigInvalidValue" SG_ 183 MessageCounter_0B7 15;
BA_ "GenSigInvalidValue" SG_ 183 IBS_BrakeTypEcho 3;
BA_ "GenSigInvalidValue" SG_ 183 IBS_APSCrlReqEcho 3;
BA_ "GenSigInvalidValue" SG_ 183 IBS_APSModeEcho 3;
BA_ "GenMsgCycleTime" BO_ 178 20;
BA_ "GenSigInvalidValue" SG_ 178 MessageCounter_0B2 15;
BA_ "GenSigStartValue" SG_ 178 IBS_BrakePedalStatusValid 1;
BA_ "GenMsgCycleTime" BO_ 179 20;
BA_ "GenSigInvalidValue" SG_ 179 MessageCounter_0B3 15;
BA_ "GenSigInvalidValue" SG_ 179 IBS_EPBFunctionLamp 3;
BA_ "GenMsgCycleTime" BO_ 180 20;
BA_ "GenSigInvalidValue" SG_ 180 MessageCounter_0B4 15;
BA_ "GenMsgCycleTime" BO_ 186 20;
BA_ "GenSigInvalidValue" SG_ 186 MessageCounter_0BA 15;
BA_ "GenMsgCycleTime" BO_ 187 20;
BA_ "GenSigInvalidValue" SG_ 187 MessageCounter_0BB 15;
BA_ "GenMsgCycleTime" BO_ 188 20;
BA_ "GenSigInvalidValue" SG_ 188 MessageCounter_0BC 15;
BA_ "GenSigStartValue" SG_ 188 IBS_ESCOffSts 1;
BA_ "GenMsgCycleTime" BO_ 185 20;
BA_ "GenSigInvalidValue" SG_ 185 MessageCounter_0B9 15;
BA_ "GenMsgCycleTime" BO_ 144 10;
BA_ "GenSigInvalidValue" SG_ 144 MessageCounter_090 15;
BA_ "GenMsgCycleTime" BO_ 176 20;
BA_ "GenSigInvalidValue" SG_ 176 MessageCounter_0B0 15;
BA_ "GenMsgCycleTime" BO_ 177 20;
BA_ "GenSigInvalidValue" SG_ 177 MessageCounter_0B1 15;
BA_ "GenMsgCycleTime" BO_ 152 10;
BA_ "GenSigInvalidValue" SG_ 152 MessageCounter_098 15;
BA_ "GenSigStartValue" SG_ 152 MCU_ActualTorque 1023;
BA_ "GenSigInvalidValue" SG_ 152 MCU_ActualTorque 2047;
BA_ "GenSigInvalidValue" SG_ 152 MCU_UdcCurr 1023;
BA_ "GenSigStartValue" SG_ 152 MCU_IsCurr 1023;
BA_ "GenSigInvalidValue" SG_ 152 MCU_IsCurr 2047;
BA_ "GenSigStartValue" SG_ 152 MCU_ActualSpeed 32767;
BA_ "GenSigInvalidValue" SG_ 152 MCU_ActualSpeed 65535;
BA_ "GenMsgCycleTime" BO_ 243 20;
BA_ "GenMsgCycleTime" BO_ 594 100;
BA_ "GenSigStartValue" SG_ 594 MCU_TrqAbsMax 1023;
BA_ "GenSigInvalidValue" SG_ 594 MCU_TrqAbsMax 2047;
BA_ "GenSigStartValue" SG_ 594 MCU_TrqAbsMin 1023;
BA_ "GenSigInvalidValue" SG_ 594 MCU_TrqAbsMin 2047;
BA_ "GenSigInvalidValue" SG_ 594 MCU_UT30Curr 63;
BA_ "GenSigStartValue" SG_ 594 MCU_ActUnfilteredRotSpd 32767;
BA_ "GenSigInvalidValue" SG_ 594 MCU_ActUnfilteredRotSpd 65535;
BA_ "GenSigStartValue" SG_ 594 MCU_SpdMaxLimit 32767;
BA_ "GenSigInvalidValue" SG_ 594 MCU_SpdMaxLimit 65535;
BA_ "GenMsgCycleTime" BO_ 595 100;
BA_ "GenSigInvalidValue" SG_ 595 MessageCounter_253 15;
BA_ "GenMsgCycleTime" BO_ 929 1000;
BA_ "GenMsgCycleTime" BO_ 928 1000;
BA_ "GenMsgCycleTime" BO_ 914 500;
BA_ "GenSigInvalidValue" SG_ 914 MCU_IGBTTempU 255;
BA_ "GenSigInvalidValue" SG_ 914 MCU_IGBTTempV 255;
BA_ "GenSigInvalidValue" SG_ 914 MCU_IGBTTempW 255;
BA_ "GenSigInvalidValue" SG_ 914 MCU_IGBTTempMax 255;
BA_ "GenSigInvalidValue" SG_ 914 MCU_IGBTTempRiseU 255;
BA_ "GenSigInvalidValue" SG_ 914 MCU_IGBTTempRiseV 255;
BA_ "GenSigInvalidValue" SG_ 914 MCU_IGBTTempRiseW 255;
BA_ "GenSigInvalidValue" SG_ 914 MCU_IGBTTempRiseMax 255;
BA_ "GenMsgCycleTime" BO_ 915 500;
BA_ "GenSigStartValue" SG_ 915 MCU_TempCurrCool 255;
BA_ "GenSigInvalidValue" SG_ 915 MCU_TempCurrCool 255;
BA_ "GenSigStartValue" SG_ 915 MCU_TempCurrStr1 255;
BA_ "GenSigInvalidValue" SG_ 915 MCU_TempCurrStr1 255;
BA_ "GenSigStartValue" SG_ 915 MCU_TempCurrStr2 255;
BA_ "GenSigInvalidValue" SG_ 915 MCU_TempCurrStr2 255;
BA_ "GenSigStartValue" SG_ 915 MCU_TempCurrStrMax 255;
BA_ "GenSigInvalidValue" SG_ 915 MCU_TempCurrStrMax 255;
BA_ "GenSigInvalidValue" SG_ 915 MCU_TempRiseCurrStr 255;
BA_ "GenMsgCycleTime" BO_ 673 100;
BA_ "GenSigInvalidValue" SG_ 673 MessageCounter_2A1 15;
BA_ "GenSigStartValue" SG_ 673 MFP_FC_WelLightshowSts 1;
BA_ "GenSigStartValue" SG_ 673 MFP_FC_FollowMeHomeSts 1;
BA_ "GenMsgCycleTime" BO_ 592 100;
BA_ "GenSigInvalidValue" SG_ 592 MessageCounter_250 15;
BA_ "GenSigStartValue" SG_ 592 PAT_SteerWhLengthPos 254;
BA_ "GenSigInvalidValue" SG_ 592 PAT_SteerWhLengthPos 255;
BA_ "GenSigStartValue" SG_ 592 PAT_SteerWhAnglePos 254;
BA_ "GenSigInvalidValue" SG_ 592 PAT_SteerWhAnglePos 255;
BA_ "GenSigStartValue" SG_ 592 PAT_StWMemoryLengthPos 254;
BA_ "GenSigInvalidValue" SG_ 592 PAT_StWMemoryLengthPos 255;
BA_ "GenSigStartValue" SG_ 592 PAT_StWMemoryAnglePos 254;
BA_ "GenSigInvalidValue" SG_ 592 PAT_StWMemoryAnglePos 255;
BA_ "GenMsgCycleTime" BO_ 578 100;
BA_ "GenMsgCycleTime" BO_ 770 200;
BA_ "GenSigStartValue" SG_ 770 POD_DCDC_SecondarySideTemp 255;
BA_ "GenMsgCycleTime" BO_ 581 100;
BA_ "GenSigInvalidValue" SG_ 581 POD_OBC_CCStatus 10;
BA_ "GenSigStartValue" SG_ 581 POD_OBC_S2State 1;
BA_ "GenMsgCycleTime" BO_ 580 100;
BA_ "GenMsgCycleTime" BO_ 787 200;
BA_ "GenMsgCycleTime" BO_ 585 100;
BA_ "GenMsgCycleTime" BO_ 576 100;
BA_ "GenMsgCycleTime" BO_ 577 100;
BA_ "GenSigStartValue" SG_ 577 POD_DCPosRelayState 1;
BA_ "GenMsgSendType" BO_ 584 3;
BA_ "GenMsgCycleTime" BO_ 584 100;
BA_ "GenMsgCycleTimeFast" BO_ 584 20;
BA_ "GenMsgNrOfRepetition" BO_ 584 3;
BA_ "GenMsgDelayTime" BO_ 584 20;
BA_ "GenSigInvalidValue" SG_ 584 MessageCounter_248 15;
BA_ "GenSigSendType" SG_ 584 PRND_RNDbutton 5;
BA_ "GenSigSendType" SG_ 584 PRND_Pbutton 5;
BA_ "GenMsgCycleTime" BO_ 661 100;
BA_ "GenSigInvalidValue" SG_ 661 MessageCounter_295 15;
BA_ "GenSigStartValue" SG_ 661 SCU_L_DsSeatHeightPos 254;
BA_ "GenSigInvalidValue" SG_ 661 SCU_L_DsSeatHeightPos 255;
BA_ "GenSigStartValue" SG_ 661 SCU_L_DsSeatSlidePos 254;
BA_ "GenSigInvalidValue" SG_ 661 SCU_L_DsSeatSlidePos 255;
BA_ "GenSigStartValue" SG_ 661 SCU_L_DsSeatBackPos 254;
BA_ "GenSigInvalidValue" SG_ 661 SCU_L_DsSeatBackPos 255;
BA_ "GenMsgCycleTime" BO_ 665 100;
BA_ "GenSigStartValue" SG_ 665 SCU_L_SeatMemoryHeightPos 254;
BA_ "GenSigInvalidValue" SG_ 665 SCU_L_SeatMemoryHeightPos 255;
BA_ "GenSigStartValue" SG_ 665 SCU_L_SeatMemorySlidePos 254;
BA_ "GenSigInvalidValue" SG_ 665 SCU_L_SeatMemorySlidePos 255;
BA_ "GenSigStartValue" SG_ 665 SCU_L_SeatMemoryBackPos 254;
BA_ "GenSigInvalidValue" SG_ 665 SCU_L_SeatMemoryBackPos 255;
BA_ "GenMsgCycleTime" BO_ 662 100;
BA_ "GenSigStartValue" SG_ 662 SCU_R_DsSeatHeightPos 254;
BA_ "GenSigInvalidValue" SG_ 662 SCU_R_DsSeatHeightPos 255;
BA_ "GenSigStartValue" SG_ 662 SCU_R_DsSeatSlidePos 254;
BA_ "GenSigInvalidValue" SG_ 662 SCU_R_DsSeatSlidePos 255;
BA_ "GenSigStartValue" SG_ 662 SCU_R_DsSeatBackPos 254;
BA_ "GenSigInvalidValue" SG_ 662 SCU_R_DsSeatBackPos 255;
BA_ "GenMsgSendType" BO_ 572 3;
BA_ "GenMsgCycleTime" BO_ 572 100;
BA_ "GenMsgCycleTimeFast" BO_ 572 20;
BA_ "GenMsgNrOfRepetition" BO_ 572 3;
BA_ "GenMsgDelayTime" BO_ 572 20;
BA_ "GenSigSendType" SG_ 572 SGW_RemoteChrgFlapLockCtrlReq 4;
BA_ "GenSigSendType" SG_ 572 SGW_RelockSet 4;
BA_ "GenSigSendType" SG_ 572 SGW_RemoteActiveHorn 4;
BA_ "GenSigSendType" SG_ 572 SGW_AppointChargeCmd 4;
BA_ "GenSigSendType" SG_ 572 SGW_DschrgOnOffSet 4;
BA_ "GenSigInvalidValue" SG_ 572 SGW_DschrgOnOffSet 3;
BA_ "GenSigSendType" SG_ 572 SGW_LockACPlug 4;
BA_ "GenSigSendType" SG_ 572 SGW_NFCCloseDoorAndLockSet 4;
BA_ "GenSigSendType" SG_ 572 SGW_HoodlockSet 4;
BA_ "GenMsgSendType" BO_ 573 3;
BA_ "GenMsgCycleTime" BO_ 573 100;
BA_ "GenMsgCycleTimeFast" BO_ 573 20;
BA_ "GenMsgNrOfRepetition" BO_ 573 3;
BA_ "GenMsgDelayTime" BO_ 573 20;
BA_ "GenSigSendType" SG_ 573 SGW_DomeLampSet 4;
BA_ "GenSigSendType" SG_ 573 SGW_AmbientLightOnOffSet 4;
BA_ "GenSigSendType" SG_ 573 SGW_AmbientLightBrightSet 4;
BA_ "GenSigSendType" SG_ 573 SGW_AmbientLightColourSet 4;
BA_ "GenSigSendType" SG_ 573 SGW_OutsideUnlockModeSet 4;
BA_ "GenSigInvalidValue" SG_ 573 SGW_OutsideUnlockModeSet 3;
BA_ "GenSigSendType" SG_ 573 SGW_ApproachingUnlockSet 4;
BA_ "GenSigInvalidValue" SG_ 573 SGW_ApproachingUnlockSet 3;
BA_ "GenSigSendType" SG_ 573 SGW_AwayLockSet 4;
BA_ "GenSigInvalidValue" SG_ 573 SGW_AwayLockSet 3;
BA_ "GenSigSendType" SG_ 573 SGW_AmbientLiAniSet 4;
BA_ "GenSigSendType" SG_ 573 SGW_WelLightshowAniSet 4;
BA_ "GenSigSendType" SG_ 573 SGW_FMHLightshowAniSet 4;
BA_ "GenSigSendType" SG_ 573 SGW_MFPColourSet 4;
BA_ "GenSigSendType" SG_ 573 SGW_PriorSoundSet 4;
BA_ "GenSigSendType" SG_ 573 SGW_FrontKeepOpenSet 4;
BA_ "GenMsgSendType" BO_ 265 1;
BA_ "GenMsgCycleTimeFast" BO_ 265 20;
BA_ "GenMsgNrOfRepetition" BO_ 265 3;
BA_ "GenMsgDelayTime" BO_ 265 20;
BA_ "GenSigSendType" SG_ 265 IVI_FLWinPosiCtlCmd 4;
BA_ "GenSigSendType" SG_ 265 IVI_FL_BTFrontRearReq 4;
BA_ "GenSigSendType" SG_ 265 IVI_FrontDoorAngleSet 4;
BA_ "GenSigSendType" SG_ 265 IVI_RearDoorAngleSet 4;
BA_ "GenSigSendType" SG_ 265 IVI_FL_BTHeightMotorReq 4;
BA_ "GenSigSendType" SG_ 265 IVI_FRWinPosiCtlCmd 4;
BA_ "GenSigSendType" SG_ 265 IVI_RLWinPosiCtlCmd 4;
BA_ "GenSigSendType" SG_ 265 IVI_FL_BTBackrestMotorReq 4;
BA_ "GenSigSendType" SG_ 265 IVI_RRWinPosiCtlCmd 4;
BA_ "GenSigSendType" SG_ 265 IVI_FLWinCtlCmd 4;
BA_ "GenSigSendType" SG_ 265 IVI_FRWinCtlCmd 4;
BA_ "GenSigSendType" SG_ 265 IVI_RLWinCtlCmd 4;
BA_ "GenSigSendType" SG_ 265 IVI_AlarmEnableSet 4;
BA_ "GenSigSendType" SG_ 265 IVI_RRWinCtlCmd 4;
BA_ "GenSigSendType" SG_ 265 IVI_AntiTheftReHornMode 4;
BA_ "GenMsgSendType" BO_ 266 1;
BA_ "GenMsgCycleTimeFast" BO_ 266 20;
BA_ "GenMsgNrOfRepetition" BO_ 266 3;
BA_ "GenMsgDelayTime" BO_ 266 20;
BA_ "GenSigSendType" SG_ 266 IVI_AmbientLightRthythmLumiLvSet 4;
BA_ "GenSigSendType" SG_ 266 IVI_WiperServiceSet 4;
BA_ "GenSigSendType" SG_ 266 IVI_AllDoorReq 4;
BA_ "GenSigSendType" SG_ 266 IVI_FLDoorReq 4;
BA_ "GenSigSendType" SG_ 266 IVI_FRDoorReq 4;
BA_ "GenSigSendType" SG_ 266 IVI_RLDoorReq 4;
BA_ "GenSigSendType" SG_ 266 IVI_RRDoorReq 4;
BA_ "GenSigSendType" SG_ 266 IVI_LeftKeyReHornMode 4;
BA_ "GenSigSendType" SG_ 266 IVI_LockDoorOpenReHornMode 4;
BA_ "GenSigSendType" SG_ 266 IVI_BTAutoCloseWinFunSet 4;
BA_ "GenSigSendType" SG_ 266 IVI_AutoCloseWinFunSet 4;
BA_ "GenMsgSendType" BO_ 565 3;
BA_ "GenMsgCycleTime" BO_ 565 100;
BA_ "GenMsgCycleTimeFast" BO_ 565 20;
BA_ "GenMsgNrOfRepetition" BO_ 565 3;
BA_ "GenMsgDelayTime" BO_ 565 20;
BA_ "GenSigSendType" SG_ 565 SGW_AlarmEnableSet 4;
BA_ "GenSigSendType" SG_ 565 SGW_ALM_MusicFrequencySet 4;
BA_ "GenSigSendType" SG_ 565 SGW_FL_BackrestMotorReq 4;
BA_ "GenSigSendType" SG_ 565 SGW_DomeLampBrightSet 4;
BA_ "GenSigSendType" SG_ 565 SGW_FL_FrontRearReq 4;
BA_ "GenSigSendType" SG_ 565 SGW_FL_HeightMotorReq 4;
BA_ "GenSigSendType" SG_ 565 SGW_WelLightshowOnOffSet 4;
BA_ "GenSigSendType" SG_ 565 SGW_WelLightshowTimeSet 4;
BA_ "GenSigSendType" SG_ 565 SGW_TaxiArrIllReq 4;
BA_ "GenSigSendType" SG_ 565 SGW_FollowMeHomeTimeSet 4;
BA_ "GenSigSendType" SG_ 565 SGW_TaxiArriveSts 4;
BA_ "GenSigSendType" SG_ 565 SGW_BookingCarReq 4;
BA_ "GenSigStartValue" SG_ 565 SGW_BookingCarReq 2;
BA_ "GenSigSendType" SG_ 565 SGW_HazardWarnReq 4;
BA_ "GenSigSendType" SG_ 565 SGW_FollowMeHomeSet 4;
BA_ "GenMsgCycleTime" BO_ 688 100;
BA_ "GenMsgCycleTime" BO_ 690 100;
BA_ "GenMsgCycleTime" BO_ 691 100;
BA_ "GenSigStartValue" SG_ 691 IVI_Temperature 41;
BA_ "GenMsgSendType" BO_ 268 1;
BA_ "GenSigSendType" SG_ 268 SGW_PENFCAuthSt 1;
BA_ "GenSigSendType" SG_ 268 SGW_GetNFCKeyCardsReq 1;
BA_ "GenSigSendType" SG_ 268 SGW_NFCPairModeReq 1;
BA_ "GenSigSendType" SG_ 268 SGW_SecOCFV_10C 1;
BA_ "GenSigSendType" SG_ 268 SGW_SecOCMAC_10C 1;
BA_ "GenMsgCycleTime" BO_ 571 100;
BA_ "GenSigInvalidValue" SG_ 571 SGW_TimingChargeEndhour 31;
BA_ "GenSigInvalidValue" SG_ 571 SGW_TimingChargeEndminute 63;
BA_ "GenSigInvalidValue" SG_ 571 SGW_TimingChargeStarthour 31;
BA_ "GenSigInvalidValue" SG_ 571 SGW_TimingChargeStartminute 63;
BA_ "GenMsgCycleTime" BO_ 692 100;
BA_ "GenMsgSendType" BO_ 850 3;
BA_ "GenMsgCycleTime" BO_ 850 200;
BA_ "GenMsgCycleTimeFast" BO_ 850 20;
BA_ "GenMsgNrOfRepetition" BO_ 850 3;
BA_ "GenMsgDelayTime" BO_ 850 20;
BA_ "GenSigSendType" SG_ 850 SGW_BLESystemReadyReq 4;
BA_ "GenSigSendType" SG_ 850 SGW_BLETailgateCtrlReq 4;
BA_ "GenSigSendType" SG_ 850 SGW_BLELockCtrlReq 4;
BA_ "GenSigSendType" SG_ 850 SGW_BLEChrgFlaplockCtrlReq 4;
BA_ "GenSigSendType" SG_ 850 SGW_BLEFLLockCtrlReq 4;
BA_ "GenSigSendType" SG_ 850 SGW_BLEFRLockCtrlReq 4;
BA_ "GenSigSendType" SG_ 850 SGW_BLERLLockCtrlReq 4;
BA_ "GenSigSendType" SG_ 850 SGW_BLERRLockCtrlReq 4;
BA_ "GenMsgSendType" BO_ 695 3;
BA_ "GenMsgCycleTime" BO_ 695 100;
BA_ "GenMsgCycleTimeFast" BO_ 695 20;
BA_ "GenMsgNrOfRepetition" BO_ 695 3;
BA_ "GenMsgDelayTime" BO_ 695 20;
BA_ "GenSigSendType" SG_ 695 SGW_DeleteAllDKReq 4;
BA_ "GenSigSendType" SG_ 695 SGW_DKDeleteSlotIDReq 4;
BA_ "GenMsgCycleTime" BO_ 960 30000;
BA_ "GenMsgSendType" BO_ 567 1;
BA_ "GenMsgCycleTimeFast" BO_ 567 20;
BA_ "GenMsgNrOfRepetition" BO_ 567 3;
BA_ "GenMsgDelayTime" BO_ 567 20;
BA_ "GenSigSendType" SG_ 567 IVI_DomeLampBrightSet 4;
BA_ "GenSigSendType" SG_ 567 IVI_HeadLampHeightSet 4;
BA_ "GenSigSendType" SG_ 567 IVI_DomeLampSet 4;
BA_ "GenSigSendType" SG_ 567 IVI_PosnLmpSet 4;
BA_ "GenSigSendType" SG_ 567 IVI_DippedBeamSet 4;
BA_ "GenSigSendType" SG_ 567 IVI_AutoLmpSet 4;
BA_ "GenSigSendType" SG_ 567 IVI_FrntFogLmpSet 4;
BA_ "GenSigSendType" SG_ 567 IVI_RearFogLmpSet 4;
BA_ "GenSigSendType" SG_ 567 IVI_AutoLampSenReq 4;
BA_ "GenSigSendType" SG_ 567 IVI_WelcomeOnOffSet 4;
BA_ "GenSigSendType" SG_ 567 IVI_FRDomeLampSet 4;
BA_ "GenSigSendType" SG_ 567 IVI_RRDomeLampSet 4;
BA_ "GenSigSendType" SG_ 567 IVI_FollowMeHomeSet 4;
BA_ "GenSigSendType" SG_ 567 IVI_CornerLampSet 4;
BA_ "GenSigSendType" SG_ 567 IVI_PassWelcomeOnOffSet 4;
BA_ "GenSigSendType" SG_ 567 IVI_MainBeamSet 4;
BA_ "GenMsgSendType" BO_ 568 1;
BA_ "GenMsgCycleTimeFast" BO_ 568 20;
BA_ "GenMsgNrOfRepetition" BO_ 568 3;
BA_ "GenMsgDelayTime" BO_ 568 20;
BA_ "GenSigSendType" SG_ 568 IVI_RearCameraWashingSet 4;
BA_ "GenSigSendType" SG_ 568 IVI_ApproachingUnlockSet 4;
BA_ "GenSigSendType" SG_ 568 IVI_CentralLockSet 4;
BA_ "GenSigSendType" SG_ 568 IVI_AwayLockSet 4;
BA_ "GenSigSendType" SG_ 568 IVI_LeftChdLockSet 4;
BA_ "GenSigSendType" SG_ 568 IVI_RightChdLockSet 4;
BA_ "GenSigSendType" SG_ 568 IVI_OutsideUnlockModeSet 4;
BA_ "GenSigSendType" SG_ 568 IVI_TailgateLogicLockSet 4;
BA_ "GenSigSendType" SG_ 568 IVI_LowVoltPowerCtrl 4;
BA_ "GenSigSendType" SG_ 568 IVI_RelockSet 4;
BA_ "GenSigSendType" SG_ 568 IVI_BT_LeftChdLockCtrlReq 4;
BA_ "GenSigSendType" SG_ 568 IVI_BT_RightChdLockCtrlReq 4;
BA_ "GenSigSendType" SG_ 568 IVI_GearTimesSet 4;
BA_ "GenMsgSendType" BO_ 569 3;
BA_ "GenMsgCycleTime" BO_ 569 100;
BA_ "GenMsgCycleTimeFast" BO_ 569 20;
BA_ "GenMsgNrOfRepetition" BO_ 569 3;
BA_ "GenMsgDelayTime" BO_ 569 20;
BA_ "GenSigSendType" SG_ 569 SGW_ImmobilizingEnable 4;
BA_ "GenMsgSendType" BO_ 851 1;
BA_ "GenMsgCycleTimeFast" BO_ 851 20;
BA_ "GenMsgNrOfRepetition" BO_ 851 3;
BA_ "GenMsgDelayTime" BO_ 851 20;
BA_ "GenSigSendType" SG_ 851 IVI_WelLightshowOnOffSet 4;
BA_ "GenSigSendType" SG_ 851 IVI_FMHLightshowAniSet 4;
BA_ "GenSigSendType" SG_ 851 IVI_CallAmbientLReq 4;
BA_ "GenSigSendType" SG_ 851 IVI_AmbientLiAniSet 4;
BA_ "GenSigSendType" SG_ 851 IVI_ALM_MusicFrequencySet 4;
BA_ "GenSigSendType" SG_ 851 IVI_AmbientLightOnOffSet 4;
BA_ "GenSigSendType" SG_ 851 IVI_AmbientLightColorSet 4;
BA_ "GenSigSendType" SG_ 851 IVI_WelLightshowAniSet 4;
BA_ "GenSigSendType" SG_ 851 IVI_TaxiArrIllReq 4;
BA_ "GenSigSendType" SG_ 851 IVI_WelLightshowTimeSet 4;
BA_ "GenSigSendType" SG_ 851 IVI_FollowMeHomeTimeSet 4;
BA_ "GenSigSendType" SG_ 851 IVI_TaxiArriveSts 4;
BA_ "GenMsgSendType" BO_ 570 1;
BA_ "GenMsgCycleTimeFast" BO_ 570 20;
BA_ "GenMsgNrOfRepetition" BO_ 570 3;
BA_ "GenMsgDelayTime" BO_ 570 20;
BA_ "GenSigSendType" SG_ 570 IVI_RearWindHeating 4;
BA_ "GenSigSendType" SG_ 570 IVI_PowerOffDisplay 4;
BA_ "GenSigSendType" SG_ 570 IVI_HoodlockSet 4;
BA_ "GenSigSendType" SG_ 570 IVI_SteerWhHeatOnOffSet 4;
BA_ "GenSigSendType" SG_ 570 IVI_RearMirrorHeating 4;
BA_ "GenSigSendType" SG_ 570 IVI_FrontWiperSwitch 4;
BA_ "GenSigSendType" SG_ 570 IVI_L_RearSeatHeatSet 4;
BA_ "GenSigSendType" SG_ 570 IVI_R_RearSeatHeatSet 4;
BA_ "GenSigSendType" SG_ 570 IVI_FrontWindHeatingSet 4;
BA_ "GenSigSendType" SG_ 570 IVI_ChrgFlapLockSet 4;
BA_ "GenSigSendType" SG_ 570 IVI_DIMONOFFCommand 4;
BA_ "GenSigSendType" SG_ 570 IVI_BacklightadjustSet 4;
BA_ "GenSigSendType" SG_ 570 IVI_AmbientLightBrightSet 4;
VAL_ 643 DCM_FR_CarSharingColorSts 0 "Colour1" 1 "Colour2" 2 "Colour3" 3 "Colour4" 4 "Colour5" 5 "Colour6" 6 "Colour7" 7 "Colour8" 8 "Colour9" 9 "Colour10" 10 "Colour11" 11 "Colour12" 12 "Colour13" 13 "Colour14" 14 "Colour15" 15 "Colour16" 16 "Colour17" 17 "Colour18" 18 "Colour19" 19 "Colour20" 20 "Colour21" 21 "Colour22" 22 "Colour23" 23 "Colour24" 24 "Colour25" 25 "Colour26" 26 "Colour27" 27 "Colour28" 28 "Colour29" 29 "Colour30" 30 "Colour31" 31 "Colour32" 32 "Colour33" 33 "Colour34" 34 "Colour35" 35 "Colour36" 36 "Colour37" 37 "Colour38" 38 "Colour39" 39 "Colour40" 40 "Colour41" 41 "Colour42" 42 "Colour43" 43 "Colour44" 44 "Colour45" 45 "Colour46" 46 "Colour47" 47 "Colour48" 48 "Colour49" 49 "Colour50" 50 "Colour51" 51 "Colour52" 52 "Colour53" 53 "Colour54" 54 "Colour55" 55 "Colour56" 56 "Colour57" 57 "Colour58" 58 "Colour59" 59 "Colour60" 60 "Colour61" 61 "Colour62" 62 "Colour63" 63 "Colour64" 64 "Reserved" 65 "Reserved" 66 "Reserved" 67 "Reserved" 68 "Reserved" 69 "Reserved" 70 "Reserved" 71 "Reserved" 72 "Reserved" 73 "Reserved" 74 "Reserved" 75 "Reserved" 76 "Reserved" 77 "Reserved" 78 "Reserved" 79 "Reserved" 80 "Reserved" 81 "Reserved" 82 "Reserved" 83 "Reserved" 84 "Reserved" 85 "Reserved" 86 "Reserved" 87 "Reserved" 88 "Reserved" 89 "Reserved" 90 "Reserved" 91 "Reserved" 92 "Reserved" 93 "Reserved" 94 "Reserved" 95 "Reserved" 96 "Reserved" 97 "Reserved" 98 "Reserved" 99 "Reserved" 100 "Reserved" 101 "Reserved" 102 "Reserved" 103 "Reserved" 104 "Reserved" 105 "Reserved" 106 "Reserved" 107 "Reserved" 108 "Reserved" 109 "Reserved" 110 "Reserved" 111 "Reserved" 112 "Reserved" 113 "Reserved" 114 "Reserved" 115 "Reserved" 116 "Reserved" 117 "Reserved" 118 "Reserved" 119 "Reserved" 120 "Reserved" 121 "Reserved" 122 "Reserved" 123 "Reserved" 124 "Reserved" 125 "Reserved" 126 "Reserved" 127 "Reserved" 128 "Reserved" 129 "Reserved" 130 "Reserved" 131 "Reserved" 132 "Reserved" 133 "Reserved" 134 "Reserved" 135 "Reserved" 136 "Reserved" 137 "Reserved" 138 "Reserved" 139 "Reserved" 140 "Reserved" 141 "Reserved" 142 "Reserved" 143 "Reserved" 144 "Reserved" 145 "Reserved" 146 "Reserved" 147 "Reserved" 148 "Reserved" 149 "Reserved" 150 "Reserved" 151 "Reserved" 152 "Reserved" 153 "Reserved" 154 "Reserved" 155 "Reserved" 156 "Reserved" 157 "Reserved" 158 "Reserved" 159 "Reserved" 160 "Reserved" 161 "Reserved" 162 "Reserved" 163 "Reserved" 164 "Reserved" 165 "Reserved" 166 "Reserved" 167 "Reserved" 168 "Reserved" 169 "Reserved" 170 "Reserved" 171 "Reserved" 172 "Reserved" 173 "Reserved" 174 "Reserved" 175 "Reserved" 176 "Reserved" 177 "Reserved" 178 "Reserved" 179 "Reserved" 180 "Reserved" 181 "Reserved" 182 "Reserved" 183 "Reserved" 184 "Reserved" 185 "Reserved" 186 "Reserved" 187 "Reserved" 188 "Reserved" 189 "Reserved" 190 "Reserved" 191 "Reserved" 192 "Reserved" 193 "Reserved" 194 "Reserved" 195 "Reserved" 196 "Reserved" 197 "Reserved" 198 "Reserved" 199 "Reserved" 200 "Reserved" 201 "Reserved" 202 "Reserved" 203 "Reserved" 204 "Reserved" 205 "Reserved" 206 "Reserved" 207 "Reserved" 208 "Reserved" 209 "Reserved" 210 "Reserved" 211 "Reserved" 212 "Reserved" 213 "Reserved" 214 "Reserved" 215 "Reserved" 216 "Reserved" 217 "Reserved" 218 "Reserved" 219 "Reserved" 220 "Reserved" 221 "Reserved" 222 "Reserved" 223 "Reserved" 224 "Reserved" 225 "Reserved" 226 "Reserved" 227 "Reserved" 228 "Reserved" 229 "Reserved" 230 "Reserved" 231 "Reserved" 232 "Reserved" 233 "Reserved" 234 "Reserved" 235 "Reserved" 236 "Reserved" 237 "Reserved" 238 "Reserved" 239 "Reserved" 240 "Reserved" 241 "Reserved" 242 "Reserved" 243 "Reserved" 244 "Reserved" 245 "Reserved" 246 "Reserved" 247 "Reserved" 248 "Reserved" 249 "Reserved" 250 "Reserved" 251 "Reserved" 252 "Reserved" 253 "Reserved" 254 "Reserved" 255 "Reserved" ;
VAL_ 643 DCM_FR_CarSharingTimeSts 0 "1" 1 "2" 2 "3" 3 "4" 4 "5" 5 "6" 6 "7" 7 "8" 8 "9" 9 "10" ;
VAL_ 643 DCM_FR_PowerDoorModeSts 0 "Fully Auto" 1 "Half Auto" 2 "Assist Manual" 3 "Fully Manual" ;
VAL_ 643 DCM_FR_FrontKeepOpenSts 0 "Disable" 1 "Enable" ;
VAL_ 643 DCM_FR_PriorSoundSts 0 "Disable" 1 "Enable" ;
VAL_ 643 DCM_FR_CarSharingLightSts 0 "Disable" 1 "Enable" ;
VAL_ 643 DCM_FR_WelcomeOnOffSts 0 "Disable" 1 "Enable" ;
VAL_ 643 DCM_FR_DoorFRLockSts 0 "Locked" 1 "Unlocked" ;
VAL_ 643 DCM_FR_DoorFRAngle 127 "Invalid";
VAL_ 643 DCM_FR_FRPESwitchReq 0 "Not pressed" 1 "Pressed" ;
VAL_ 643 DCM_FR_DoorAntiPinchSts 0 "Normal" 1 "Anti pinch" ;
VAL_ 643 DCM_FR_DoorObstacleSts 0 "Normal" 1 "Outer obstacle" ;
VAL_ 643 DCM_FR_ElectricDoorMovementSts 0 "FullyClosed" 1 "FullyOpened" 2 "Opening" 3 "Closing" 4 "Stoped" 5 "Revserved" 6 "Revserved" 7 "Revserved" ;
VAL_ 643 DCM_FR_LinkageAvoidanceReq 0 "NO Request" 1 "Close" 2 "Open" 3 "Stop" ;
VAL_ 643 DCM_FR_InsideSwitchReq 0 "Not pressed" 1 "Pressed" ;
VAL_ 643 DCM_FR_WindowSts 0 "Stopped" 1 "Auto Up moving" 2 "Manual Up moving" 3 "Auto Down moving" 4 "Manual Down moving" 5 "Pinch Reversing" ;
VAL_ 643 DCM_FR_PWM_POS_STS 0 "Bottom stall" 1 "No stall" 2 "Top stall" 3 "Top soft stop" 4 "Bottom soft stop" ;
VAL_ 643 DCM_FR_GLASS_LOCATION 0 "0%" 1 "5%" 2 "10%" 3 "15%" 4 "20%" 5 "25%" 6 "30%" 7 "35%" 8 "40%" 9 "45%" 10 "50%" 11 "55%" 12 "60%" 13 "65%" 14 "70%" 15 "75%" 16 "80%" 17 "85%" 18 "90%" 19 "95%" 20 "100%" ;
VAL_ 643 DCM_FR_FrontDoorAngleFeedback 0 "Fully Open" 1 "Half Open" ;
VAL_ 643 DCM_FR_FRWindowLockSts 0 "LOCK" 1 "UNLOCK" ;
VAL_ 643 DCM_FR_DoorFRSts 0 "Closed" 1 "Opened" ;
VAL_ 651 MessageCounter_28B 15 "Invalid" ;
VAL_ 651 DCM_FR_PowerDoorErrorSts 0 "Normal" 1 "Tilt sensor error" 2 "Internal button error" 3 "Hidden Handle error" 4 "Door position uncertain" 5 "Actuator load protection" 6 "Obstacle sensor error" 7 "Excessive slope" ;
VAL_ 651 DCM_FR_AmbientTemperatureValid 0 "Invalid" 1 "Valid" ;
VAL_ 651 DCM_FR_RightMirrorHorizontalPos 255 "Invalid";
VAL_ 651 DCM_FR_RightMirrorVerticalPos 255 "Invalid";
VAL_ 651 DCM_FR_MirrorAutoTurnDownSts 0 "Disable" 1 "Enable" ;
VAL_ 651 DCM_FR_MirrorAutoFoldUnfoldSts 0 "Disable" 1 "Enable" ;
VAL_ 651 DCM_FR_RearmirrorHeatingSts 0 "OFF" 1 "ON" ;
VAL_ 651 DCM_FR_MirrorFold_UnfoldSts 0 "Unfold" 1 "Fold" ;
VAL_ 653 DCM_FR_MirrorTiltVerticalPos 255 "Invalid";
VAL_ 653 DCM_FR_MirrorTiltHorizontalPos 255 "Invalid";
VAL_ 653 DCM_FR_MirrorMainVerticalPos 255 "Invalid";
VAL_ 653 DCM_FR_MirrorMainHorizontalPos 255 "Invalid";
VAL_ 310 DCM_FR_MirrorAdjustmentSts 0 "No Request" 1 "Fault_Folded" ;
VAL_ 310 DCM_FR_MirrorFoldFaultSts 0 "No Request" 1 "Fail to fold" 2 "Fail to unfold" 3 "Fail on speed" ;
VAL_ 310 DCM_FR_HandleFailReminder 0 "Disable" 1 "Enable" 2 "Reserved" 3 "Reserved" ;
VAL_ 310 DCM_FR_PriorSoundReq 0 "No request" 1 "Enable" ;
VAL_ 644 MessageCounter_284 15 "Invalid" ;
VAL_ 644 DCM_RL_DoorRLLockSts 0 "Locked" 1 "Unlocked" ;
VAL_ 644 DCM_RL_DoorRLAngle 127 "Invalid";
VAL_ 644 DCM_RL_RLPESwitchReq 0 "Not pressed" 1 "Pressed" ;
VAL_ 644 DCM_RL_DoorObstacleSts 0 "Normal" 1 "Outer obstacle" ;
VAL_ 644 DCM_RL_DoorAntiPinchSts 0 "Normal" 1 "Anti pinch" ;
VAL_ 644 DCM_RL_ElectricDoorMovementSts 0 "FullyClosed" 1 "FullyOpened" 2 "Opening" 3 "Closing" 4 "Stoped" 5 "Revserved" 6 "Revserved" 7 "Revserved" ;
VAL_ 644 DCM_RL_LinkageAvoidanceReq 0 "NO Request" 1 "Close" 2 "Open" 3 "Stop" ;
VAL_ 644 DCM_RL_InsideSwitchReq 0 "Not pressed" 1 "Pressed" ;
VAL_ 644 DCM_RL_WindowSts 0 "stopped" 1 "Auto Up moving" 2 "Manual Up moving" 3 "Auto Down moving" 4 "Manual Down moving" 5 "Pinch Reversing" ;
VAL_ 644 DCM_RL_PWM_POS_STS 0 "Bottom stall" 1 "No stall" 2 "Top stall" 3 "Top soft stop" 4 "Bottom soft stop" ;
VAL_ 644 DCM_RL_GLASS_LOCATION 0 "0%" 1 "5%" 2 "10%" 3 "15%" 4 "20%" 5 "25%" 6 "30%" 7 "35%" 8 "40%" 9 "45%" 10 "50%" 11 "55%" 12 "60%" 13 "65%" 14 "70%" 15 "75%" 16 "80%" 17 "85%" 18 "90%" 19 "95%" 20 "100%" ;
VAL_ 644 DCM_RL_RearDoorAngleFeedback 0 "Fully Open" 1 "Half Open" ;
VAL_ 644 DCM_RL_RLWindowLockSts 0 "LOCK" 1 "UNLOCK" ;
VAL_ 644 DCM_RL_DoorRLSts 0 "Closed" 1 "Opened" ;
VAL_ 644 DCM_RL_PowerDoorErrorSts 0 "Normal" 1 "Tilt sensor error" 2 "Internal button error" 3 "Hidden Handle error" 4 "Door position uncertain" 5 "Actuator load protection" 6 "Obstacle sensor error" 7 "Excessive slope" ;
VAL_ 644 DCM_RL_PriorSoundSts 0 "Disable" 1 "Enable" ;
VAL_ 644 DCM_RL_PowerDoorModeSts 0 "Fully Auto" 1 "Half Auto" 2 "Assist Manual" 3 "Fully Manual" ;
VAL_ 644 DCM_RL_WelcomeOnOffSts 0 "Disable" 1 "Enable" ;
VAL_ 644 DCM_RL_CarSharingLightSts 0 "Disable" 1 "Enable" ;
VAL_ 644 DCM_RL_CarSharingColorSts 0 "Colour1" 1 "Colour2" 2 "Colour3" 3 "Colour4" 4 "Colour5" 5 "Colour6" 6 "Colour7" 7 "Colour8" 8 "Colour9" 9 "Colour10" 10 "Colour11" 11 "Colour12" 12 "Colour13" 13 "Colour14" 14 "Colour15" 15 "Colour16" 16 "Colour17" 17 "Colour18" 18 "Colour19" 19 "Colour20" 20 "Colour21" 21 "Colour22" 22 "Colour23" 23 "Colour24" 24 "Colour25" 25 "Colour26" 26 "Colour27" 27 "Colour28" 28 "Colour29" 29 "Colour30" 30 "Colour31" 31 "Colour32" 32 "Colour33" 33 "Colour34" 34 "Colour35" 35 "Colour36" 36 "Colour37" 37 "Colour38" 38 "Colour39" 39 "Colour40" 40 "Colour41" 41 "Colour42" 42 "Colour43" 43 "Colour44" 44 "Colour45" 45 "Colour46" 46 "Colour47" 47 "Colour48" 48 "Colour49" 49 "Colour50" 50 "Colour51" 51 "Colour52" 52 "Colour53" 53 "Colour54" 54 "Colour55" 55 "Colour56" 56 "Colour57" 57 "Colour58" 58 "Colour59" 59 "Colour60" 60 "Colour61" 61 "Colour62" 62 "Colour63" 63 "Colour64" 64 "Reserved" 65 "Reserved" 66 "Reserved" 67 "Reserved" 68 "Reserved" 69 "Reserved" 70 "Reserved" 71 "Reserved" 72 "Reserved" 73 "Reserved" 74 "Reserved" 75 "Reserved" 76 "Reserved" 77 "Reserved" 78 "Reserved" 79 "Reserved" 80 "Reserved" 81 "Reserved" 82 "Reserved" 83 "Reserved" 84 "Reserved" 85 "Reserved" 86 "Reserved" 87 "Reserved" 88 "Reserved" 89 "Reserved" 90 "Reserved" 91 "Reserved" 92 "Reserved" 93 "Reserved" 94 "Reserved" 95 "Reserved" 96 "Reserved" 97 "Reserved" 98 "Reserved" 99 "Reserved" 100 "Reserved" 101 "Reserved" 102 "Reserved" 103 "Reserved" 104 "Reserved" 105 "Reserved" 106 "Reserved" 107 "Reserved" 108 "Reserved" 109 "Reserved" 110 "Reserved" 111 "Reserved" 112 "Reserved" 113 "Reserved" 114 "Reserved" 115 "Reserved" 116 "Reserved" 117 "Reserved" 118 "Reserved" 119 "Reserved" 120 "Reserved" 121 "Reserved" 122 "Reserved" 123 "Reserved" 124 "Reserved" 125 "Reserved" 126 "Reserved" 127 "Reserved" 128 "Reserved" 129 "Reserved" 130 "Reserved" 131 "Reserved" 132 "Reserved" 133 "Reserved" 134 "Reserved" 135 "Reserved" 136 "Reserved" 137 "Reserved" 138 "Reserved" 139 "Reserved" 140 "Reserved" 141 "Reserved" 142 "Reserved" 143 "Reserved" 144 "Reserved" 145 "Reserved" 146 "Reserved" 147 "Reserved" 148 "Reserved" 149 "Reserved" 150 "Reserved" 151 "Reserved" 152 "Reserved" 153 "Reserved" 154 "Reserved" 155 "Reserved" 156 "Reserved" 157 "Reserved" 158 "Reserved" 159 "Reserved" 160 "Reserved" 161 "Reserved" 162 "Reserved" 163 "Reserved" 164 "Reserved" 165 "Reserved" 166 "Reserved" 167 "Reserved" 168 "Reserved" 169 "Reserved" 170 "Reserved" 171 "Reserved" 172 "Reserved" 173 "Reserved" 174 "Reserved" 175 "Reserved" 176 "Reserved" 177 "Reserved" 178 "Reserved" 179 "Reserved" 180 "Reserved" 181 "Reserved" 182 "Reserved" 183 "Reserved" 184 "Reserved" 185 "Reserved" 186 "Reserved" 187 "Reserved" 188 "Reserved" 189 "Reserved" 190 "Reserved" 191 "Reserved" 192 "Reserved" 193 "Reserved" 194 "Reserved" 195 "Reserved" 196 "Reserved" 197 "Reserved" 198 "Reserved" 199 "Reserved" 200 "Reserved" 201 "Reserved" 202 "Reserved" 203 "Reserved" 204 "Reserved" 205 "Reserved" 206 "Reserved" 207 "Reserved" 208 "Reserved" 209 "Reserved" 210 "Reserved" 211 "Reserved" 212 "Reserved" 213 "Reserved" 214 "Reserved" 215 "Reserved" 216 "Reserved" 217 "Reserved" 218 "Reserved" 219 "Reserved" 220 "Reserved" 221 "Reserved" 222 "Reserved" 223 "Reserved" 224 "Reserved" 225 "Reserved" 226 "Reserved" 227 "Reserved" 228 "Reserved" 229 "Reserved" 230 "Reserved" 231 "Reserved" 232 "Reserved" 233 "Reserved" 234 "Reserved" 235 "Reserved" 236 "Reserved" 237 "Reserved" 238 "Reserved" 239 "Reserved" 240 "Reserved" 241 "Reserved" 242 "Reserved" 243 "Reserved" 244 "Reserved" 245 "Reserved" 246 "Reserved" 247 "Reserved" 248 "Reserved" 249 "Reserved" 250 "Reserved" 251 "Reserved" 252 "Reserved" 253 "Reserved" 254 "Reserved" 255 "Reserved" ;
VAL_ 644 DCM_RL_CarSharingTimeSts 0 "1" 1 "2" 2 "3" 3 "4" 4 "5" 5 "6" 6 "7" 7 "8" 8 "9" 9 "10" ;
VAL_ 311 DCM_RL_PriorSoundReq 0 "No request" 1 "Enable" ;
VAL_ 645 MessageCounter_285 15 "Invalid" ;
VAL_ 645 DCM_RR_DoorRRLockSts 0 "Locked" 1 "Unlocked" ;
VAL_ 645 DCM_RR_DoorRRAngle 127 "Invalid";
VAL_ 645 DCM_RR_RRPESwitchReq 0 "Not pressed" 1 "Pressed" ;
VAL_ 645 DCM_RR_DoorObstacleSts 0 "Normal" 1 "Outer obstacle" ;
VAL_ 645 DCM_RR_DoorAntiPinchSts 0 "Normal" 1 "Anti pinch" ;
VAL_ 645 DCM_RR_ElectricDoorMovementSts 0 "FullyClosed" 1 "FullyOpened" 2 "Opening" 3 "Closing" 4 "Stoped" 5 "Revserved" 6 "Revserved" 7 "Revserved" ;
VAL_ 645 DCM_RR_LinkageAvoidanceReq 0 "NO Request" 1 "Close" 2 "Open" 3 "Stop" ;
VAL_ 645 DCM_RR_InsideSwitchReq 0 "Not pressed" 1 "Pressed" ;
VAL_ 645 DCM_RR_WindowSts 0 "stopped" 1 "Auto Up moving" 2 "Manual Up moving" 3 "Auto Down moving" 4 "Manual Down moving" 5 "Pinch Reversing" ;
VAL_ 645 DCM_RR_PWM_POS_STS 0 "Bottom stall" 1 "No stall" 2 "Top stall" 3 "Top soft stop" 4 "Bottom soft stop" ;
VAL_ 645 DCM_RR_GLASS_LOCATION 0 "0%" 1 "5%" 2 "10%" 3 "15%" 4 "20%" 5 "25%" 6 "30%" 7 "35%" 8 "40%" 9 "45%" 10 "50%" 11 "55%" 12 "60%" 13 "65%" 14 "70%" 15 "75%" 16 "80%" 17 "85%" 18 "90%" 19 "95%" 20 "100%" ;
VAL_ 645 DCM_RR_RearDoorAngleFeedback 0 "Fully Open" 1 "Half Open" ;
VAL_ 645 DCM_RR_RRWindowLockSts 0 "LOCK" 1 "UNLOCK" ;
VAL_ 645 DCM_RR_DoorRRSts 0 "Closed" 1 "Opened" ;
VAL_ 645 DCM_RR_PowerDoorErrorSts 0 "Normal" 1 "Tilt sensor error" 2 "Internal button error" 3 "Hidden Handle error" 4 "Door position uncertain" 5 "Actuator load protection" 6 "Obstacle sensor error" 7 "Excessive slope" ;
VAL_ 645 DCM_RR_PriorSoundSts 0 "Disable" 1 "Enable" ;
VAL_ 645 DCM_RR_PowerDoorModeSts 0 "Fully Auto" 1 "Half Auto" 2 "Assist Manual" 3 "Fully Manual" ;
VAL_ 645 DCM_RR_WelcomeOnOffSts 0 "Disable" 1 "Enable" ;
VAL_ 645 DCM_RR_CarSharingLightSts 0 "Disable" 1 "Enable" ;
VAL_ 645 DCM_RR_CarSharingColorSts 0 "Colour1" 1 "Colour2" 2 "Colour3" 3 "Colour4" 4 "Colour5" 5 "Colour6" 6 "Colour7" 7 "Colour8" 8 "Colour9" 9 "Colour10" 10 "Colour11" 11 "Colour12" 12 "Colour13" 13 "Colour14" 14 "Colour15" 15 "Colour16" 16 "Colour17" 17 "Colour18" 18 "Colour19" 19 "Colour20" 20 "Colour21" 21 "Colour22" 22 "Colour23" 23 "Colour24" 24 "Colour25" 25 "Colour26" 26 "Colour27" 27 "Colour28" 28 "Colour29" 29 "Colour30" 30 "Colour31" 31 "Colour32" 32 "Colour33" 33 "Colour34" 34 "Colour35" 35 "Colour36" 36 "Colour37" 37 "Colour38" 38 "Colour39" 39 "Colour40" 40 "Colour41" 41 "Colour42" 42 "Colour43" 43 "Colour44" 44 "Colour45" 45 "Colour46" 46 "Colour47" 47 "Colour48" 48 "Colour49" 49 "Colour50" 50 "Colour51" 51 "Colour52" 52 "Colour53" 53 "Colour54" 54 "Colour55" 55 "Colour56" 56 "Colour57" 57 "Colour58" 58 "Colour59" 59 "Colour60" 60 "Colour61" 61 "Colour62" 62 "Colour63" 63 "Colour64" 64 "Reserved" 65 "Reserved" 66 "Reserved" 67 "Reserved" 68 "Reserved" 69 "Reserved" 70 "Reserved" 71 "Reserved" 72 "Reserved" 73 "Reserved" 74 "Reserved" 75 "Reserved" 76 "Reserved" 77 "Reserved" 78 "Reserved" 79 "Reserved" 80 "Reserved" 81 "Reserved" 82 "Reserved" 83 "Reserved" 84 "Reserved" 85 "Reserved" 86 "Reserved" 87 "Reserved" 88 "Reserved" 89 "Reserved" 90 "Reserved" 91 "Reserved" 92 "Reserved" 93 "Reserved" 94 "Reserved" 95 "Reserved" 96 "Reserved" 97 "Reserved" 98 "Reserved" 99 "Reserved" 100 "Reserved" 101 "Reserved" 102 "Reserved" 103 "Reserved" 104 "Reserved" 105 "Reserved" 106 "Reserved" 107 "Reserved" 108 "Reserved" 109 "Reserved" 110 "Reserved" 111 "Reserved" 112 "Reserved" 113 "Reserved" 114 "Reserved" 115 "Reserved" 116 "Reserved" 117 "Reserved" 118 "Reserved" 119 "Reserved" 120 "Reserved" 121 "Reserved" 122 "Reserved" 123 "Reserved" 124 "Reserved" 125 "Reserved" 126 "Reserved" 127 "Reserved" 128 "Reserved" 129 "Reserved" 130 "Reserved" 131 "Reserved" 132 "Reserved" 133 "Reserved" 134 "Reserved" 135 "Reserved" 136 "Reserved" 137 "Reserved" 138 "Reserved" 139 "Reserved" 140 "Reserved" 141 "Reserved" 142 "Reserved" 143 "Reserved" 144 "Reserved" 145 "Reserved" 146 "Reserved" 147 "Reserved" 148 "Reserved" 149 "Reserved" 150 "Reserved" 151 "Reserved" 152 "Reserved" 153 "Reserved" 154 "Reserved" 155 "Reserved" 156 "Reserved" 157 "Reserved" 158 "Reserved" 159 "Reserved" 160 "Reserved" 161 "Reserved" 162 "Reserved" 163 "Reserved" 164 "Reserved" 165 "Reserved" 166 "Reserved" 167 "Reserved" 168 "Reserved" 169 "Reserved" 170 "Reserved" 171 "Reserved" 172 "Reserved" 173 "Reserved" 174 "Reserved" 175 "Reserved" 176 "Reserved" 177 "Reserved" 178 "Reserved" 179 "Reserved" 180 "Reserved" 181 "Reserved" 182 "Reserved" 183 "Reserved" 184 "Reserved" 185 "Reserved" 186 "Reserved" 187 "Reserved" 188 "Reserved" 189 "Reserved" 190 "Reserved" 191 "Reserved" 192 "Reserved" 193 "Reserved" 194 "Reserved" 195 "Reserved" 196 "Reserved" 197 "Reserved" 198 "Reserved" 199 "Reserved" 200 "Reserved" 201 "Reserved" 202 "Reserved" 203 "Reserved" 204 "Reserved" 205 "Reserved" 206 "Reserved" 207 "Reserved" 208 "Reserved" 209 "Reserved" 210 "Reserved" 211 "Reserved" 212 "Reserved" 213 "Reserved" 214 "Reserved" 215 "Reserved" 216 "Reserved" 217 "Reserved" 218 "Reserved" 219 "Reserved" 220 "Reserved" 221 "Reserved" 222 "Reserved" 223 "Reserved" 224 "Reserved" 225 "Reserved" 226 "Reserved" 227 "Reserved" 228 "Reserved" 229 "Reserved" 230 "Reserved" 231 "Reserved" 232 "Reserved" 233 "Reserved" 234 "Reserved" 235 "Reserved" 236 "Reserved" 237 "Reserved" 238 "Reserved" 239 "Reserved" 240 "Reserved" 241 "Reserved" 242 "Reserved" 243 "Reserved" 244 "Reserved" 245 "Reserved" 246 "Reserved" 247 "Reserved" 248 "Reserved" 249 "Reserved" 250 "Reserved" 251 "Reserved" 252 "Reserved" 253 "Reserved" 254 "Reserved" 255 "Reserved" ;
VAL_ 645 DCM_RR_CarSharingTimeSts 0 "1" 1 "2" 2 "3" 3 "4" 4 "5" 5 "6" 6 "7" 7 "8" 8 "9" 9 "10" ;
VAL_ 312 DCM_RR_PriorSoundReq 0 "No request" 1 "Enable" ;
VAL_ 880 DCM_SDS_FL_SensorWorksts 0 "Reset （Default）" 1 "Init" 2 "Active" 3 "Pre-Sleep" 4 "ThermalProtected" 5 "Invalid( PORD Error)" ;
VAL_ 881 DCM_SDS_FR_SensorWorksts 0 "Reset （Default）" 1 "Init" 2 "Active" 3 "Pre-Sleep" 4 "ThermalProtected" 5 "Invalid( PORD Error)" ;
VAL_ 882 DCM_SDS_RL_SensorWorksts 0 "Reset （Default）" 1 "Init" 2 "Active" 3 "Pre-Sleep" 4 "ThermalProtected" 5 "Invalid( PORD Error)" ;
VAL_ 883 DCM_SDS_RR_SensorWorksts 0 "Reset （Default）" 1 "Init" 2 "Active" 3 "Pre-Sleep" 4 "ThermalProtected" 5 "Invalid( PORD Error)" ;
VAL_ 714 DIM_ScreenBrightnessSta 0 "0Level" 1 "1Level" 2 "2Level" 3 "3Level" 4 "4Level" 5 "5Level" 6 "6Level" 7 "7Level" 8 "8Level" 9 "9Level" 10 "10Level" 11 "Reserved" 12 "Reserved" 13 "Reserved" 14 "Reserved" 15 "Reserved" 16 "Reserved" 17 "Reserved" 18 "Reserved" 19 "Reserved" 20 "Reserved" 21 "Reserved" 22 "Reserved" 23 "Reserved" 24 "Reserved" 25 "Reserved" 26 "Reserved" 27 "Reserved" 28 "Reserved" 29 "Reserved" 30 "Reserved" 31 "Invalid" ;
VAL_ 714 DIM_AutoScreenBacklightSta 0 "Reserved" 1 "OFF" 2 "ON" 3 "Reserved" ;
VAL_ 714 DIM_FaultState 0 "No fault" 1 "Fault" 2 "Reserved" 3 "Reserved" ;
VAL_ 714 DIM_ONOFFSts 0 "Invalid" 1 "Off" 2 "On" 3 "Reserved" ;
VAL_ 512 ERA_ECallSts 0 "No display" 1 "Calling the operator" 2 "Call in progress" 3 "Call ended" ;
VAL_ 512 ERA_TestModeSts 0 "No request" 1 "Test normal mode" 2 "Test abnormal mode" 3 "Reserved" ;
VAL_ 512 ERA_SelfTestSts 0 "Normal" 1 "Abnormal" ;
VAL_ 241 MessageCounter_0F1 15 "Invalid" ;
VAL_ 241 EPS_APS_CtrlSts 0 "Inhibit" 1 "Available" 2 "Active" 3 "Abort" 4 "Reply for control(Reserved)" 5 "Reserved" 6 "Reserved" 7 "Failure" ;
VAL_ 241 EPS_APS_CtrlFaultSts 0 "NormalOperation" 1 "OverSpeed" 2 "DriverInterference" 3 "AbnormalCANInput" 4 "ExcessAngleDeviation" 5 "APSLowPriority" 6 "Reserved" 7 "Failure" ;
VAL_ 241 EPS_LCA_CtrlRequestSts 0 "Available" 1 "Request output stop" 2 "LCA uncontrollable" 3 "Override state" 4 "EPS(LCA) failure determination" 5 "Reserved" 6 "Reserved" 7 "EPS(CONV) failure determination" ;
VAL_ 241 EPS_LCA_Active 0 "Not Active" 1 "Active" ;
VAL_ 240 MessageCounter_0F0 15 "Invalid" ;
VAL_ 240 EPS_SteeringWheelAngleSpd 65535 "Invalid" ;
VAL_ 240 EPS_SteeringWheelAngleValid 0 "Invalid" 1 "Valid" ;
VAL_ 240 EPS_SteeringWheelAngleSpdValid 0 "Invalid" 1 "Valid" ;
VAL_ 240 EPS_TorsionBarTorqueValid 0 "Invalid" 1 "Valid" ;
VAL_ 240 EPS_ModeChangeEnable 0 "Disable" 1 "Enable" ;
VAL_ 240 EPS_ModeFb 0 "Normal" 1 "Reserved" 2 "Sport" 3 "Comfort" ;
VAL_ 240 EPS_WarningLamp 0 "No Failure" 1 "Light level failure indication (yellow)" 2 "Heavy level failure indication (red)" 3 "Invalid" ;
VAL_ 240 EPS_SteeringWheelAngle 65535 "Invalid" ;
VAL_ 240 EPS_TorsionBarTorque 255 "Invalid" ;
VAL_ 614 EVCOM_OverPwrDropFreqError 0 "No Error" 1 "Error" ;
VAL_ 614 EVCOM_OverCurDropFreqError 0 "No Error" 1 "Error" ;
VAL_ 614 EVCOM_CommunicationError 0 "No Error" 1 "Error" ;
VAL_ 614 EVCOM_StandByUnderVolError 0 "No Error" 1 "Error" ;
VAL_ 614 EVCOM_StandByOverVolError 0 "No Error" 1 "Error" ;
VAL_ 614 EVCOM_UnderVoltageError 0 "No Error" 1 "Error" ;
VAL_ 614 EVCOM_OverVoltageError 0 "No Error" 1 "Error" ;
VAL_ 614 EVCOM_OverCurrentError 0 "No Error" 1 "Error" ;
VAL_ 614 EVCOM_ActlOprtMode 0 "off" 1 "running" 2 "limit" 3 "pre_heat" 4 "fault" 5 "reserved" 6 "reserved" 7 "reserved" ;
VAL_ 615 EVCOM_OverLoad 0 "No Error" 1 "Error" ;
VAL_ 615 EVCOM_InpowerError 0 "No Error" 1 "Error" ;
VAL_ 615 EVCOM_LackPhase 0 "No Error" 1 "Error" ;
VAL_ 615 EVCOM_TemperSensorError 0 "No Error" 1 "Error" ;
VAL_ 615 EVCOM_CurrentOffsetError 0 "No Error" 1 "Error" ;
VAL_ 615 EVCOM_OverHeat 0 "No Error" 1 "IGBT overheat" 2 "MCU overheat" 3 "reserved" ;
VAL_ 615 EVCOM_CompBusVolt 511 "Invalid";
VAL_ 615 EVCOM_StallFault 0 "No Fault" 1 "Fault" ;
VAL_ 640 MessageCounter_280 15 "Invalid" ;
VAL_ 640 HLL_HeadlampFault 0 "No Error" 1 "Error" ;
VAL_ 640 HLL_DRLFaultSts 0 "No Error" 1 "Error" ;
VAL_ 641 MessageCounter_281 15 "Invalid" ;
VAL_ 641 HLR_HeadlampFault 0 "No Error" 1 "Error" ;
VAL_ 641 HLR_DRLFaultSts 0 "No Error" 1 "Error" ;
VAL_ 660 HOD_Heating_SteerWhHeatSts 0 "OFF" 1 "ON" ;
VAL_ 658 HUD_SelfCheckSts 0 "Normal" 1 "Fault" ;
VAL_ 658 HUD_BrightnessSet 0 "0Level" 1 "1Level" 2 "2Level" 3 "3Level" 4 "4Level" 5 "5Level" 6 "6Level" 7 "7Level" 8 "8Level" 9 "9Level" 10 "10Level" 11 "Reserved" 12 "Reserved" 13 "Reserved" 14 "Reserved" 15 "Reserved" 16 "Reserved" 17 "Reserved" 18 "Reserved" 19 "Reserved" 20 "Reserved" 21 "Reserved" 22 "Reserved" 23 "Reserved" 24 "Reserved" 25 "Reserved" 26 "Reserved" 27 "Reserved" 28 "Reserved" 29 "Reserved" 30 "Reserved" 31 "Invalid" ;
VAL_ 658 HUD_OnOffSts 0 "NO Request" 1 "OFF" 2 "ON" 3 "INVALID" ;
VAL_ 658 HUD_HeightSts 0 "-8 level" 1 "-7 level" 2 "-6 level" 3 "-5 level" 4 "-4 level" 5 "-3 level" 6 "-2 level" 7 "-1 level" 8 "0 level" 9 "1 level" 10 "2 level" 11 "3 level" 12 "4 level" 13 "5 level" 14 "6 level" 15 "7 level" 16 "8 level" 17 "reserved" 18 "reserved" 19 "reserved" 20 "reserved" 21 "reserved" 22 "reserved" 23 "reserved" 24 "reserved" 25 "reserved" 26 "reserved" 27 "reserved" 28 "reserved" 29 "reserved" 30 "reserved" 31 "reserved" 32 "reserved" 33 "reserved" 34 "reserved" 35 "reserved" 36 "reserved" 37 "reserved" 38 "reserved" 39 "reserved" 40 "reserved" 41 "reserved" 42 "reserved" 43 "reserved" 44 "reserved" 45 "reserved" 46 "reserved" 47 "reserved" 48 "reserved" 49 "reserved" 50 "reserved" 51 "reserved" 52 "reserved" 53 "reserved" 54 "reserved" 55 "reserved" 56 "reserved" 57 "reserved" 58 "reserved" 59 "reserved" 60 "reserved" 61 "reserved" 62 "reserved" 63 "reserved" 64 "reserved" 65 "reserved" 66 "reserved" 67 "reserved" 68 "reserved" 69 "reserved" 70 "reserved" 71 "reserved" 72 "reserved" 73 "reserved" 74 "reserved" 75 "reserved" 76 "reserved" 77 "reserved" 78 "reserved" 79 "reserved" 80 "reserved" 81 "reserved" 82 "reserved" 83 "reserved" 84 "reserved" 85 "reserved" 86 "reserved" 87 "reserved" 88 "reserved" 89 "reserved" 90 "reserved" 91 "reserved" 92 "reserved" 93 "reserved" 94 "reserved" 95 "reserved" 96 "reserved" 97 "reserved" 98 "reserved" 99 "reserved" 100 "reserved" 101 "reserved" 102 "reserved" 103 "reserved" 104 "reserved" 105 "reserved" 106 "reserved" 107 "reserved" 108 "reserved" 109 "reserved" 110 "reserved" 111 "reserved" 112 "reserved" 113 "reserved" 114 "reserved" 115 "reserved" 116 "reserved" 117 "reserved" 118 "reserved" 119 "reserved" 120 "reserved" 121 "reserved" 122 "reserved" 123 "reserved" 124 "reserved" 125 "reserved" 126 "reserved" 127 "reserved" 128 "reserved" 129 "reserved" 130 "reserved" 131 "reserved" 132 "reserved" 133 "reserved" 134 "reserved" 135 "reserved" 136 "reserved" 137 "reserved" 138 "reserved" 139 "reserved" 140 "reserved" 141 "reserved" 142 "reserved" 143 "reserved" 144 "reserved" 145 "reserved" 146 "reserved" 147 "reserved" 148 "reserved" 149 "reserved" 150 "reserved" 151 "reserved" 152 "reserved" 153 "reserved" 154 "reserved" 155 "reserved" 156 "reserved" 157 "reserved" 158 "reserved" 159 "reserved" 160 "reserved" 161 "reserved" 162 "reserved" 163 "reserved" 164 "reserved" 165 "reserved" 166 "reserved" 167 "reserved" 168 "reserved" 169 "reserved" 170 "reserved" 171 "reserved" 172 "reserved" 173 "reserved" 174 "reserved" 175 "reserved" 176 "reserved" 177 "reserved" 178 "reserved" 179 "reserved" 180 "reserved" 181 "reserved" 182 "reserved" 183 "reserved" 184 "reserved" 185 "reserved" 186 "reserved" 187 "reserved" 188 "reserved" 189 "reserved" 190 "reserved" 191 "reserved" 192 "reserved" 193 "reserved" 194 "reserved" 195 "reserved" 196 "reserved" 197 "reserved" 198 "reserved" 199 "reserved" 200 "reserved" 201 "reserved" 202 "reserved" 203 "reserved" 204 "reserved" 205 "reserved" 206 "reserved" 207 "reserved" 208 "reserved" 209 "reserved" 210 "reserved" 211 "reserved" 212 "reserved" 213 "reserved" 214 "reserved" 215 "reserved" 216 "reserved" 217 "reserved" 218 "reserved" 219 "reserved" 220 "reserved" 221 "reserved" 222 "reserved" 223 "reserved" 224 "reserved" 225 "reserved" 226 "reserved" 227 "reserved" 228 "reserved" 229 "reserved" 230 "reserved" 231 "reserved" 232 "reserved" 233 "reserved" 234 "reserved" 235 "reserved" 236 "reserved" 237 "reserved" 238 "reserved" 239 "reserved" 240 "reserved" 241 "reserved" 242 "reserved" 243 "reserved" 244 "reserved" 245 "reserved" 246 "reserved" 247 "reserved" 248 "reserved" 249 "reserved" 250 "reserved" 251 "reserved" 252 "reserved" 253 "reserved" 254 "reserved" 255 "reserved" ;
VAL_ 658 HUD_BrightnessSts 0 "default" 1 "1level" 2 "2level" 3 "3level" 4 "4level" 5 "5level" 6 "6level" 7 "7level" 8 "8level" 9 "9level" 10 "10level" 11 "11level" 12 "12level" 13 "13level" 14 "14level" 15 "15level" 16 "16level" 17 "17level" 18 "18level" 19 "19level" 20 "20level" 21 "21level" 22 "22level" 23 "23level" 24 "24level" 25 "25level" 26 "26level" 27 "27level" 28 "28level" 29 "29level" 30 "30level" 31 "31level" 32 "32level" 33 "33level" 34 "34level" 35 "35level" 36 "36level" 37 "37level" 38 "38level" 39 "39level" 40 "40level" 41 "41level" 42 "42level" 43 "43level" 44 "44level" 45 "45level" 46 "46level" 47 "47level" 48 "48level" 49 "49level" 50 "50level" ;
VAL_ 184 MessageCounter_0B8 15 "Invalid" ;
VAL_ 184 IBS_VehicleStandstill_Valid 0 "Invalid" 1 "Valid" ;
VAL_ 184 IBS_WLTorqueVLCReqValid 0 "NotIntialized" 1 "Normal" 2 "Faulty" ;
VAL_ 184 IBS_CddAvailable 0 "NOT_AVAILABLE" 1 "AVAILABLE" ;
VAL_ 184 IBS_CddError 0 "NOT_ERROR" 1 "ERROR" ;
VAL_ 184 IBS_CddActive 0 "INACTIVE" 1 "ACTIVE" ;
VAL_ 184 IBS_VehicleStandstill 0 "NOT_STANDSTILL" 1 "STANDSTILL" 2 "RESERVED" ;
VAL_ 184 IBS_VlcAvalible 0 "NOT_AVAILABLE" 1 "AVAILABLE" ;
VAL_ 184 IBS_VlcError 0 "NOT_ERROR" 1 "ERROR" ;
VAL_ 184 IBS_VlcActive 0 "INACTIVE" 1 "ACTIVE" ;
VAL_ 183 MessageCounter_0B7 15 "Invalid" ;
VAL_ 183 IBS_APS_Avl 0 "AxCapbl_Full" 1 "reversed" 2 "AxCapbl_VehBlocked" 3 "reversed" ;
VAL_ 183 IBS_BrakeTypEcho 0 "No Request" 1 "Comfort" 2 "Emergency" 3 "Invalid" ;
VAL_ 183 IBS_APSCrlReqEcho 0 "No Request" 1 "Drive" 2 "LSM" 3 "Invalid" ;
VAL_ 183 IBS_APSModeEcho 0 "No Request" 1 "APS" 2 "RC" 3 "Invalid" ;
VAL_ 183 IBS_APSComfortAvl 0 "NotAvailable" 1 "Brake failure" 2 "Excessive slope" 3 "Available" ;
VAL_ 183 IBS_APSEmergenyAvl 0 "NotAvailable" 1 "Brake failure" 2 "Excessive slope" 3 "Available" ;
VAL_ 178 MessageCounter_0B2 15 "Invalid" ;
VAL_ 178 IBS_BrakePedalStatus 0 "NOT_PRESSED_INIT_DEFAULT" 1 "PRESSED" 2 "RESERVED" 3 "ERROR" ;
VAL_ 178 IBS_BrakePedalStatusValid 0 "Invalid" 1 "Valid" ;
VAL_ 179 MessageCounter_0B3 15 "Invalid" ;
VAL_ 179 IBS_EPBFailureLamp 0 "LampOFF" 1 "LampON" ;
VAL_ 179 IBS_BrakeLightRequest 0 "brakelightOFF" 1 "brakelightON" 2 "notused" 3 "signalnotavailable" ;
VAL_ 179 IBS_EPBworkingSts 0 "UNKNOWN" 1 "APPLIED" 2 "RELEASED" 3 "APPLY IN PROGRESS" 4 "RELEASE IN PROGRESS" 5 "COMPLETELY RELEASED" 6 "DYNAMIC APPLY" 7 "RESERVED" ;
VAL_ 179 IBS_TCSActive 0 "NotActive" 1 "Active" ;
VAL_ 179 IBS_VDCActive 0 "NotActive" 1 "Active" ;
VAL_ 179 IBS_HDCAvailable 0 "NOT_AVAILABLE" 1 "AVAILABLE" ;
VAL_ 179 IBS_AEBActive 0 "notactive" 1 "active" ;
VAL_ 179 IBS_HHCActive 0 "notactive" 1 "active" ;
VAL_ 179 IBS_HHCAvailable 0 "NOT_AVAILABLE" 1 "AVAILABLE" ;
VAL_ 179 IBS_AVHAvailable 0 "NOT_AVAILABLE" 1 "AVAILABLE" ;
VAL_ 179 IBS_HazWarnReq 0 "OFF" 1 "ON" 2 "Signalnotavailable" ;
VAL_ 179 IBS_EPBFunctionLamp 0 "LampOFF" 1 "LampON" 2 "flash" 3 "Invalid" ;
VAL_ 179 IBS_AEBAvailable 0 "NOT_AVAILABLE" 1 "AVAILABLE" ;
VAL_ 180 MessageCounter_0B4 15 "Invalid" ;
VAL_ 180 IBS_EPBTextdisplay 0 "Off" 1 "Park Brake Applied" 2 "Park Brake Released" 3 "Parking brake malfunction.Visit service center to fix the issue" 4 "Reserve" ;
VAL_ 180 IBS_SystemStatus 0 "Normal" 1 "Degrade" 2 "Partial" 3 "Inhibit" 4 "Reserved" 5 "Reserved" 6 "Reserved" 7 "Reserved" ;
VAL_ 180 IBS_VehicleSpeedValid 0 "Invalid" 1 "Valid" ;
VAL_ 180 IBS_ABSFault 0 "Noerror" 1 "Error" ;
VAL_ 180 IBS_EBDActive 0 "Not Active" 1 "Active" ;
VAL_ 180 IBS_EBDFault 0 "Noerror" 1 "Error" ;
VAL_ 180 IBS_VDCFault 0 "Noerror" 1 "Error" ;
VAL_ 180 IBS_TCSFault 0 "Noerror" 1 "Error" ;
VAL_ 180 IBS_ABSActive 0 "Not Active" 1 "Active" ;
VAL_ 180 IBS_ABPActive 0 "INACTIVE" 1 "ACTIVE" ;
VAL_ 180 IBS_ABPAvailable 0 "NOT_AVAILABLE" 1 "AVAILABLE" ;
VAL_ 180 IBS_DTCFault 0 "Noerror" 1 "Error" ;
VAL_ 180 IBS_VCU_DecelerationRequest_Available 0 "Available" 1 "Not Available" 2 "Reserved" 3 "Reserved" ;
VAL_ 186 MessageCounter_0BA 15 "Invalid" ;
VAL_ 186 IBS_CDPActive 0 "Not Active" 1 "Active" ;
VAL_ 187 MessageCounter_0BB 15 "Invalid" ;
VAL_ 187 IBS_SUBEPBworkingSts 0 "UNKNOWN" 1 "APPLIED" 2 "RELEASED" 3 "APPLY IN PROGRESS" 4 "RELEASE IN PROGRESS" 5 "COMPLETELY RELEASED" 6 "DYNAMIC APPLY" 7 "RESERVED" ;
VAL_ 187 IBS_SUBEPBFailureStatus 0 "No error" 1 "error" 2 "Reserve" 3 "Reserve" ;
VAL_ 188 MessageCounter_0BC 15 "Invalid" ;
VAL_ 188 IBS_HBAActive 0 "Not Active" 1 "Active" ;
VAL_ 188 IBS_ESCOffSts 0 "ESC OFF" 1 "ESC ON" ;
VAL_ 188 IBS_RWUActive 0 "Not Active" 1 "Active" ;
VAL_ 188 IBS_RWUAvailable 0 "NOT_AVAILABLE" 1 "AVAILABLE" ;
VAL_ 188 IBS_MaintenaceMode 0 "Not Active" 1 "Active" ;
VAL_ 188 IBS_RollerbenchMode 0 "Not Active" 1 "Active" ;
VAL_ 188 IBS_FactoryMode 0 "Not Active" 1 "Active" ;
VAL_ 188 IBS_AVHSts 0 "OFF" 1 "STANDBY" 2 "ACTIVE" ;
VAL_ 188 IBS_ESClampdisplay 0 "ESC lamp ON" 1 "ESC lamp OFF" 2 "ESC lamp FLASH" ;
VAL_ 188 IBS_HDCSts 0 "OFF" 1 "STANDBY" 2 "ACTIVE" ;
VAL_ 188 IBS_BrakeFluidWarning 0 "BRAKEFLUID_NORMAL_INIT_DEFAULT" 1 "BRAKEFLUID_EMPTY" 2 "RESERVED" 3 "RESERVED" ;
VAL_ 188 IBS_EPBFailureStatus 0 "No error" 1 "error" 2 "Reserve" 3 "Reserve" ;
VAL_ 188 IBS_TireMonSysSts 0 "System OK" 1 "System not OK" ;
VAL_ 188 IBS_TPMS_ResetSts 0 "OFF" 1 "ON" ;
VAL_ 188 IBS_TireWarnReLe 0 "Normal" 1 "Abnormal" ;
VAL_ 188 IBS_TireWarnReRi 0 "Normal" 1 "Abnormal" ;
VAL_ 188 IBS_TireWarnFrntLe 0 "Normal" 1 "Abnormal" ;
VAL_ 188 IBS_TireWarnFrntRi 0 "Normal" 1 "Abnormal" ;
VAL_ 185 MessageCounter_0B9 15 "Invalid" ;
VAL_ 185 IBS_WLTorqueRBSReqValid 0 "NotIntialized" 1 "Normal" 2 "Faulty" ;
VAL_ 185 IBS_RBSStatus 0 "NotActive" 1 "Active" ;
VAL_ 185 IBS_VCU_DecelerationReqActive 0 "NotActive" 1 "Active" ;
VAL_ 185 IBS_TargetGearReq 0 "No Request" 1 "P" 2 "N" 3 "R" 4 "D" ;
VAL_ 185 IBS_WLTorqueAPSReqValid 0 "NotIntialized" 1 "Normal" 2 "Faulty" ;
VAL_ 144 MessageCounter_090 15 "Invalid" ;
VAL_ 144 IBS_WLTorqueIncrReqSts 0 "INACTIVE" 1 "ACTIVE" ;
VAL_ 144 IBS_WLTorqueRedReqSts 0 "INACTIVE" 1 "ACTIVE" ;
VAL_ 176 MessageCounter_0B0 15 "Invalid" ;
VAL_ 176 IBS_FRWheelSpeed_Fault 0 "No error" 1 "Error" ;
VAL_ 176 IBS_FRMovingDirection 0 "Standstill" 1 "Forward" 2 "Backward" ;
VAL_ 176 IBS_FLWheelSpeed_Fault 0 "No error" 1 "Error" ;
VAL_ 176 IBS_FLMovingDirection 0 "Standstill" 1 "Forward" 2 "Backward" ;
VAL_ 177 MessageCounter_0B1 15 "Invalid" ;
VAL_ 177 IBS_RRWheelSpeed_Fault 0 "No error" 1 "Error" ;
VAL_ 177 IBS_RRMovingDirection 0 "Standstill" 1 "Forward" 2 "Backward" ;
VAL_ 177 IBS_RLWheelSpeed_Fault 0 "No error" 1 "Error" ;
VAL_ 177 IBS_RLMovingDirection 0 "Standstill" 1 "Forward" 2 "Backward" ;
VAL_ 152 MessageCounter_098 15 "Invalid" ;
VAL_ 152 MCU_ActualSpeedValid 0 "Invalid" 1 "Valid" ;
VAL_ 152 MCU_ActTrqValid 0 "Invalid" 1 "Valid" ;
VAL_ 152 MCU_ActualTorque 2047 "Invalid";
VAL_ 152 MCU_UdcCurr 1022 "Abnormal" 1023 "Invalid" ;
VAL_ 152 MCU_IsCurr 2047 "Invalid";
VAL_ 152 MCU_ActualSpeed 65535 "Invalid";
VAL_ 243 MCU_VCUWorkMode 0 "Initialization;" 1 "Standby;" 2 "Ready;" 3 "Torque Control;" 4 "Fault" 5 "ActiveDischarge;" 6 "Afterrun;" 7 "Motor Active Hearting;" 8 "Speed Control" ;
VAL_ 594 MCU_TrqAbsMax 2047 "Invalid";
VAL_ 594 MCU_TrqAbsMin 2047 "Invalid";
VAL_ 594 MCU_StDischg 0 "Standby" 1 "Active" 2 "Finished" 3 "Failed" ;
VAL_ 594 MCU_UT30Curr 63 "Invalid";
VAL_ 594 MCU_UT15State 0 "No active" 1 "Active" ;
VAL_ 594 MCU_ActUnfilteredRotSpd 65535 "Invalid";
VAL_ 594 MCU_SpdMaxLimit 65535 "Invalid";
VAL_ 595 MessageCounter_253 15 "Invalid" ;
VAL_ 595 MCU_FaultLevel 0 "Normal" 1 "LV1 Minor fault" 2 "LV2 Limited power by a small margin" 3 "LV3 Greatly limited power" 4 "LV4 Stop the output(Fault enable recovery)" 5 "LV5 Stop the output(Fault disable recovery)" ;
VAL_ 914 MCU_IGBTTempU 254 "Abnormal" 255 "Invalid" ;
VAL_ 914 MCU_IGBTTempV 254 "Abnormal" 255 "Invalid" ;
VAL_ 914 MCU_IGBTTempW 254 "Abnormal" 255 "Invalid" ;
VAL_ 914 MCU_IGBTTempMax 254 "Abnormal" 255 "Invalid" ;
VAL_ 914 MCU_IGBTTempRiseU 254 "Abnormal" 255 "Invalid" ;
VAL_ 914 MCU_IGBTTempRiseV 254 "Abnormal" 255 "Invalid" ;
VAL_ 914 MCU_IGBTTempRiseW 254 "Abnormal" 255 "Invalid" ;
VAL_ 914 MCU_IGBTTempRiseMax 254 "Abnormal" 255 "Invalid" ;
VAL_ 915 MCU_TempCurrCool 254 "Abnormal" 255 "Invalid" ;
VAL_ 915 MCU_TempCurrStr1 254 "Abnormal" 255 "Invalid" ;
VAL_ 915 MCU_TempCurrStr2 254 "Abnormal" 255 "Invalid" ;
VAL_ 915 MCU_TempCurrStrMax 254 "Abnormal" 255 "Invalid" ;
VAL_ 915 MCU_TempRiseCurrStr 254 "Abnormal" 255 "Invalid" ;
VAL_ 915 MCU_TempStatus 0 "Normal Temperature" 1 "Heating alarm 1" 2 "Heating alarm 2" 3 "Over Heating" ;
VAL_ 673 MessageCounter_2A1 15 "Invalid" ;
VAL_ 673 MFP_FC_LeftTurnLampFault 0 "No Failure" 1 "Failure" ;
VAL_ 673 MFP_FC_RightTurnLampFault 0 "No Failure" 1 "Failure" ;
VAL_ 673 MFP_FC_WelLightshowSts 0 "Running" 1 "Finish" ;
VAL_ 673 MFP_FC_FollowMeHomeSts 0 "Running" 1 "Finish" ;
VAL_ 673 MFP_FC_WelLightshowAniSts 0 "Reserved" 1 "Animation 1" 2 "Animation 2" 3 "Animation 3" 4 "Animation 4" 5 "Animation 5" 6 "Animation 6" 7 "Animation 7" 8 "Animation 8" 9 "Animation 9" 10 "Animation 10" 11 "Animation 11" 12 "Animation 12" 13 "Animation 13" 14 "Animation 14" 15 "Animation 15" 16 "Animation 16" 17 "Animation 17" 18 "Animation 18" 19 "Animation 19" 20 "Animation 20" 21 "Animation 21" 22 "Animation 22" 23 "Animation 23" 24 "Animation 24" 25 "Animation 25" ;
VAL_ 673 MFP_FC_FMHLightshowAniSts 0 "Reserved" 1 "Animation 1" 2 "Animation 2" 3 "Animation 3" 4 "Animation 4" 5 "Animation 5" 6 "Animation 6" 7 "Animation 7" 8 "Animation 8" 9 "Animation 9" 10 "Animation 10" 11 "Animation 11" 12 "Animation 12" 13 "Animation 13" 14 "Animation 14" 15 "Animation 15" 16 "Animation 16" 17 "Animation 17" 18 "Animation 18" 19 "Animation 19" 20 "Animation 20" 21 "Animation 21" 22 "Animation 22" 23 "Animation 23" 24 "Animation 24" 25 "Animation 25" ;
VAL_ 592 MessageCounter_250 15 "Invalid" ;
VAL_ 592 PAT_SteerWhLengthPos 255 "Invalid";
VAL_ 592 PAT_SteerWhAnglePos 255 "Invalid";
VAL_ 592 PAT_EasyEntrySts 0 "Disable" 1 "Enable" ;
VAL_ 592 PAT_MotorFaultWarn 0 "No Fault" 1 "Fault" ;
VAL_ 592 PAT_StWMemoryLengthPos 255 "Invalid";
VAL_ 592 PAT_StWMemoryAnglePos 255 "Invalid";
VAL_ 578 POD_DCDC_WorkMode 0 "Init" 1 "Standby" 2 "Buck" 3 "Fault" 4 "sleep" ;
VAL_ 770 POD_DCDC_FaultLevel 0 "No Fault" 1 "Fault Level1" 2 "Fault Level2" 3 "Fault Level3" ;
VAL_ 770 POD_DCDC_OutputCurrentHighFault 0 "No Fault" 1 "Fault" ;
VAL_ 770 POD_DCDC_InputVoltHighFault 0 "No Fault" 1 "Fault" ;
VAL_ 770 POD_DCDC_InputVoltLowFault 0 "No Fault" 1 "Fault" ;
VAL_ 770 POD_DCDC_OutputVoltHighFault 0 "No Fault" 1 "Fault" ;
VAL_ 770 POD_DCDC_OutputVoltLowFault 0 "No Fault" 1 "Fault" ;
VAL_ 770 POD_DCDC_Outputopencircuiterror 0 "No Fault" 1 "Fault" ;
VAL_ 770 POD_DCDC_Side2Overtempfault 0 "No Fault" 1 "Fault" ;
VAL_ 770 POD_DCDC_OutCurSensorFault 0 "No Fault" 1 "Fault" ;
VAL_ 770 POD_DCDC_OutputTempSensorFault 0 "No Fault" 1 "Fault" ;
VAL_ 770 POD_DCDC_InternalFault 0 "No Fault" 1 "Fault" ;
VAL_ 581 POD_OBC_CCStatus 0 "Unconnected" 1 "Half-connected" 2 "1500 Ohm" 3 "680 Ohm" 4 "220 Ohm" 5 "100 Ohm" 6 "2000 Ohm" 7 "2700 Ohm" 8 "1000 Ohm" 9 "470 Ohm" 10 "invalid" ;
VAL_ 581 POD_OBC_CPStatus 0 "Unconnected" 1 "9V" 2 "9V PWM" 3 "6V" 4 "6V PWM" 5 "Fault" 6 "Reserve" 7 "Reserve" ;
VAL_ 581 POD_OBC_WorkMode 0 "Init" 1 "Standby" 2 "Reserve" 3 "Charging Mode" 4 "Pre-heating Mode" 5 "V2L Mode" 6 "Sleep" 7 "Fault" ;
VAL_ 581 POD_OBC_EMLockState 0 "Close" 1 "Open" 2 "Error" ;
VAL_ 581 POD_OBC_ChargCapacibility 0 "single-phase" 1 "Three-phase" 2 "Error" ;
VAL_ 581 POD_OBC_S2State 0 "Close" 1 "Open" 2 "Error" ;
VAL_ 787 POD_OBC_ACPortTempASensValid 0 "Damage" 1 "Short Circuit" 2 "Normal" ;
VAL_ 787 POD_OBC_ACPortTempBSensValid 0 "Damage" 1 "Short Circuit" 2 "Normal" ;
VAL_ 787 POD_OBC_ACPortTempAerror 0 "No Fault" 1 "Fault" ;
VAL_ 787 POD_OBC_ACPortTempBerror 0 "No Fault" 1 "Fault" ;
VAL_ 787 POD_OBC_FaultLevel 0 "No Fault" 1 "Level1" 2 "Level2" 3 "Level3" ;
VAL_ 787 POD_OBC_DCVoltHighFault 0 "No Fault" 1 "Fault" ;
VAL_ 787 POD_OBC_StartUpAllowed 0 "No Fault" 1 "Fault" ;
VAL_ 787 POD_OBC_CommunFault 0 "No Fault" 1 "Fault" ;
VAL_ 787 POD_OBC_DCCurHighFault 0 "No Fault" 1 "Fault" ;
VAL_ 787 POD_OBC_ACVoltHighFault 0 "No Fault" 1 "Fault" ;
VAL_ 787 POD_OBC_ACVoltLowFault 0 "No Fault" 1 "Fault" ;
VAL_ 787 POD_OBC_NlineStatus 0 "No Fault" 1 "Fault" ;
VAL_ 787 POD_OBC_OutputoverloadFault 0 "No Fault" 1 "Fault" ;
VAL_ 787 POD_OBC_InputFrequencyStatus 0 "No Fault" 1 "Fault" ;
VAL_ 787 POD_OBC_InputPhaseStatus 0 "No Fault" 1 "Fault" ;
VAL_ 787 POD_OBC_InputOverCurrentstatus_R 0 "No Fault" 1 "Fault" ;
VAL_ 787 POD_OBC_InputOverCurrentstatus_S 0 "No Fault" 1 "Fault" ;
VAL_ 787 POD_OBC_InputOverCurrentstatus_T 0 "No Fault" 1 "Fault" ;
VAL_ 787 POD_OBC_PFCUnderVoltageError 0 "No Fault" 1 "Fault" ;
VAL_ 787 POD_OBC_PFCOverVoltageError 0 "No Fault" 1 "Fault" ;
VAL_ 787 POD_OBC_OutputShortError 0 "No Fault" 1 "Fault" ;
VAL_ 787 POD_OBC_Side1Overtempfault 0 "No Fault" 1 "Fault" ;
VAL_ 787 POD_OBC_Side2Overtempfault 0 "No Fault" 1 "Fault" ;
VAL_ 787 POD_OBC_InternalFault 0 "No Fault" 1 "Fault" ;
VAL_ 787 POD_OBC_DCVoltLowFault 0 "No Fault" 1 "Fault" ;
VAL_ 787 POD_OBC_InputShortError 0 "No Fault" 1 "Fault" ;
VAL_ 787 POD_DCDC_CommunFault 0 "No Fault" 1 "Fault" ;
VAL_ 787 OBC_OutputIsolatedFault 0 "No Fault" 1 "Fault" ;
VAL_ 577 POD_DCPortInletTempBValid 0 "Damage" 1 "Short Circuit" 2 "normal" ;
VAL_ 577 POD_DCPortInletTempAValid 0 "Damage" 1 "Short Circuit" 2 "normal" ;
VAL_ 577 POD_DCPosRelayState 0 "Close" 1 "Open" 2 "Error" ;
VAL_ 577 POD_KL30Error 0 "No Fault" 1 "Fault" ;
VAL_ 577 POD_T15e_fault 0 "No Fault" 1 "Fault" ;
VAL_ 577 POD_CANBusoff 0 "No Fault" 1 "Fault" ;
VAL_ 577 POD_TempHighFault 0 "No Fault" 1 "Fault" ;
VAL_ 577 POD_TempSensor1Fault 0 "No Fault" 1 "Fault" ;
VAL_ 584 MessageCounter_248 15 "Invalid" ;
VAL_ 584 PRND_RNDbutton 0 "NO_TARGET" 1 "R" 2 "N" 3 "D" 4 "RESERVE" 5 "RESERVE" 6 "RESERVE" 7 "RESERVE" ;
VAL_ 584 PRND_Pbutton 0 "Not Pressed" 1 "Pressed" 2 "Held" 3 "reserved" ;
VAL_ 584 PRND_Pbutton_FaultSts 0 "No Fault" 1 "Fault" ;
VAL_ 584 PRND_RNDbutton_FaultSts 0 "No Fault" 1 "Fault" ;
VAL_ 661 MessageCounter_295 15 "Invalid" ;
VAL_ 661 SCU_L_DsSeatHeightPos 255 "Invalid";
VAL_ 661 SCU_L_DsSeatSlidePos 255 "Invalid";
VAL_ 661 SCU_L_EasyEntrySts 0 "Disable" 1 "Enable" ;
VAL_ 661 SCU_L_MotorFaultWarn 0 "No Fault" 1 "Fault" ;
VAL_ 661 SCU_L_DrSeatHeatSts 0 "OFF" 1 "LEVEL_1" 2 "LEVEL_2" 3 "LEVEL_3" 4 "Reserved" 5 "Reserved" 6 "Reserved" 7 "Reserved" ;
VAL_ 661 SCU_L_DsSeatBackPos 255 "Invalid";
VAL_ 661 SCU_L_WelcomeLevelSts 0 "Low" 1 "High" ;
VAL_ 661 SCU_L_SeatInitializationsts 0 "Seat not initialized" 1 "Seat initialization completed" 2 "Seat initialization failed" 3 "Seat initializing" ;
VAL_ 665 SCU_L_SeatMemoryHeightPos 255 "Invalid";
VAL_ 665 SCU_L_SeatMemorySlidePos 255 "Invalid";
VAL_ 665 SCU_L_SeatMemoryBackPos 255 "Invalid";
VAL_ 662 SCU_R_DsSeatHeightPos 255 "Invalid";
VAL_ 662 SCU_R_DsSeatSlidePos 255 "Invalid";
VAL_ 662 SCU_R_EasyEntrySts 0 "Disable" 1 "Enable" ;
VAL_ 662 SCU_R_PassSeatHeatSts 0 "OFF" 1 "LEVEL_1" 2 "LEVEL_2" 3 "LEVEL_3" 4 "Reserved" 5 "Reserved" 6 "Reserved" 7 "Reserved" ;
VAL_ 662 SCU_R_DsSeatBackPos 255 "Invalid";
VAL_ 662 SCU_R_WelcomeLevelSts 0 "Low" 1 "High" ;
VAL_ 662 SCU_R_SeatInitializationsts 0 "Seat not initialized" 1 "Seat initialization completed" 2 "Seat initialization failed" 3 "Seat initializing" ;
VAL_ 572 SGW_TimingChargeSwitchStatus 0 "Init" 1 "ON" 2 "OFF" ;
VAL_ 572 SGW_RemoteChrgFlapLockCtrlReq 0 "NO_REQUEST" 1 "UNLOCK" 2 "LOCK" 3 "Reserved" ;
VAL_ 572 SGW_RelockSet 0 "NO Request" 1 "INACTIVE" 2 "ACTIVE" 3 "Reserved" 4 "Reserved" 5 "Reserved" ;
VAL_ 572 SGW_RemoteActiveHorn 0 "No Request" 1 "Active" ;
VAL_ 572 SGW_ChargeFormSet 0 "Init" 1 "ChargeImmediately" 2 "Appointment charging" ;
VAL_ 572 SGW_TimingChargefrquency 0 "Init" 1 "once" 2 "everyday" ;
VAL_ 572 SGW_AppointChargeCmd 0 "Init" 1 "Charge ON" 2 "Charge OFF" ;
VAL_ 572 SGW_DschrgOnOffSet 0 "NO_COMMAND" 1 "OFF" 2 "ON" 3 "INVALID" ;
VAL_ 572 SGW_LockACPlug 0 "Init" 1 "Lock" 2 "Unlock" ;
VAL_ 572 SGW_NFCCloseDoorAndLockSet 0 "NO Request" 1 "Disable" 2 "Enable" ;
VAL_ 572 SGW_HoodlockSet 0 "No Request" 1 "Unlock" ;
VAL_ 573 SGW_DomeLampSet 0 "No request" 1 "Door open auto set" 2 "Door close auto set" 3 "Non-auto set" ;
VAL_ 573 SGW_AmbientLightOnOffSet 0 "NO Request" 1 "OFF" 2 "ON" 3 "Reserved" ;
VAL_ 573 SGW_AmbientLightBrightSet 0 "NO Request" 1 "LV1" 2 "LV2" 3 "LV3" 4 "LV4" 5 "LV5_NORMAL" 6 "LV6" 7 "LV7" 8 "LV8" 9 "LV9" 10 "LV10" ;
VAL_ 573 SGW_AmbientLightColourSet 0 "NO Request" 1 "Colour1" 2 "Colour2" 3 "Colour3" 4 "Colour4" 5 "Colour5" 6 "Colour6" 7 "Colour7" 8 "Colour8" 9 "Colour9" 10 "Colour10" 11 "Colour11" 12 "Colour12" 13 "Colour13" 14 "Colour14" 15 "Colour15" 16 "Colour16" 17 "Colour17" 18 "Colour18" 19 "Colour19" 20 "Colour20" 21 "Colour21" 22 "Colour22" 23 "Colour23" 24 "Colour24" 25 "Colour25" 26 "Colour26" 27 "Colour27" 28 "Colour28" 29 "Colour29" 30 "Colour30" 31 "Colour31" 32 "Colour32" 33 "Colour33" 34 "Colour34" 35 "Colour35" 36 "Colour36" 37 "Colour37" 38 "Colour38" 39 "Colour39" 40 "Colour40" 41 "Colour41" 42 "Colour42" 43 "Colour43" 44 "Colour44" 45 "Colour45" 46 "Colour46" 47 "Colour47" 48 "Colour48" 49 "Colour49" 50 "Colour50" 51 "Colour51" 52 "Colour52" 53 "Colour53" 54 "Colour54" 55 "Colour55" 56 "Colour56" 57 "Colour57" 58 "Colour58" 59 "Colour59" 60 "Colour60" 61 "Colour61" 62 "Colour62" 63 "Colour63" 64 "Colour64" 65 "Reserved" 66 "Reserved" 67 "Reserved" 68 "Reserved" 69 "Reserved" 70 "Reserved" 71 "Reserved" 72 "Reserved" 73 "Reserved" 74 "Reserved" 75 "Reserved" 76 "Reserved" 77 "Reserved" 78 "Reserved" 79 "Reserved" 80 "Reserved" 81 "Reserved" 82 "Reserved" 83 "Reserved" 84 "Reserved" 85 "Reserved" 86 "Reserved" 87 "Reserved" 88 "Reserved" 89 "Reserved" 90 "Reserved" 91 "Reserved" 92 "Reserved" 93 "Reserved" 94 "Reserved" 95 "Reserved" 96 "Reserved" 97 "Reserved" 98 "Reserved" 99 "Reserved" 100 "Reserved" 101 "Reserved" 102 "Reserved" 103 "Reserved" 104 "Reserved" 105 "Reserved" 106 "Reserved" 107 "Reserved" 108 "Reserved" 109 "Reserved" 110 "Reserved" 111 "Reserved" 112 "Reserved" 113 "Reserved" 114 "Reserved" 115 "Reserved" 116 "Reserved" 117 "Reserved" 118 "Reserved" 119 "Reserved" 120 "Reserved" 121 "Reserved" 122 "Reserved" 123 "Reserved" 124 "Reserved" 125 "Reserved" 126 "Reserved" 127 "Reserved" 128 "Reserved" 129 "Reserved" 130 "Reserved" 131 "Reserved" 132 "Reserved" 133 "Reserved" 134 "Reserved" 135 "Reserved" 136 "Reserved" 137 "Reserved" 138 "Reserved" 139 "Reserved" 140 "Reserved" 141 "Reserved" 142 "Reserved" 143 "Reserved" 144 "Reserved" 145 "Reserved" 146 "Reserved" 147 "Reserved" 148 "Reserved" 149 "Reserved" 150 "Reserved" 151 "Reserved" 152 "Reserved" 153 "Reserved" 154 "Reserved" 155 "Reserved" 156 "Reserved" 157 "Reserved" 158 "Reserved" 159 "Reserved" 160 "Reserved" 161 "Reserved" 162 "Reserved" 163 "Reserved" 164 "Reserved" 165 "Reserved" 166 "Reserved" 167 "Reserved" 168 "Reserved" 169 "Reserved" 170 "Reserved" 171 "Reserved" 172 "Reserved" 173 "Reserved" 174 "Reserved" 175 "Reserved" 176 "Reserved" 177 "Reserved" 178 "Reserved" 179 "Reserved" 180 "Reserved" 181 "Reserved" 182 "Reserved" 183 "Reserved" 184 "Reserved" 185 "Reserved" 186 "Reserved" 187 "Reserved" 188 "Reserved" 189 "Reserved" 190 "Reserved" 191 "Reserved" 192 "Reserved" 193 "Reserved" 194 "Reserved" 195 "Reserved" 196 "Reserved" 197 "Reserved" 198 "Reserved" 199 "Reserved" 200 "Reserved" 201 "Reserved" 202 "Reserved" 203 "Reserved" 204 "Reserved" 205 "Reserved" 206 "Reserved" 207 "Reserved" 208 "Reserved" 209 "Reserved" 210 "Reserved" 211 "Reserved" 212 "Reserved" 213 "Reserved" 214 "Reserved" 215 "Reserved" 216 "Reserved" 217 "Reserved" 218 "Reserved" 219 "Reserved" 220 "Reserved" 221 "Reserved" 222 "Reserved" 223 "Reserved" 224 "Reserved" 225 "Reserved" 226 "Reserved" 227 "Reserved" 228 "Reserved" 229 "Reserved" 230 "Reserved" 231 "Reserved" 232 "Reserved" 233 "Reserved" 234 "Reserved" 235 "Reserved" 236 "Reserved" 237 "Reserved" 238 "Reserved" 239 "Reserved" 240 "Reserved" 241 "Reserved" 242 "Reserved" 243 "Reserved" 244 "Reserved" 245 "Reserved" 246 "Reserved" 247 "Reserved" 248 "Reserved" 249 "Reserved" 250 "Reserved" 251 "Reserved" 252 "Reserved" 253 "Reserved" 254 "Reserved" 255 "Reserved" ;
VAL_ 573 SGW_OutsideUnlockModeSet 0 "NO_COMMAND" 1 "One door" 2 "All doors" 3 "INVALID" ;
VAL_ 573 SGW_ApproachingUnlockSet 0 "NO_COMMAND" 1 "ACTIVE" 2 "INACTIVE" 3 "INVALID" ;
VAL_ 573 SGW_AwayLockSet 0 "NO_COMMAND" 1 "ACTIVE" 2 "INACTIVE" 3 "INVALID" ;
VAL_ 573 SGW_AmbientLiAniSet 0 "No request" 1 "Animation 1" 2 "Animation 2" 3 "Animation 3" 4 "Animation 4" 5 "Animation 5" 6 "Animation 6" 7 "Animation 7" 8 "Animation 8" 9 "Animation 9" 10 "Animation 10" 11 "Animation 11" 12 "Animation 12" 13 "Animation 13" 14 "Animation 14" 15 "Animation 15" 17 "Animation 16" 18 "Animation 17" 19 "Animation 18" 20 "Animation 19" 21 "Animation 20" 22 "Animation 21" 23 "Animation 22" 24 "Animation 23" 25 "Animation 24" 26 "Animation 25" ;
VAL_ 573 SGW_WelLightshowAniSet 0 "No request" 1 "Animation 1" 2 "Animation 2" 3 "Animation 3" 4 "Animation 4" 5 "Animation 5" 6 "Animation 6" 7 "Animation 7" 8 "Animation 8" 9 "Animation 9" 10 "Animation 10" 11 "Animation 11" 12 "Animation 12" 13 "Animation 13" 14 "Animation 14" 15 "Animation 15" 17 "Animation 16" 18 "Animation 17" 19 "Animation 18" 20 "Animation 19" 21 "Animation 20" 22 "Animation 21" 23 "Animation 22" 24 "Animation 23" 25 "Animation 24" 26 "Animation 25" ;
VAL_ 573 SGW_FMHLightshowAniSet 0 "No request" 1 "Animation 1" 2 "Animation 2" 3 "Animation 3" 4 "Animation 4" 5 "Animation 5" 6 "Animation 6" 7 "Animation 7" 8 "Animation 8" 9 "Animation 9" 10 "Animation 10" 11 "Animation 11" 12 "Animation 12" 13 "Animation 13" 14 "Animation 14" 15 "Animation 15" 17 "Animation 16" 18 "Animation 17" 19 "Animation 18" 20 "Animation 19" 21 "Animation 20" 22 "Animation 21" 23 "Animation 22" 24 "Animation 23" 25 "Animation 24" 26 "Animation 25" ;
VAL_ 573 SGW_MFPColourSet 0 "NO Request" 1 "Colour1" 2 "Colour2" 3 "Colour3" 4 "Colour4" 5 "Colour5" 6 "Colour6" 7 "Colour7" 8 "Colour8" 9 "Colour9" 10 "Colour10" 11 "Colour11" 12 "Colour12" 13 "Colour13" 14 "Colour14" 15 "Colour15" 16 "Colour16" 17 "Colour17" 18 "Colour18" 19 "Colour19" 20 "Colour20" 21 "Colour21" 22 "Colour22" 23 "Colour23" 24 "Colour24" 25 "Colour25" 26 "Colour26" 27 "Colour27" 28 "Colour28" 29 "Colour29" 30 "Colour30" 31 "Colour31" 32 "Colour32" 33 "Colour33" 34 "Colour34" 35 "Colour35" 36 "Colour36" 37 "Colour37" 38 "Colour38" 39 "Colour39" 40 "Colour40" 41 "Colour41" 42 "Colour42" 43 "Colour43" 44 "Colour44" 45 "Colour45" 46 "Colour46" 47 "Colour47" 48 "Colour48" 49 "Colour49" 50 "Colour50" 51 "Colour51" 52 "Colour52" 53 "Colour53" 54 "Colour54" 55 "Colour55" 56 "Colour56" 57 "Colour57" 58 "Colour58" 59 "Colour59" 60 "Colour60" 61 "Colour61" 62 "Colour62" 63 "Colour63" 64 "Colour64" 65 "Reserved" 66 "Reserved" 67 "Reserved" 68 "Reserved" 69 "Reserved" 70 "Reserved" 71 "Reserved" 72 "Reserved" 73 "Reserved" 74 "Reserved" 75 "Reserved" 76 "Reserved" 77 "Reserved" 78 "Reserved" 79 "Reserved" 80 "Reserved" 81 "Reserved" 82 "Reserved" 83 "Reserved" 84 "Reserved" 85 "Reserved" 86 "Reserved" 87 "Reserved" 88 "Reserved" 89 "Reserved" 90 "Reserved" 91 "Reserved" 92 "Reserved" 93 "Reserved" 94 "Reserved" 95 "Reserved" 96 "Reserved" 97 "Reserved" 98 "Reserved" 99 "Reserved" 100 "Reserved" 101 "Reserved" 102 "Reserved" 103 "Reserved" 104 "Reserved" 105 "Reserved" 106 "Reserved" 107 "Reserved" 108 "Reserved" 109 "Reserved" 110 "Reserved" 111 "Reserved" 112 "Reserved" 113 "Reserved" 114 "Reserved" 115 "Reserved" 116 "Reserved" 117 "Reserved" 118 "Reserved" 119 "Reserved" 120 "Reserved" 121 "Reserved" 122 "Reserved" 123 "Reserved" 124 "Reserved" 125 "Reserved" 126 "Reserved" 127 "Reserved" 128 "Reserved" 129 "Reserved" 130 "Reserved" 131 "Reserved" 132 "Reserved" 133 "Reserved" 134 "Reserved" 135 "Reserved" 136 "Reserved" 137 "Reserved" 138 "Reserved" 139 "Reserved" 140 "Reserved" 141 "Reserved" 142 "Reserved" 143 "Reserved" 144 "Reserved" 145 "Reserved" 146 "Reserved" 147 "Reserved" 148 "Reserved" 149 "Reserved" 150 "Reserved" 151 "Reserved" 152 "Reserved" 153 "Reserved" 154 "Reserved" 155 "Reserved" 156 "Reserved" 157 "Reserved" 158 "Reserved" 159 "Reserved" 160 "Reserved" 161 "Reserved" 162 "Reserved" 163 "Reserved" 164 "Reserved" 165 "Reserved" 166 "Reserved" 167 "Reserved" 168 "Reserved" 169 "Reserved" 170 "Reserved" 171 "Reserved" 172 "Reserved" 173 "Reserved" 174 "Reserved" 175 "Reserved" 176 "Reserved" 177 "Reserved" 178 "Reserved" 179 "Reserved" 180 "Reserved" 181 "Reserved" 182 "Reserved" 183 "Reserved" 184 "Reserved" 185 "Reserved" 186 "Reserved" 187 "Reserved" 188 "Reserved" 189 "Reserved" 190 "Reserved" 191 "Reserved" 192 "Reserved" 193 "Reserved" 194 "Reserved" 195 "Reserved" 196 "Reserved" 197 "Reserved" 198 "Reserved" 199 "Reserved" 200 "Reserved" 201 "Reserved" 202 "Reserved" 203 "Reserved" 204 "Reserved" 205 "Reserved" 206 "Reserved" 207 "Reserved" 208 "Reserved" 209 "Reserved" 210 "Reserved" 211 "Reserved" 212 "Reserved" 213 "Reserved" 214 "Reserved" 215 "Reserved" 216 "Reserved" 217 "Reserved" 218 "Reserved" 219 "Reserved" 220 "Reserved" 221 "Reserved" 222 "Reserved" 223 "Reserved" 224 "Reserved" 225 "Reserved" 226 "Reserved" 227 "Reserved" 228 "Reserved" 229 "Reserved" 230 "Reserved" 231 "Reserved" 232 "Reserved" 233 "Reserved" 234 "Reserved" 235 "Reserved" 236 "Reserved" 237 "Reserved" 238 "Reserved" 239 "Reserved" 240 "Reserved" 241 "Reserved" 242 "Reserved" 243 "Reserved" 244 "Reserved" 245 "Reserved" 246 "Reserved" 247 "Reserved" 248 "Reserved" 249 "Reserved" 250 "Reserved" 251 "Reserved" 252 "Reserved" 253 "Reserved" 254 "Reserved" 255 "Reserved" ;
VAL_ 573 SGW_IMUWork_Sts 0 "Normal" 1 "Error" 2 "Reserved" 3 "Reserved" ;
VAL_ 573 SGW_PriorSoundSet 0 "NO Request" 1 "Disable" 2 "Enable" 3 "Reserved" ;
VAL_ 573 SGW_FrontKeepOpenSet 0 "NO Request" 1 "Disable" 2 "Enable" 3 "Reserved" ;
VAL_ 265 IVI_FLWinPosiCtlCmd 0 "No Request" 1 "Stop" 2 "0%" 3 "5%" 4 "10%" 5 "15%" 6 "20%" 7 "25%" 8 "30%" 9 "35%" 10 "40%" 11 "45%" 12 "50%" 13 "55%" 14 "60%" 15 "65%" 16 "70%" 17 "75%" 18 "80%" 19 "85%" 20 "90%" 21 "95%" 22 "100%" ;
VAL_ 265 IVI_FL_BTFrontRearReq 0 "Noactive" 1 "Front" 2 "Rear" ;
VAL_ 265 IVI_FrontDoorAngleSet 0 "No Request" 1 "Fully Open" 2 "Half Open" ;
VAL_ 265 IVI_RearDoorAngleSet 0 "No Request" 1 "Fully Open" 2 "Half Open" ;
VAL_ 265 IVI_FL_BTHeightMotorReq 0 "Noactive" 1 "Up" 2 "Down" ;
VAL_ 265 IVI_FRWinPosiCtlCmd 0 "No Request" 1 "Stop" 2 "0%" 3 "5%" 4 "10%" 5 "15%" 6 "20%" 7 "25%" 8 "30%" 9 "35%" 10 "40%" 11 "45%" 12 "50%" 13 "55%" 14 "60%" 15 "65%" 16 "70%" 17 "75%" 18 "80%" 19 "85%" 20 "90%" 21 "95%" 22 "100%" ;
VAL_ 265 IVI_RLWinPosiCtlCmd 0 "No Request" 1 "Stop" 2 "0%" 3 "5%" 4 "10%" 5 "15%" 6 "20%" 7 "25%" 8 "30%" 9 "35%" 10 "40%" 11 "45%" 12 "50%" 13 "55%" 14 "60%" 15 "65%" 16 "70%" 17 "75%" 18 "80%" 19 "85%" 20 "90%" 21 "95%" 22 "100%" ;
VAL_ 265 IVI_FL_BTBackrestMotorReq 0 "Noactive" 1 "Front" 2 "Rear" ;
VAL_ 265 IVI_RRWinPosiCtlCmd 0 "No Request" 1 "Stop" 2 "0%" 3 "5%" 4 "10%" 5 "15%" 6 "20%" 7 "25%" 8 "30%" 9 "35%" 10 "40%" 11 "45%" 12 "50%" 13 "55%" 14 "60%" 15 "65%" 16 "70%" 17 "75%" 18 "80%" 19 "85%" 20 "90%" 21 "95%" 22 "100%" ;
VAL_ 265 IVI_FLWinCtlCmd 0 "No Request" 1 "0%" 2 "5%" 3 "10%" 4 "15%" 5 "20%" 6 "25%" 7 "30%" 8 "35%" 9 "40%" 10 "45%" 11 "50%" 12 "55%" 13 "60%" 14 "65%" 15 "70%" 16 "75%" 17 "80%" 18 "85%" 19 "90%" 20 "95%" 21 "100%" ;
VAL_ 265 IVI_FRWinCtlCmd 0 "No Request" 1 "0%" 2 "5%" 3 "10%" 4 "15%" 5 "20%" 6 "25%" 7 "30%" 8 "35%" 9 "40%" 10 "45%" 11 "50%" 12 "55%" 13 "60%" 14 "65%" 15 "70%" 16 "75%" 17 "80%" 18 "85%" 19 "90%" 20 "95%" 21 "100%" ;
VAL_ 265 IVI_RLWinCtlCmd 0 "No Request" 1 "0%" 2 "5%" 3 "10%" 4 "15%" 5 "20%" 6 "25%" 7 "30%" 8 "35%" 9 "40%" 10 "45%" 11 "50%" 12 "55%" 13 "60%" 14 "65%" 15 "70%" 16 "75%" 17 "80%" 18 "85%" 19 "90%" 20 "95%" 21 "100%" ;
VAL_ 265 IVI_AlarmEnableSet 0 "No request" 1 "Disable" 2 "Enable" ;
VAL_ 265 IVI_RRWinCtlCmd 0 "No Request" 1 "0%" 2 "5%" 3 "10%" 4 "15%" 5 "20%" 6 "25%" 7 "30%" 8 "35%" 9 "40%" 10 "45%" 11 "50%" 12 "55%" 13 "60%" 14 "65%" 15 "70%" 16 "75%" 17 "80%" 18 "85%" 19 "90%" 20 "95%" 21 "100%" ;
VAL_ 265 IVI_AntiTheftReHornMode 0 "No Request" 1 "Normal Mode" 2 "Silence Mode" ;
VAL_ 266 IVI_AmbientLightRthythmLumiLvSet 0 "NO Request" 1 "LV1" 2 "LV2" 3 "LV3" 4 "LV4" 5 "LV5_NORMAL" 6 "LV6" 7 "LV7" 8 "LV8" 9 "LV9" 10 "LV10" ;
VAL_ 266 IVI_WiperServiceSet 0 "No request" 1 "OFF" 2 "ON" ;
VAL_ 266 IVI_AllDoorReq 0 "No request" 1 "Open" 2 "Closed" ;
VAL_ 266 IVI_FLDoorReq 0 "No request" 1 "Open" 2 "Closed" ;
VAL_ 266 IVI_FRDoorReq 0 "No request" 1 "Open" 2 "Closed" ;
VAL_ 266 IVI_RLDoorReq 0 "No request" 1 "Open" 2 "Closed" ;
VAL_ 266 IVI_RRDoorReq 0 "No request" 1 "Open" 2 "Closed" ;
VAL_ 266 IVI_LeftKeyReHornMode 0 "No Request" 1 "Normal Mode" 2 "Silence Mode" ;
VAL_ 266 IVI_LockDoorOpenReHornMode 0 "No Request" 1 "Normal Mode" 2 "Silence Mode" ;
VAL_ 266 IVI_BTAutoCloseWinFunSet 0 "No Request" 1 "No Active" 2 "Active" ;
VAL_ 266 IVI_AutoCloseWinFunSet 0 "No Request" 1 "No Active" 2 "Active" ;
VAL_ 565 SGW_AlarmEnableSet 0 "No request" 1 "Disable" 2 "Enable" ;
VAL_ 565 SGW_ALM_MusicFrequencySet 0 "NO Request" 1 "OFF" 2 "ON" 3 "Reserved" ;
VAL_ 565 SGW_RemoteHVCtrlReq 0 "NO_REQUEST" 1 "HV_ON" 2 "HV_OFF" ;
VAL_ 565 SGW_FL_BackrestMotorReq 0 "Noactive" 1 "Front" 2 "Rear" ;
VAL_ 565 SGW_DomeLampBrightSet 0 "No request" 1 "50%" 2 "100%" ;
VAL_ 565 SGW_FL_FrontRearReq 0 "Noactive" 1 "Front" 2 "Rear" ;
VAL_ 565 SGW_FL_HeightMotorReq 0 "Noactive" 1 "Up" 2 "Down" ;
VAL_ 565 SGW_WelLightshowOnOffSet 0 "NO Request" 1 "OFF" 2 "ON" 3 "Reserved" ;
VAL_ 565 SGW_WelLightshowTimeSet 0 "Invalid";
VAL_ 565 SGW_TaxiArrIllReq 0 "NO Request" 1 "OFF" 2 "ON" 3 "AUTO" ;
VAL_ 565 SGW_FollowMeHomeTimeSet 0 "Invalid";
VAL_ 565 SGW_TaxiArriveSts 0 "No request" 1 "Not arrived" 2 "Arrived" ;
VAL_ 565 SGW_BookingCarReq 0 "Booking" 1 "Cancel" 2 "No request" ;
VAL_ 565 SGW_HazardWarnReq 0 "No Request" 1 "Off" 2 "On" ;
VAL_ 565 SGW_FollowMeHomeSet 0 "No request" 1 "OFF" 2 "ON" 3 "Reserved" ;
VAL_ 688 SGW_TransferState 0 "Idle" 1 "Syncing" 2 "Transferring" 3 "Updating" 4 "Cancelling" 5 "RollingBackFailed" ;
VAL_ 688 SGW_DriverIdentitySts 0 "Owner mode" 1 "Valet mode" ;
VAL_ 688 SGW_MainModeSts 0 "Customer mode" 1 "Factory mode" 2 "Transport mode" ;
VAL_ 688 SGW_CustomerModeSts 0 "Operational mode" 1 "Demo（exhibition） mode" 2 "Service mode" 3 "OTA mode" ;
VAL_ 688 SGW_CareModeSts 0 "No care mode" 1 "Keep mode" 2 "Wash mode" ;
VAL_ 688 SGW_EnergySaveModeSts 0 "Normal mode" 1 "Energy save mode" ;
VAL_ 690 SGW_IMUWorkingSts 0 "No error" 1 "Error" ;
VAL_ 691 IVI_NFCCloseDoorAndLockSet 0 "No Request" 1 "Disable" 2 "Enable" ;
VAL_ 691 IVI_SelectLocationCommand 0 "No request" 1 "Driver seat cushion" 2 "Driver seat backrest" 3 "Passenger seat cushion" 4 "Passenger seat backrest" 5 "Driver exterior mirror" 6 "Passenger exterior mirror" 7 "HUD" 8 "Steering wheel" 9 "Reserved" 10 "Reserved" 11 "Reserved" 12 "Reserved" 13 "Reserved" 14 "Reserved" 15 "Reserved" ;
VAL_ 691 SGW_CelSigSts 0 "Inactive" 1 "Activity-100% signal strength" 2 "Activity-75% signal strength" 3 "Activity-50% signal strength" 4 "Activity-25% signal strength" 5 "Activity-low signal strength" 6 "Activity-total loss of signal" 7 "Cellular module failure" ;
VAL_ 691 SGW_CelSigType 0 "Invalid" 1 "Ultrafast" 2 "4G" 3 "3G" 4 "Low signal strength" 5 "Reserved" 6 "Reserved" 7 "Reserved" ;
VAL_ 691 SGW_WifiSigSts 0 "Inactive" 1 "Activity-low signal strength" 2 "Activity-medium signal strength" 3 "Activity-above average signal strength" 4 "Activity-high signal strength" 5 "Activity-no network" 6 "Wifi module failure" 7 "Reserved" ;
VAL_ 691 IVI_FrontWasherSpraySet 0 "No request" 1 "Request" ;
VAL_ 691 IVI_FR_FrontRearReq 0 "No request" 1 "Front" 2 "Rear" ;
VAL_ 691 IVI_FR_HeightMotorReq 0 "No request" 1 "Up" 2 "Down" ;
VAL_ 691 IVI_FR_BackrestMotorReq 0 "No request" 1 "Front" 2 "Rear" ;
VAL_ 691 IVI_FL_MirrorAdjust 0 "No Request" 1 "mirror around X axis Up" 2 "mirror around X axis Down" 3 "mirror around Y axis Left" 4 "mirror around Y axis Right" 5 "Reserved" 6 "Reserved" 7 "Reserved" ;
VAL_ 691 IVI_FR_MirrorAdjust 0 "No Request" 1 "Mirror around X axis Up" 2 "Mirror around X axis Down" 3 "Mirror around Y axis Left" 4 "Mirror around Y axis Right" 5 "Reserved" 6 "Reserved" 7 "Reserved" ;
VAL_ 268 SGW_PENFCAuthSt 0 "NotAuthed/uthFailed" 1 "AuthSuccessed" ;
VAL_ 268 SGW_GetNFCKeyCardsReq 0 "No Request" 1 "Get_All_KeyInfo" ;
VAL_ 268 SGW_NFCPairModeReq 0 "Disable" 1 "Enable" ;
VAL_ 571 SGW_TimingChargeEndhour 31 "Invalid";
VAL_ 571 SGW_TimingChargeEndminute 63 "Invalid";
VAL_ 571 SGW_TimingChargeStarthour 31 "Invalid";
VAL_ 571 SGW_TimingChargeStartminute 63 "Invalid";
VAL_ 692 IVI_MirrorInterfaceMode 0 "Normal" 1 "Tilt" ;
VAL_ 692 IVI_VrState 0 "Inactive" 1 "Active" ;
VAL_ 850 SGW_KeyLowBatWarning 0 "NO_WARNING" 1 "WARNING" ;
VAL_ 850 SGW_BLEPowerModeReq 0 "No Request" 1 "Request Power OFF" 2 "Request Power ON" 3 "Reserve" ;
VAL_ 850 SGW_BLESystemReadyReq 0 "No Request" 1 "Request Ready_Remote" 2 "Reserve" 3 "Reserve" ;
VAL_ 850 SGW_BLETailgateCtrlReq 0 "No Request" 1 "Unlock" 2 "Lock" 3 "Reserved" ;
VAL_ 850 SGW_BLELockCtrlReq 0 "No Request" 1 "Unlock" 2 "Lock" 3 "Reserved" ;
VAL_ 850 SGW_BLEChrgFlaplockCtrlReq 0 "No Request" 1 "Unlock" 2 "Lock" 3 "Reserved" ;
VAL_ 850 SGW_BLEFLLockCtrlReq 0 "No Request" 1 "Unlock" 2 "Lock" 3 "Reserved" ;
VAL_ 850 SGW_BLEFRLockCtrlReq 0 "No Request" 1 "Unlock" 2 "Lock" 3 "Reserved" ;
VAL_ 850 SGW_BLERLLockCtrlReq 0 "No Request" 1 "Unlock" 2 "Lock" 3 "Reserved" ;
VAL_ 850 SGW_BLERRLockCtrlReq 0 "No Request" 1 "Unlock" 2 "Lock" 3 "Reserved" ;
VAL_ 695 SGW_ParkingActiveReq 0 "No Request" 1 "Request RC On" 2 "Request RC Active" 3 "Request RC Quit" 4 "Suspend" 5 "Request RC forward" 6 "Request RC Backward" 7 "Reserved" ;
VAL_ 695 SGW_DeleteAllDKReq 0 "No Request" 1 "Request" ;
VAL_ 695 SGW_DKDeleteSlotIDReq 0 "No Request" 1 "DK 1" 2 "DK 2" 3 "DK 3" 4 "DK 4" 5 "DK 5" 6 "DK 6" 7 "DK 7" 8 "DK 8" ;
VAL_ 695 SGW_BlePairingSet 0 "No Request" 1 "Enable" 2 "Disable" 3 "Reserved" ;
VAL_ 695 SGW_DKAuthSts 0 "Invalid" 1 "Successful" 2 "Failed" ;
VAL_ 567 IVI_DomeLampBrightSet 0 "No request" 1 "50%" 2 "100%" 3 "Reserved" 4 "Reserved" 5 "Reserved" 6 "Reserved" 7 "Reserved" ;
VAL_ 567 IVI_HeadLampHeightSet 0 "No Request" 1 "Level 0" 2 "Level 1" 3 "Level 2" 4 "Level 3" 5 "Level 4" 6 "Reserved" 7 "Reserved" ;
VAL_ 567 IVI_DomeLampSet 0 "No request" 1 "Door open auto set" 2 "Door close auto set" 3 "Non-auto set" ;
VAL_ 567 IVI_PosnLmpSet 0 "NO Request" 1 "OFF" 2 "ON" 3 "Reserved" ;
VAL_ 567 IVI_DippedBeamSet 0 "NO Request" 1 "OFF" 2 "ON" 3 "Reserved" ;
VAL_ 567 IVI_AutoLmpSet 0 "NO Request" 1 "OFF" 2 "ON" 3 "Reserved" ;
VAL_ 567 IVI_FrntFogLmpSet 0 "NO Request" 1 "OFF" 2 "ON" 3 "Reserved" ;
VAL_ 567 IVI_RearFogLmpSet 0 "NO Request" 1 "OFF" 2 "ON" 3 "Reserved" ;
VAL_ 567 IVI_AutoLampSenReq 0 "no request" 1 "Early" 2 "Standard" 3 "Late" ;
VAL_ 567 IVI_WelcomeOnOffSet 0 "No request" 1 "OFF" 2 "ON" 3 "Reserved" ;
VAL_ 567 IVI_FRDomeLampSet 0 "No request" 1 "OFF" 2 "ON" ;
VAL_ 567 IVI_RRDomeLampSet 0 "No request" 1 "OFF" 2 "ON" ;
VAL_ 567 IVI_FollowMeHomeSet 0 "No request" 1 "OFF" 2 "ON" 3 "Reserved" ;
VAL_ 567 IVI_CornerLampSet 0 "NO Request" 1 "OFF" 2 "ON" 3 "Reserved" ;
VAL_ 567 IVI_PassWelcomeOnOffSet 0 "No request" 1 "OFF" 2 "ON" 3 "Reserved" ;
VAL_ 567 IVI_MainBeamSet 0 "NO Request" 1 "OFF" 2 "ON" 3 "Reserved" ;
VAL_ 568 IVI_RearCameraWashingSet 0 "No Request" 1 "Request" ;
VAL_ 568 IVI_ApproachingUnlockSet 0 "No Request" 1 "ACTIVE" 2 "INACTIVE" 3 "Reserved" ;
VAL_ 568 IVI_CentralLockSet 0 "No Request" 1 "UNLOCK" 2 "LOCK" 3 "Reserved" ;
VAL_ 568 IVI_AwayLockSet 0 "No Request" 1 "ACTIVE" 2 "INACTIVE" 3 "Reserved" ;
VAL_ 568 IVI_LeftChdLockSet 0 "No request" 1 "UnLock" 2 "Lock" ;
VAL_ 568 IVI_RightChdLockSet 0 "No request" 1 "UnLock" 2 "Lock" ;
VAL_ 568 IVI_OutsideUnlockModeSet 0 "No Request" 1 "One door" 2 "All doors" 3 "Reserved" ;
VAL_ 568 IVI_TailgateLogicLockSet 0 "No Request" 1 "Unlock" 2 "Lock" 3 "Reserved" ;
VAL_ 568 IVI_LowVoltPowerCtrl 0 "NO Request" 1 "POWER_ON_REQUEST" 2 "RESERVED" 3 "RESERVED" ;
VAL_ 568 IVI_RelockSet 0 "NO Request" 1 "INACTIVE" 2 "ACTIVE" 3 "Reserved" 4 "Reserved" 5 "Reserved" ;
VAL_ 568 IVI_BT_LeftChdLockCtrlReq 0 "No request" 1 "Active" 2 "Deactive" ;
VAL_ 568 IVI_BT_RightChdLockCtrlReq 0 "No request" 1 "Active" 2 "Deactive" ;
VAL_ 568 IVI_GearTimesSet 0 "No request" 1 "0" 2 "1" 3 "2" 4 "3" 5 "4" 6 "5" ;
VAL_ 569 SGW_RoleAccessSts 0 "Driving allowed" 1 "Driving NOT allowed" ;
VAL_ 569 SGW_FaceIDAuthenticationSuccess 0 "AuthenticationFailed" 1 "AuthenticationSuccess" ;
VAL_ 569 SGW_ImmobilizingEnable 0 "No request" 1 "Disable" 2 "Enable" ;
VAL_ 851 IVI_WelLightshowOnOffSet 0 "NO Request" 1 "OFF" 2 "ON" 3 "Reserved" ;
VAL_ 851 IVI_FMHLightshowAniSet 0 "No request" 1 "Animation 1" 2 "Animation 2" 3 "Animation 3" 4 "Animation 4" 5 "Animation 5" 6 "Animation 6" 7 "Animation 7" 8 "Animation 8" 9 "Animation 9" 10 "Animation 10" 11 "Animation 11" 12 "Animation 12" 13 "Animation 13" 14 "Animation 14" 15 "Animation 15" 17 "Animation 16" 18 "Animation 17" 19 "Animation 18" 20 "Animation 19" 21 "Animation 20" 22 "Animation 21" 23 "Animation 22" 24 "Animation 23" 25 "Animation 24" 26 "Animation 25" ;
VAL_ 851 IVI_CallAmbientLReq 0 "NO Request" 1 "OFF" 2 "ON" ;
VAL_ 851 IVI_AmbientLiAniSet 0 "No request" 1 "Animation 1" 2 "Animation 2" 3 "Animation 3" 4 "Animation 4" 5 "Animation 5" 6 "Animation 6" 7 "Animation 7" 8 "Animation 8" 9 "Animation 9" 10 "Animation 10" 11 "Animation 11" 12 "Animation 12" 13 "Animation 13" 14 "Animation 14" 15 "Animation 15" 17 "Animation 16" 18 "Animation 17" 19 "Animation 18" 20 "Animation 19" 21 "Animation 20" 22 "Animation 21" 23 "Animation 22" 24 "Animation 23" 25 "Animation 24" 26 "Animation 25" ;
VAL_ 851 IVI_ALM_MusicFrequencySet 0 "NO Request" 1 "OFF" 2 "ON" 3 "Reserved" ;
VAL_ 851 IVI_AmbientLightOnOffSet 0 "NO Request" 1 "OFF" 2 "ON" 3 "Reserved" ;
VAL_ 851 IVI_AmbientLightColorSet 0 "NO Request" 1 "Colour1" 2 "Colour2" 3 "Colour3" 4 "Colour4" 5 "Colour5" 6 "Colour6" 7 "Colour7" 8 "Colour8" 9 "Colour9" 10 "Colour10" 11 "Colour11" 12 "Colour12" 13 "Colour13" 14 "Colour14" 15 "Colour15" 16 "Colour16" 17 "Colour17" 18 "Colour18" 19 "Colour19" 20 "Colour20" 21 "Colour21" 22 "Colour22" 23 "Colour23" 24 "Colour24" 25 "Colour25" 26 "Colour26" 27 "Colour27" 28 "Colour28" 29 "Colour29" 30 "Colour30" 31 "Colour31" 32 "Colour32" 33 "Colour33" 34 "Colour34" 35 "Colour35" 36 "Colour36" 37 "Colour37" 38 "Colour38" 39 "Colour39" 40 "Colour40" 41 "Colour41" 42 "Colour42" 43 "Colour43" 44 "Colour44" 45 "Colour45" 46 "Colour46" 47 "Colour47" 48 "Colour48" 49 "Colour49" 50 "Colour50" 51 "Colour51" 52 "Colour52" 53 "Colour53" 54 "Colour54" 55 "Colour55" 56 "Colour56" 57 "Colour57" 58 "Colour58" 59 "Colour59" 60 "Colour60" 61 "Colour61" 62 "Colour62" 63 "Colour63" 64 "Colour64" 65 "Reserved" 66 "Reserved" 67 "Reserved" 68 "Reserved" 69 "Reserved" 70 "Reserved" 71 "Reserved" 72 "Reserved" 73 "Reserved" 74 "Reserved" 75 "Reserved" 76 "Reserved" 77 "Reserved" 78 "Reserved" 79 "Reserved" 80 "Reserved" 81 "Reserved" 82 "Reserved" 83 "Reserved" 84 "Reserved" 85 "Reserved" 86 "Reserved" 87 "Reserved" 88 "Reserved" 89 "Reserved" 90 "Reserved" 91 "Reserved" 92 "Reserved" 93 "Reserved" 94 "Reserved" 95 "Reserved" 96 "Reserved" 97 "Reserved" 98 "Reserved" 99 "Reserved" 100 "Reserved" 101 "Reserved" 102 "Reserved" 103 "Reserved" 104 "Reserved" 105 "Reserved" 106 "Reserved" 107 "Reserved" 108 "Reserved" 109 "Reserved" 110 "Reserved" 111 "Reserved" 112 "Reserved" 113 "Reserved" 114 "Reserved" 115 "Reserved" 116 "Reserved" 117 "Reserved" 118 "Reserved" 119 "Reserved" 120 "Reserved" 121 "Reserved" 122 "Reserved" 123 "Reserved" 124 "Reserved" 125 "Reserved" 126 "Reserved" 127 "Reserved" 128 "Reserved" 129 "Reserved" 130 "Reserved" 131 "Reserved" 132 "Reserved" 133 "Reserved" 134 "Reserved" 135 "Reserved" 136 "Reserved" 137 "Reserved" 138 "Reserved" 139 "Reserved" 140 "Reserved" 141 "Reserved" 142 "Reserved" 143 "Reserved" 144 "Reserved" 145 "Reserved" 146 "Reserved" 147 "Reserved" 148 "Reserved" 149 "Reserved" 150 "Reserved" 151 "Reserved" 152 "Reserved" 153 "Reserved" 154 "Reserved" 155 "Reserved" 156 "Reserved" 157 "Reserved" 158 "Reserved" 159 "Reserved" 160 "Reserved" 161 "Reserved" 162 "Reserved" 163 "Reserved" 164 "Reserved" 165 "Reserved" 166 "Reserved" 167 "Reserved" 168 "Reserved" 169 "Reserved" 170 "Reserved" 171 "Reserved" 172 "Reserved" 173 "Reserved" 174 "Reserved" 175 "Reserved" 176 "Reserved" 177 "Reserved" 178 "Reserved" 179 "Reserved" 180 "Reserved" 181 "Reserved" 182 "Reserved" 183 "Reserved" 184 "Reserved" 185 "Reserved" 186 "Reserved" 187 "Reserved" 188 "Reserved" 189 "Reserved" 190 "Reserved" 191 "Reserved" 192 "Reserved" 193 "Reserved" 194 "Reserved" 195 "Reserved" 196 "Reserved" 197 "Reserved" 198 "Reserved" 199 "Reserved" 200 "Reserved" 201 "Reserved" 202 "Reserved" 203 "Reserved" 204 "Reserved" 205 "Reserved" 206 "Reserved" 207 "Reserved" 208 "Reserved" 209 "Reserved" 210 "Reserved" 211 "Reserved" 212 "Reserved" 213 "Reserved" 214 "Reserved" 215 "Reserved" 216 "Reserved" 217 "Reserved" 218 "Reserved" 219 "Reserved" 220 "Reserved" 221 "Reserved" 222 "Reserved" 223 "Reserved" 224 "Reserved" 225 "Reserved" 226 "Reserved" 227 "Reserved" 228 "Reserved" 229 "Reserved" 230 "Reserved" 231 "Reserved" 232 "Reserved" 233 "Reserved" 234 "Reserved" 235 "Reserved" 236 "Reserved" 237 "Reserved" 238 "Reserved" 239 "Reserved" 240 "Reserved" 241 "Reserved" 242 "Reserved" 243 "Reserved" 244 "Reserved" 245 "Reserved" 246 "Reserved" 247 "Reserved" 248 "Reserved" 249 "Reserved" 250 "Reserved" 251 "Reserved" 252 "Reserved" 253 "Reserved" 254 "Reserved" 255 "Reserved" ;
VAL_ 851 IVI_WelLightshowAniSet 0 "No request" 1 "Animation 1" 2 "Animation 2" 3 "Animation 3" 4 "Animation 4" 5 "Animation 5" 6 "Animation 6" 7 "Animation 7" 8 "Animation 8" 9 "Animation 9" 10 "Animation 10" 11 "Animation 11" 12 "Animation 12" 13 "Animation 13" 14 "Animation 14" 15 "Animation 15" 17 "Animation 16" 18 "Animation 17" 19 "Animation 18" 20 "Animation 19" 21 "Animation 20" 22 "Animation 21" 23 "Animation 22" 24 "Animation 23" 25 "Animation 24" 26 "Animation 25" ;
VAL_ 851 IVI_TaxiArrIllReq 0 "NO Request" 1 "OFF" 2 "ON" 3 "AUTO" ;
VAL_ 851 IVI_WelLightshowTimeSet 0 "Invalid";
VAL_ 851 IVI_FollowMeHomeTimeSet 0 "Invalid";
VAL_ 851 IVI_TaxiArriveSts 0 "No request" 1 "Not arrived" 2 "Arrived" 3 "Manual off" ;
VAL_ 570 IVI_RearWindHeating 0 "NO Request" 1 "OFF" 2 "ON" 3 "Reserved" ;
VAL_ 570 IVI_PowerOffDisplay 0 "No Request" 1 "Confirm" 2 "Cancel" 3 "Exit" ;
VAL_ 570 IVI_HoodlockSet 0 "No Request" 1 "Unlock" 2 "Lock" 3 "Reserved" ;
VAL_ 570 IVI_SteerWhHeatOnOffSet 0 "No Request" 1 "OFF" 2 "ON" 3 "Reserved" ;
VAL_ 570 IVI_RearMirrorHeating 0 "NO Request" 1 "OFF" 2 "ON" 3 "Reserved" ;
VAL_ 570 IVI_FrontWiperSwitch 0 "No request" 1 "OFF" 2 "AUTO" 3 "Low speed" 4 "High speed" 5 "Intermittent" ;
VAL_ 570 IVI_L_RearSeatHeatSet 0 "No Request" 1 "OFF" 2 "ON" 3 "Reserved" ;
VAL_ 570 IVI_R_RearSeatHeatSet 0 "No Request" 1 "OFF" 2 "ON" 3 "Reserved" ;
VAL_ 570 IVI_FrontWindHeatingSet 0 "NO Request" 1 "OFF" 2 "ON" 3 "Reserved" ;
VAL_ 570 IVI_ChrgFlapLockSet 0 "No Request" 1 "UNLOCK" 2 "LOCK" 3 "Reserved" ;
VAL_ 570 IVI_DIMONOFFCommand 0 "No request" 1 "Off" 2 "On" 3 "Reserved" ;
VAL_ 570 IVI_BacklightadjustSet 0 "No Request" 1 "0%" 2 "10%" 3 "16%" 4 "22%" 5 "28%" 6 "34%" 7 "40%" 8 "50%" 9 "70%" 10 "80%" 11 "85%" 12 "90%" 13 "100%" ;
VAL_ 570 IVI_AmbientLightBrightSet 0 "NO Request" 1 "LV1" 2 "LV2" 3 "LV3" 4 "LV4" 5 "LV5_NORMAL" 6 "LV6" 7 "LV7" 8 "LV8" 9 "LV9" 10 "LV10" ;
